VERSION "dbc-export 1 2026.26.6.5"

NS_ :

BS_:

BU_: APP APS BMS CC CMP CMPD CP DAS DI DIF DIR EPBL EPBR EVSE FC GTW HCML HCMR HVP ICR PCS PCS2 PLG PM PMF PMR PTC SCCM SCM SCS SDCR TAS UMC V2G VC VCBATT VCBATT0 VCBATT1 VCBATT2 VCFRONT VCFRONT1 VCFRONT2 VCLEFT VCRIGHT VCSEC

BO_ 852 TAS_alertMatrix: 8 TAS
 SG_ TAS_matrixIndex M : 0|4@1+ (1,0) [0|15] "" Vector__XXX
 SG_ TAS_a001_WatchdogReset m0 : 4|1@1+ (1,0) [0|1] "" Vector__XXX
 SG_ TAS_a002_PowerLossReset m0 : 5|1@1+ (1,0) [0|1] "" Vector__XXX
 SG_ TAS_a003_SWAssertion m0 : 6|1@1+ (1,0) [0|1] "" Vector__XXX
 SG_ TAS_a012_CPUReset m0 : 15|1@1+ (1,0) [0|1] "" Vector__XXX
 SG_ TAS_a015_NVMMError m0 : 18|1@1+ (1,0) [0|1] "" Vector__XXX
 SG_ TAS_a016_NVMMRecordError m0 : 19|1@1+ (1,0) [0|1] "" Vector__XXX
 SG_ TAS_a021_TaskSchedulerError m0 : 24|1@1+ (1,0) [0|1] "" Vector__XXX
 SG_ TAS_a022_TaskInitError m0 : 25|1@1+ (1,0) [0|1] "" Vector__XXX
 SG_ TAS_a023_rtosResetRequested m0 : 26|1@1+ (1,0) [0|1] "" Vector__XXX
 SG_ TAS_a024_prefetchAbort m0 : 27|1@1+ (1,0) [0|1] "" Vector__XXX
 SG_ TAS_a025_CrashEvent m0 : 28|1@1+ (1,0) [0|1] "" Vector__XXX
 SG_ TAS_a030_PWMerrorFL m0 : 33|1@1+ (1,0) [0|1] "" Vector__XXX
 SG_ TAS_a031_PWMerrorFR m0 : 34|1@1+ (1,0) [0|1] "" Vector__XXX
 SG_ TAS_a032_PWMerrorRL m0 : 35|1@1+ (1,0) [0|1] "" Vector__XXX
 SG_ TAS_a033_PWMerrorRR m0 : 36|1@1+ (1,0) [0|1] "" Vector__XXX
 SG_ TAS_a034_PWMshortFL m0 : 37|1@1+ (1,0) [0|1] "" Vector__XXX
 SG_ TAS_a035_PWMshortFR m0 : 38|1@1+ (1,0) [0|1] "" Vector__XXX
 SG_ TAS_a036_PWMshortRL m0 : 39|1@1+ (1,0) [0|1] "" Vector__XXX
 SG_ TAS_a037_PWMshortRR m0 : 40|1@1+ (1,0) [0|1] "" Vector__XXX
 SG_ TAS_a038_PWMopenFL m0 : 41|1@1+ (1,0) [0|1] "" Vector__XXX
 SG_ TAS_a039_PWMopenFR m0 : 42|1@1+ (1,0) [0|1] "" Vector__XXX
 SG_ TAS_a040_PWMopenRL m0 : 43|1@1+ (1,0) [0|1] "" Vector__XXX
 SG_ TAS_a041_PWMopenRR m0 : 44|1@1+ (1,0) [0|1] "" Vector__XXX
 SG_ TAS_a043_Task1msError m0 : 46|1@1+ (1,0) [0|1] "" Vector__XXX
 SG_ TAS_a044_Task10msError m0 : 47|1@1+ (1,0) [0|1] "" Vector__XXX
 SG_ TAS_a045_Task100msError m0 : 48|1@1+ (1,0) [0|1] "" Vector__XXX
 SG_ TAS_a046_Task1000msError m0 : 49|1@1+ (1,0) [0|1] "" Vector__XXX
 SG_ TAS_a061_XCPConnected m1 : 4|1@1+ (1,0) [0|1] "" Vector__XXX
 SG_ TAS_a062_XCPWasConnected m1 : 5|1@1+ (1,0) [0|1] "" Vector__XXX
 SG_ TAS_a063_abortFault m1 : 6|1@1+ (1,0) [0|1] "" Vector__XXX
 SG_ TAS_a064_abortFaultExt m1 : 7|1@1+ (1,0) [0|1] "" Vector__XXX
 SG_ TAS_a065_ahbWriteFault m1 : 8|1@1+ (1,0) [0|1] "" Vector__XXX
 SG_ TAS_a066_undefinedInstructionAbo m1 : 9|1@1+ (1,0) [0|1] "" Vector__XXX
 SG_ TAS_a067_reservedHandlerAbort m1 : 10|1@1+ (1,0) [0|1] "" Vector__XXX
 SG_ TAS_a070_underVoltage12V m1 : 13|1@1+ (1,0) [0|1] "" Vector__XXX
 SG_ TAS_a071_overVoltage12V m1 : 14|1@1+ (1,0) [0|1] "" Vector__XXX
 SG_ TAS_a072_shortCircuit5VOnBoard m1 : 15|1@1+ (1,0) [0|1] "" Vector__XXX
 SG_ TAS_a073_underVoltage5VOnBoard m1 : 16|1@1+ (1,0) [0|1] "" Vector__XXX
 SG_ TAS_a074_shortCircuit5VOffBoard m1 : 17|1@1+ (1,0) [0|1] "" Vector__XXX
 SG_ TAS_a075_underVoltage5VOffBoard m1 : 18|1@1+ (1,0) [0|1] "" Vector__XXX
 SG_ TAS_a076_overVoltage5VOffBoard m1 : 19|1@1+ (1,0) [0|1] "" Vector__XXX
 SG_ TAS_a077_pressureSigVTooLow m1 : 20|1@1+ (1,0) [0|1] "" Vector__XXX
 SG_ TAS_a078_pressureSigVTooHigh m1 : 21|1@1+ (1,0) [0|1] "" Vector__XXX
 SG_ TAS_a080_shortCircuit5VHeight m1 : 23|1@1+ (1,0) [0|1] "" Vector__XXX
 SG_ TAS_a081_underVoltage5VHeight m1 : 24|1@1+ (1,0) [0|1] "" Vector__XXX
 SG_ TAS_a082_overVoltage5VHeight m1 : 25|1@1+ (1,0) [0|1] "" Vector__XXX
 SG_ TAS_a083_shortCircuit5VAnalog m1 : 26|1@1+ (1,0) [0|1] "" Vector__XXX
 SG_ TAS_a084_underVoltage5VAnalog m1 : 27|1@1+ (1,0) [0|1] "" Vector__XXX
 SG_ TAS_a085_overVoltage5VAnalog m1 : 28|1@1+ (1,0) [0|1] "" Vector__XXX
 SG_ TAS_a086_underVoltage12VSwtchd m1 : 29|1@1+ (1,0) [0|1] "" Vector__XXX
 SG_ TAS_a087_overVoltage12VSwtchd m1 : 30|1@1+ (1,0) [0|1] "" Vector__XXX
 SG_ TAS_a093_OTPError m1 : 36|1@1+ (1,0) [0|1] "" Vector__XXX
 SG_ TAS_a098_VCFRONT_MIA m1 : 41|1@1+ (1,0) [0|1] "" Vector__XXX
 SG_ TAS_a099_UI_MIA m1 : 42|1@1+ (1,0) [0|1] "" Vector__XXX
 SG_ TAS_a100_RCM_MIA m1 : 43|1@1+ (1,0) [0|1] "" Vector__XXX
 SG_ TAS_a101_ESP_MIA m1 : 44|1@1+ (1,0) [0|1] "" Vector__XXX
 SG_ TAS_a102_DI_MIA m1 : 45|1@1+ (1,0) [0|1] "" Vector__XXX
 SG_ TAS_a103_GTW_MIA m1 : 46|1@1+ (1,0) [0|1] "" Vector__XXX
 SG_ TAS_a105_ECUDebugMode m1 : 48|1@1+ (1,0) [0|1] "" Vector__XXX
 SG_ TAS_a106_HighCPULoad m1 : 49|1@1+ (1,0) [0|1] "" Vector__XXX
 SG_ TAS_a107_HighStackUsage m1 : 50|1@1+ (1,0) [0|1] "" Vector__XXX
 SG_ TAS_a150_accelAvgImplausible_FL_ m2 : 33|1@1+ (1,0) [0|1] "" Vector__XXX
 SG_ TAS_a151_accelAvgImplausible_FL_ m2 : 34|1@1+ (1,0) [0|1] "" Vector__XXX
 SG_ TAS_a152_accelAvgImplausible_FL_ m2 : 35|1@1+ (1,0) [0|1] "" Vector__XXX
 SG_ TAS_a153_accelAvgImplausible_FR_ m2 : 36|1@1+ (1,0) [0|1] "" Vector__XXX
 SG_ TAS_a154_accelAvgImplausible_FR_ m2 : 37|1@1+ (1,0) [0|1] "" Vector__XXX
 SG_ TAS_a155_accelAvgImplausible_FR_ m2 : 38|1@1+ (1,0) [0|1] "" Vector__XXX
 SG_ TAS_a156_accelAvgImplausible_RL_ m2 : 39|1@1+ (1,0) [0|1] "" Vector__XXX
 SG_ TAS_a157_accelAvgImplausible_RL_ m2 : 40|1@1+ (1,0) [0|1] "" Vector__XXX
 SG_ TAS_a158_accelAvgImplausible_RL_ m2 : 41|1@1+ (1,0) [0|1] "" Vector__XXX
 SG_ TAS_a159_accelAvgImplausible_RR_ m2 : 42|1@1+ (1,0) [0|1] "" Vector__XXX
 SG_ TAS_a160_accelAvgImplausible_RR_ m2 : 43|1@1+ (1,0) [0|1] "" Vector__XXX
 SG_ TAS_a161_accelAvgImplausible_RR_ m2 : 44|1@1+ (1,0) [0|1] "" Vector__XXX
 SG_ TAS_a164_damperSolenoidMismatch m2 : 47|1@1+ (1,0) [0|1] "" Vector__XXX
 SG_ TAS_a165_damperValveCompFL m2 : 48|1@1+ (1,0) [0|1] "" Vector__XXX
 SG_ TAS_a166_damperValveRbndFL m2 : 49|1@1+ (1,0) [0|1] "" Vector__XXX
 SG_ TAS_a167_damperValveCompFR m2 : 50|1@1+ (1,0) [0|1] "" Vector__XXX
 SG_ TAS_a168_damperValveRbndFR m2 : 51|1@1+ (1,0) [0|1] "" Vector__XXX
 SG_ TAS_a169_damperValveCompRL m2 : 52|1@1+ (1,0) [0|1] "" Vector__XXX
 SG_ TAS_a170_damperValveRbndRL m2 : 53|1@1+ (1,0) [0|1] "" Vector__XXX
 SG_ TAS_a171_damperValveCompRR m2 : 54|1@1+ (1,0) [0|1] "" Vector__XXX
 SG_ TAS_a172_damperValveRbndRR m2 : 55|1@1+ (1,0) [0|1] "" Vector__XXX
 SG_ TAS_a173_staticLeakDetectFL m2 : 56|1@1+ (1,0) [0|1] "" Vector__XXX
 SG_ TAS_a174_staticLeakDetectFR m2 : 57|1@1+ (1,0) [0|1] "" Vector__XXX
 SG_ TAS_a175_staticLeakDetectRL m2 : 58|1@1+ (1,0) [0|1] "" Vector__XXX
 SG_ TAS_a176_staticLeakDetectRR m2 : 59|1@1+ (1,0) [0|1] "" Vector__XXX
 SG_ TAS_a190_a2bFrontAxleFault m3 : 13|1@1+ (1,0) [0|1] "" Vector__XXX
 SG_ TAS_a191_a2bRearAxleFault m3 : 14|1@1+ (1,0) [0|1] "" Vector__XXX
 SG_ TAS_a192_rideHeightObserverDiver m3 : 15|1@1+ (1,0) [0|1] "" Vector__XXX
 SG_ TAS_a193_EPAS3P_MIA m3 : 16|1@1+ (1,0) [0|1] "" Vector__XXX
 SG_ TAS_a194_a2bFrontAxleDataError m3 : 17|1@1+ (1,0) [0|1] "" Vector__XXX
 SG_ TAS_a195_a2bRearAxleDataError m3 : 18|1@1+ (1,0) [0|1] "" Vector__XXX
 SG_ TAS_a196_adaptiveDampingUsingDSP m3 : 19|1@1+ (1,0) [0|1] "" Vector__XXX
 SG_ TAS_a197_invalidAdaptiveModeRequ m3 : 20|1@1+ (1,0) [0|1] "" Vector__XXX
 SG_ TAS_a198_a2bFrontAxleExtendedDis m3 : 21|1@1+ (1,0) [0|1] "" Vector__XXX
 SG_ TAS_a199_a2bRearAxleExtendedDisc m3 : 22|1@1+ (1,0) [0|1] "" Vector__XXX
 SG_ TAS_a200_jackModeActive m3 : 23|1@1+ (1,0) [0|1] "" Vector__XXX
 SG_ TAS_a201_low12VBattery m3 : 24|1@1+ (1,0) [0|1] "" Vector__XXX
 SG_ TAS_a210_outOfRangeCalibration m3 : 33|1@1+ (1,0) [0|1] "" Vector__XXX
 SG_ TAS_a211_noRideHeightCalib m3 : 34|1@1+ (1,0) [0|1] "" Vector__XXX
 SG_ TAS_a213_yellowWarningLamp m3 : 36|1@1+ (1,0) [0|1] "" Vector__XXX
 SG_ TAS_a214_redWarningLamp m3 : 37|1@1+ (1,0) [0|1] "" Vector__XXX
 SG_ TAS_a215_limpHomeMode10 m3 : 38|1@1+ (1,0) [0|1] "" Vector__XXX
 SG_ TAS_a216_limpHomeMode20 m3 : 39|1@1+ (1,0) [0|1] "" Vector__XXX
 SG_ TAS_a217_limpHomeMode30 m3 : 40|1@1+ (1,0) [0|1] "" Vector__XXX
 SG_ TAS_a218_limpHomeMode40 m3 : 41|1@1+ (1,0) [0|1] "" Vector__XXX
 SG_ TAS_a220_exhaustGalleryFault m3 : 43|1@1+ (1,0) [0|1] "" Vector__XXX
 SG_ TAS_a221_valveLeakDetected m3 : 44|1@1+ (1,0) [0|1] "" Vector__XXX
 SG_ TAS_a222_compressorPrefillFault m3 : 45|1@1+ (1,0) [0|1] "" Vector__XXX
 SG_ TAS_a223_blockedAirline m3 : 46|1@1+ (1,0) [0|1] "" Vector__XXX
 SG_ TAS_a224_openAirline m3 : 47|1@1+ (1,0) [0|1] "" Vector__XXX
 SG_ TAS_a225_galleryPressureTooHigh m3 : 48|1@1+ (1,0) [0|1] "" Vector__XXX
 SG_ TAS_a226_PWMfastDetectFL m3 : 49|1@1+ (1,0) [0|1] "" Vector__XXX
 SG_ TAS_a227_PWMfastDetectFR m3 : 50|1@1+ (1,0) [0|1] "" Vector__XXX
 SG_ TAS_a228_PWMfastDetectRL m3 : 51|1@1+ (1,0) [0|1] "" Vector__XXX
 SG_ TAS_a229_PWMfastDetectRR m3 : 52|1@1+ (1,0) [0|1] "" Vector__XXX
 SG_ TAS_a230_notifyGeofence m3 : 53|1@1+ (1,0) [0|1] "" Vector__XXX
 SG_ TAS_a231_notifyRoughRoadRaise m3 : 54|1@1+ (1,0) [0|1] "" Vector__XXX
 SG_ TAS_a232_suspensionTypeMismatch m3 : 55|1@1+ (1,0) [0|1] "" Vector__XXX
 SG_ TAS_a233_compressorStuckOn m3 : 56|1@1+ (1,0) [0|1] "" Vector__XXX
 SG_ TAS_a234_damperHydraulicMismatch m3 : 57|1@1+ (1,0) [0|1] "" Vector__XXX
 SG_ TAS_a240_airSpringLeak m3 : 63|1@1+ (1,0) [0|1] "" Vector__XXX
 SG_ TAS_a284_serviceRunModeActive m4 : 47|1@1+ (1,0) [0|1] "" Vector__XXX
 SG_ TAS_a285_twistSustainedUserVis m4 : 48|1@1+ (1,0) [0|1] "" Vector__XXX
 SG_ TAS_a286_driveCycleStats1 m4 : 49|1@1+ (1,0) [0|1] "" Vector__XXX
 SG_ TAS_a287_driveCycleStats2 m4 : 50|1@1+ (1,0) [0|1] "" Vector__XXX
 SG_ TAS_a288_driveCycleStats3 m4 : 51|1@1+ (1,0) [0|1] "" Vector__XXX
 SG_ TAS_a289_driveCycleStats4 m4 : 52|1@1+ (1,0) [0|1] "" Vector__XXX
 SG_ TAS_a290_twistSustainedAtSpeed m4 : 53|1@1+ (1,0) [0|1] "" Vector__XXX
 SG_ TAS_a291_frontAxleTooHigh m4 : 54|1@1+ (1,0) [0|1] "" Vector__XXX
 SG_ TAS_a292_rearAxleTooHigh m4 : 55|1@1+ (1,0) [0|1] "" Vector__XXX
 SG_ TAS_a293_frontAxleTooLow m4 : 56|1@1+ (1,0) [0|1] "" Vector__XXX
 SG_ TAS_a294_rearAxleTooLow m4 : 57|1@1+ (1,0) [0|1] "" Vector__XXX
 SG_ TAS_a295_targetHeightNotMet m4 : 58|1@1+ (1,0) [0|1] "" Vector__XXX
 SG_ TAS_a296_chassisTypeMismatch m4 : 59|1@1+ (1,0) [0|1] "" Vector__XXX
 SG_ TAS_a297_vinMismatch m4 : 60|1@1+ (1,0) [0|1] "" Vector__XXX
 SG_ TAS_a298_vinNotLearned m4 : 61|1@1+ (1,0) [0|1] "" Vector__XXX
 SG_ TAS_a299_offsetEstimateTooLarge m4 : 62|1@1+ (1,0) [0|1] "" Vector__XXX
 SG_ TAS_a300_offsetEstimateData1 m4 : 63|1@1+ (1,0) [0|1] "" Vector__XXX
 SG_ TAS_a301_offsetEstimateData2 m5 : 4|1@1+ (1,0) [0|1] "" Vector__XXX
 SG_ TAS_a303_massEstimateFrozen m5 : 6|1@1+ (1,0) [0|1] "" Vector__XXX
 SG_ TAS_a304_massEstimateFrozenData m5 : 7|1@1+ (1,0) [0|1] "" Vector__XXX
 SG_ TAS_a305_newEndstopPosition m5 : 8|1@1+ (1,0) [0|1] "" Vector__XXX
 SG_ TAS_a306_hardwareProtectFrozen m5 : 9|1@1+ (1,0) [0|1] "" Vector__XXX
 SG_ TAS_a307_endstopBoundaryComp m5 : 10|1@1+ (1,0) [0|1] "" Vector__XXX
 SG_ TAS_a308_endstopBoundaryRbnd m5 : 11|1@1+ (1,0) [0|1] "" Vector__XXX
 SG_ TAS_a309_controlFrozen m5 : 12|1@1+ (1,0) [0|1] "" Vector__XXX
 SG_ TAS_a310_controlFrozenData m5 : 13|1@1+ (1,0) [0|1] "" Vector__XXX
 SG_ TAS_a311_accelsMIA m5 : 14|1@1+ (1,0) [0|1] "" Vector__XXX
 SG_ TAS_a312_rotationalRatesMIA m5 : 15|1@1+ (1,0) [0|1] "" Vector__XXX
 SG_ TAS_a313_dampingCntrlDisabled m5 : 16|1@1+ (1,0) [0|1] "" Vector__XXX
 SG_ TAS_a314_dampingReduced m5 : 17|1@1+ (1,0) [0|1] "" Vector__XXX
 SG_ TAS_a315_pcbaHighTemp m5 : 18|1@1+ (1,0) [0|1] "" Vector__XXX
 SG_ TAS_a316_offsetsAccels m5 : 19|1@1+ (1,0) [0|1] "" Vector__XXX
 SG_ TAS_a317_offsetsRotationalRates m5 : 20|1@1+ (1,0) [0|1] "" Vector__XXX
 SG_ TAS_a318_dampingCntrlInputMIA m5 : 21|1@1+ (1,0) [0|1] "" Vector__XXX
 SG_ TAS_a319_drivetrainTypeMismatch m5 : 22|1@1+ (1,0) [0|1] "" Vector__XXX
 SG_ TAS_a320_offsetsRotationalRates m5 : 23|1@1+ (1,0) [0|1] "" Vector__XXX
 SG_ TAS_a321_speedBumpAttributes1 m5 : 24|1@1+ (1,0) [0|1] "" Vector__XXX
 SG_ TAS_a322_speedBumpAttributes2 m5 : 25|1@1+ (1,0) [0|1] "" Vector__XXX
 SG_ TAS_a332_levelingThresholds1 m5 : 35|1@1+ (1,0) [0|1] "" Vector__XXX
 SG_ TAS_a333_levelingThresholds2 m5 : 36|1@1+ (1,0) [0|1] "" Vector__XXX
 SG_ TAS_a343_damperValveControlCompF m5 : 46|1@1+ (1,0) [0|1] "" Vector__XXX
 SG_ TAS_a344_damperValveControlRbndF m5 : 47|1@1+ (1,0) [0|1] "" Vector__XXX
 SG_ TAS_a345_damperValveControlCompF m5 : 48|1@1+ (1,0) [0|1] "" Vector__XXX
 SG_ TAS_a346_damperValveControlRbndF m5 : 49|1@1+ (1,0) [0|1] "" Vector__XXX
 SG_ TAS_a347_damperValveControlCompR m5 : 50|1@1+ (1,0) [0|1] "" Vector__XXX
 SG_ TAS_a348_damperValveControlRbndR m5 : 51|1@1+ (1,0) [0|1] "" Vector__XXX
 SG_ TAS_a349_damperValveControlCompR m5 : 52|1@1+ (1,0) [0|1] "" Vector__XXX
 SG_ TAS_a350_damperValveControlRbndR m5 : 53|1@1+ (1,0) [0|1] "" Vector__XXX

BO_ 523 TAS_axleData: 8 TAS
 SG_ TAS_axleIndex M : 0|1@1+ (1,0) [0|1] "" Vector__XXX
 SG_ TAS_rawHeightFL m0 : 4|10@1+ (1,-512) [-512|510] "mm" Vector__XXX
 SG_ TAS_staticHeightEstimateFL m0 : 14|10@1+ (1,-512) [-512|510] "mm" Vector__XXX
 SG_ TAS_componentPressureFL m0 : 24|8@1+ (0.1,0) [0|25.4] "bara" Vector__XXX
 SG_ TAS_rawHeightFR m0 : 32|10@1+ (1,-512) [-512|510] "mm" Vector__XXX
 SG_ TAS_staticHeightEstimateFR m0 : 42|10@1+ (1,-512) [-512|510] "mm" Vector__XXX
 SG_ TAS_componentPressureFR m0 : 52|8@1+ (0.1,0) [0|25.4] "bara" Vector__XXX
 SG_ TAS_rawHeightRL m1 : 4|10@1+ (1,-512) [-512|510] "mm" Vector__XXX
 SG_ TAS_staticHeightEstimateRL m1 : 14|10@1+ (1,-512) [-512|510] "mm" Vector__XXX
 SG_ TAS_componentPressureRL m1 : 24|8@1+ (0.1,0) [0|25.4] "bara" Vector__XXX
 SG_ TAS_rawHeightRR m1 : 32|10@1+ (1,-512) [-512|510] "mm" Vector__XXX
 SG_ TAS_staticHeightEstimateRR m1 : 42|10@1+ (1,-512) [-512|510] "mm" Vector__XXX
 SG_ TAS_componentPressureRR m1 : 52|8@1+ (0.1,0) [0|25.4] "bara" Vector__XXX

BO_ 1398 TAS_dampingStates: 8 TAS
 SG_ TAS_endstopState : 0|1@1+ (1,0) [0|1] "" Vector__XXX
 SG_ TAS_continuousControlState : 1|1@1+ (1,0) [0|1] "" Vector__XXX
 SG_ TAS_activeTireTune : 2|1@1+ (1,0) [0|1] "" Vector__XXX
 SG_ TAS_roughnessRaiseReason : 3|2@1+ (1,0) [0|3] "" Vector__XXX
 SG_ TAS_frontMetricDrivesRear : 5|2@1+ (1,0) [0|3] "" Vector__XXX
 SG_ TAS_roadCondition : 8|8@1+ (0.005,0) [0|1.27] "-" Vector__XXX
 SG_ TAS_bellyProtect : 16|2@1+ (1,0) [0|3] "" Vector__XXX
 SG_ TAS_frontMetricDrivesFront : 18|2@1+ (1,0) [0|3] "" Vector__XXX
 SG_ TAS_speedBumpAxleFront : 20|3@1+ (1,0) [0|7] "" Vector__XXX
 SG_ TAS_speedBumpAxleRear : 23|3@1+ (1,0) [0|7] "" Vector__XXX
 SG_ TAS_holeProtectFL : 26|2@1+ (1,0) [0|3] "" Vector__XXX
 SG_ TAS_holeProtectFR : 28|2@1+ (1,0) [0|3] "" Vector__XXX
 SG_ TAS_holeProtectRL : 30|2@1+ (1,0) [0|3] "" Vector__XXX
 SG_ TAS_holeProtectRR : 32|2@1+ (1,0) [0|3] "" Vector__XXX
 SG_ TAS_stepProtectFL : 34|2@1+ (1,0) [0|3] "" Vector__XXX
 SG_ TAS_stepProtectFR : 36|2@1+ (1,0) [0|3] "" Vector__XXX
 SG_ TAS_stepProtectRL : 38|2@1+ (1,0) [0|3] "" Vector__XXX
 SG_ TAS_stepProtectRR : 40|2@1+ (1,0) [0|3] "" Vector__XXX
 SG_ TAS_FDUTorqueCorruptionScale : 42|4@1+ (0.075,0) [0|1.05] "-" Vector__XXX
 SG_ TAS_sprungMassEstimate : 46|5@1+ (64,1800) [1800|3720] "kg" Vector__XXX
 SG_ TAS_anyDamperActive : 51|1@1+ (1,0) [0|1] "" Vector__XXX
 SG_ TAS_dampingStatesCounter : 52|4@1+ (1,0) [0|15] "" Vector__XXX
 SG_ TAS_dampingStatesChecksum : 56|8@1+ (1,0) [0|255] "" Vector__XXX

BO_ 1357 TAS_info: 8 TAS
 SG_ TAS_infoIndex M : 0|8@1+ (1,0) [0|255] "" Vector__XXX
 SG_ TAS_infoBuildType m10 : 8|8@1+ (1,0) [0|255] "" Vector__XXX
 SG_ TAS_infoBuildConfigId m10 : 16|16@1+ (1,0) [0|65535] "" Vector__XXX
 SG_ TAS_infoHardwareId m10 : 32|1@1+ (1,0) [0|1] "" Vector__XXX
 SG_ TAS_infoComponentId m10 : 48|16@1+ (1,0) [0|65535] "" Vector__XXX
 SG_ TAS_infoPcbaId m11 : 16|8@1+ (1,0) [0|255] "" Vector__XXX
 SG_ TAS_infoAssemblyId m11 : 24|8@1+ (1,0) [0|254] "" Vector__XXX
 SG_ TAS_infoUsageId m11 : 32|16@1+ (1,0) [0|65535] "" Vector__XXX
 SG_ TAS_infoSubUsageId m11 : 48|16@1+ (1,0) [0|65535] "" Vector__XXX
 SG_ TAS_infoAppCrc m13 : 32|32@1+ (1,0) [0|4294967295] "" Vector__XXX
 SG_ TAS_infoAppGitHash m17 : 8|56@1+ (1,0) [0|7.20575940379e+16] "" Vector__XXX
 SG_ TAS_infoBootGitHash m18 : 8|56@1+ (1,0) [0|7.20575940379e+16] "" Vector__XXX
 SG_ TAS_infoPlatformType m19 : 8|8@1+ (1,0) [0|255] "" Vector__XXX
 SG_ TAS_infoMajorVersion m19 : 16|8@1+ (1,0) [0|254] "" Vector__XXX
 SG_ TAS_infoBranchOrigin m19 : 24|8@1+ (1,0) [0|254] "" Vector__XXX
 SG_ TAS_infoMaturity m19 : 32|8@1+ (1,0) [0|254] "" Vector__XXX
 SG_ TAS_infoHardwareRevision m19 : 40|8@1+ (1,0) [0|254] "" Vector__XXX

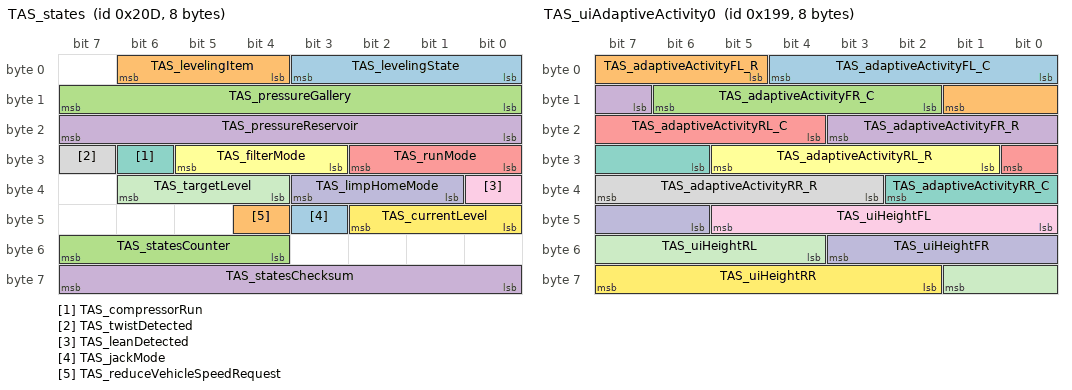
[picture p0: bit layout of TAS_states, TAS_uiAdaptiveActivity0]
BO_ 525 TAS_states: 8 TAS
 SG_ TAS_levelingState : 0|4@1+ (1,0) [0|15] "" Vector__XXX
 SG_ TAS_levelingItem : 4|3@1+ (1,0) [0|7] "" Vector__XXX
 SG_ TAS_pressureGallery : 8|8@1+ (0.1,0) [0|25.4] "bara" Vector__XXX
 SG_ TAS_pressureReservoir : 16|8@1+ (0.1,0) [0|25.4] "bara" Vector__XXX
 SG_ TAS_runMode : 24|3@1+ (1,0) [0|7] "" Vector__XXX
 SG_ TAS_filterMode : 27|3@1+ (1,0) [0|7] "" Vector__XXX
 SG_ TAS_compressorRun : 30|1@1+ (1,0) [0|1] "" Vector__XXX
 SG_ TAS_twistDetected : 31|1@1+ (1,0) [0|1] "" Vector__XXX
 SG_ TAS_leanDetected : 32|1@1+ (1,0) [0|1] "" Vector__XXX
 SG_ TAS_limpHomeMode : 33|3@1+ (1,0) [0|7] "" Vector__XXX
 SG_ TAS_targetLevel : 36|3@1+ (1,0) [0|7] "" Vector__XXX
 SG_ TAS_currentLevel : 40|3@1+ (1,0) [0|7] "" Vector__XXX
 SG_ TAS_jackMode : 43|1@1+ (1,0) [0|1] "" Vector__XXX
 SG_ TAS_reduceVehicleSpeedRequest : 44|1@1+ (1,0) [0|1] "" Vector__XXX
 SG_ TAS_statesCounter : 52|4@1+ (1,0) [0|15] "" Vector__XXX
 SG_ TAS_statesChecksum : 56|8@1+ (1,0) [0|255] "" Vector__XXX

BO_ 1627 TAS_udsResponse: 8 TAS
 SG_ TAS_udsResponseData : 7|64@0+ (1,0) [0|1.84467440737e+19] "" Vector__XXX

BO_ 409 TAS_uiAdaptiveActivity0: 8 TAS
 SG_ TAS_adaptiveActivityFL_C : 0|5@1+ (0.04,0) [0|1] "-" Vector__XXX
 SG_ TAS_adaptiveActivityFL_R : 5|5@1+ (0.04,0) [0|1] "-" Vector__XXX
 SG_ TAS_adaptiveActivityFR_C : 10|5@1+ (0.04,0) [0|1] "-" Vector__XXX
 SG_ TAS_adaptiveActivityFR_R : 15|5@1+ (0.04,0) [0|1] "-" Vector__XXX
 SG_ TAS_adaptiveActivityRL_C : 20|5@1+ (0.04,0) [0|1] "-" Vector__XXX
 SG_ TAS_adaptiveActivityRL_R : 25|5@1+ (0.04,0) [0|1] "-" Vector__XXX
 SG_ TAS_adaptiveActivityRR_C : 30|5@1+ (0.04,0) [0|1] "-" Vector__XXX
 SG_ TAS_adaptiveActivityRR_R : 35|5@1+ (0.04,0) [0|1] "-" Vector__XXX
 SG_ TAS_uiHeightFL : 40|6@1+ (4,-128) [-128|120] "mm" Vector__XXX
 SG_ TAS_uiHeightFR : 46|6@1+ (4,-128) [-128|120] "mm" Vector__XXX
 SG_ TAS_uiHeightRL : 52|6@1+ (4,-128) [-128|120] "mm" Vector__XXX
 SG_ TAS_uiHeightRR : 58|6@1+ (4,-128) [-128|120] "mm" Vector__XXX

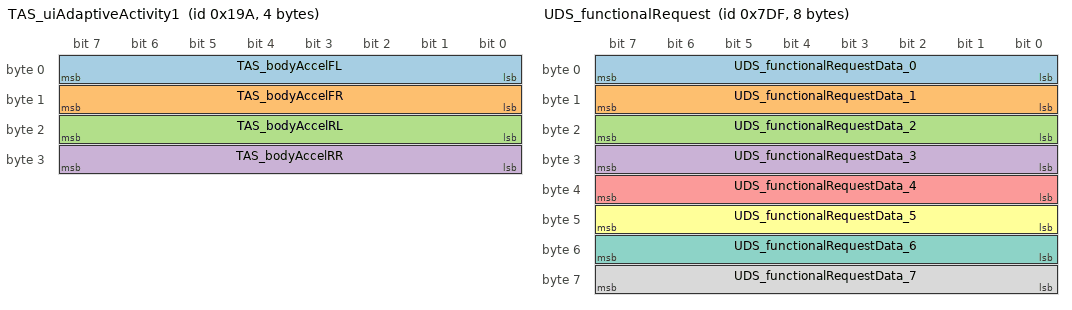
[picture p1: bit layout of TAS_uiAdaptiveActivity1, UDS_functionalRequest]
BO_ 410 TAS_uiAdaptiveActivity1: 4 TAS
 SG_ TAS_bodyAccelFL : 0|8@1+ (0.05,-5) [-5|5] "g" Vector__XXX
 SG_ TAS_bodyAccelFR : 8|8@1+ (0.05,-5) [-5|5] "g" Vector__XXX
 SG_ TAS_bodyAccelRL : 16|8@1+ (0.05,-5) [-5|5] "g" Vector__XXX
 SG_ TAS_bodyAccelRR : 24|8@1+ (0.05,-5) [-5|5] "g" Vector__XXX

BO_ 538 TAS_uiControl: 5 TAS
 SG_ TAS_yellowWarningLamp : 0|1@1+ (1,0) [0|1] "" Vector__XXX
 SG_ TAS_redWarningLamp : 1|1@1+ (1,0) [0|1] "" Vector__XXX
 SG_ TAS_veryLowAllowed : 2|1@1+ (1,0) [0|1] "" Vector__XXX
 SG_ TAS_lowAllowed : 3|1@1+ (1,0) [0|1] "" Vector__XXX
 SG_ TAS_standardAllowed : 4|1@1+ (1,0) [0|1] "" Vector__XXX
 SG_ TAS_highAllowed : 5|1@1+ (1,0) [0|1] "" Vector__XXX
 SG_ TAS_veryHighAllowed : 6|1@1+ (1,0) [0|1] "" Vector__XXX
 SG_ TAS_extractAllowed : 7|1@1+ (1,0) [0|1] "" Vector__XXX
 SG_ TAS_showSpinner : 9|1@1+ (1,0) [0|1] "" Vector__XXX
 SG_ TAS_adaptiveRideModeOverride : 10|2@1+ (1,0) [0|2] "" Vector__XXX
 SG_ TAS_levelSelectEnabled : 12|1@1+ (1,0) [0|1] "" Vector__XXX
 SG_ TAS_jackModeToggleEnabled : 13|1@1+ (1,0) [0|1] "" Vector__XXX
 SG_ TAS_adaptiveRideSelectEnabled : 14|1@1+ (1,0) [0|1] "" Vector__XXX
 SG_ TAS_launchModeState : 16|3@1+ (1,0) [0|7] "" Vector__XXX
 SG_ TAS_restrictUpLevelingFalcons : 19|1@1+ (1,0) [0|1] "" Vector__XXX
 SG_ TAS_restrictUpLevelingTrunk : 20|1@1+ (1,0) [0|1] "" Vector__XXX
 SG_ TAS_restrictDownLevelingDoors : 21|1@1+ (1,0) [0|1] "" Vector__XXX
 SG_ TAS_restrictLevelingChargeCable : 22|1@1+ (1,0) [0|1] "" Vector__XXX
 SG_ TAS_restrictLevelingSystemCheck : 23|1@1+ (1,0) [0|1] "" Vector__XXX
 SG_ TAS_restrictLevelingTransport : 24|1@1+ (1,0) [0|1] "" Vector__XXX
 SG_ TAS_restrictLevelingShowroom : 25|1@1+ (1,0) [0|1] "" Vector__XXX
 SG_ TAS_uiControlCounter : 28|4@1+ (1,0) [0|15] "" Vector__XXX
 SG_ TAS_uiControlChecksum : 32|8@1+ (1,0) [0|255] "" Vector__XXX

BO_ 1641 UDS_KOSTIAsccmRequest: 8 GTW
 SG_ UDS_KOSTIAsccmRequestData : 7|64@0+ (1,0) [0|1.84467440737e+19] "" Vector__XXX

BO_ 1538 UDS_bmsRequest: 8 GTW
 SG_ UDS_bmsRequestData : 7|64@0+ (1,0) [0|1.84467440737e+19] "" Vector__XXX

BO_ 1579 UDS_ccRequest: 8 GTW
 SG_ UDS_ccRequestData : 7|64@0+ (1,0) [0|1.84467440737e+19] "" Vector__XXX

BO_ 1539 UDS_cmpRequest: 8 GTW
 SG_ UDS_cmpRequestData : 7|64@0+ (1,0) [0|1.84467440737e+19] "" Vector__XXX

BO_ 1543 UDS_cmpdRequest: 8 GTW
 SG_ UDS_cmpdRequestData : 7|64@0+ (1,0) [0|1.84467440737e+19] "" Vector__XXX

BO_ 1550 UDS_cpRequest: 8 GTW
 SG_ UDS_cpRequestData : 7|64@0+ (1,0) [0|1.84467440737e+19] "" Vector__XXX

BO_ 1589 UDS_diRequest: 8 GTW
 SG_ UDS_diRequestData : 7|64@0+ (1,0) [0|1.84467440737e+19] "" Vector__XXX

BO_ 1541 UDS_difRequest: 8 GTW
 SG_ UDS_difRequestData : 7|64@0+ (1,0) [0|1.84467440737e+19] "" Vector__XXX

BO_ 1542 UDS_dirRequest: 8 GTW
 SG_ UDS_dirRequestData : 7|64@0+ (1,0) [0|1.84467440737e+19] "" Vector__XXX

BO_ 1572 UDS_epblRequest: 8 GTW
 SG_ UDS_epblRequestData_H : 7|32@0+ (1,0) [0|4294967295] "" Vector__XXX
 SG_ UDS_epblRequestData_L : 39|32@0+ (1,0) [0|4294967295] "" Vector__XXX

BO_ 1574 UDS_epbrRequest: 8 GTW
 SG_ UDS_epbrRequestData_H : 7|32@0+ (1,0) [0|4294967295] "" Vector__XXX
 SG_ UDS_epbrRequestData_L : 39|32@0+ (1,0) [0|4294967295] "" Vector__XXX

BO_ 2015 UDS_functionalRequest: 8 GTW
 SG_ UDS_functionalRequestData_0 : 7|8@0+ (1,0) [0|255] "" Vector__XXX
 SG_ UDS_functionalRequestData_1 : 15|8@0+ (1,0) [0|255] "" Vector__XXX
 SG_ UDS_functionalRequestData_2 : 23|8@0+ (1,0) [0|255] "" Vector__XXX
 SG_ UDS_functionalRequestData_3 : 31|8@0+ (1,0) [0|255] "" Vector__XXX
 SG_ UDS_functionalRequestData_4 : 39|8@0+ (1,0) [0|255] "" Vector__XXX
 SG_ UDS_functionalRequestData_5 : 47|8@0+ (1,0) [0|255] "" Vector__XXX
 SG_ UDS_functionalRequestData_6 : 55|8@0+ (1,0) [0|255] "" Vector__XXX
 SG_ UDS_functionalRequestData_7 : 63|8@0+ (1,0) [0|255] "" Vector__XXX

BO_ 1552 UDS_hvpRequest: 8 GTW
 SG_ UDS_hvpRequestData : 7|64@0+ (1,0) [0|1.84467440737e+19] "" Vector__XXX

BO_ 1560 UDS_icrRequest: 8 GTW
 SG_ UDS_icrRequestData : 7|64@0+ (1,0) [0|1.84467440737e+19] "" Vector__XXX

BO_ 1576 UDS_pcsRequest: 8 GTW
 SG_ UDS_pcsRequestData : 7|64@0+ (1,0) [0|1.84467440737e+19] "" Vector__XXX

BO_ 1634 UDS_plgRequest: 8 GTW
 SG_ UDS_plgRequestData : 7|64@0+ (1,0) [0|1.84467440737e+19] "" Vector__XXX

BO_ 1568 UDS_pmRequest: 8 GTW
 SG_ UDS_pmRequestData : 7|64@0+ (1,0) [0|1.84467440737e+19] "" Vector__XXX

BO_ 1604 UDS_pmfRequest: 8 GTW
 SG_ UDS_pmfRequestData : 7|64@0+ (1,0) [0|1.84467440737e+19] "" Vector__XXX

BO_ 1540 UDS_pmrRequest: 8 GTW
 SG_ UDS_pmrRequestData : 7|64@0+ (1,0) [0|1.84467440737e+19] "" Vector__XXX

BO_ 1734 UDS_ptcRequest: 8 GTW
 SG_ UDS_ptcRequestData : 7|64@0+ (1,0) [0|1.84467440737e+19] "" Vector__XXX

BO_ 1664 UDS_sccmRequest: 8 GTW
 SG_ UDS_sccmRequestData : 7|64@0+ (1,0) [0|1.84467440737e+19] "" Vector__XXX

BO_ 1723 UDS_sdcrRequest: 8 GTW
 SG_ UDS_sdcrRequestData : 7|64@0+ (1,0) [0|1.84467440737e+19] "" Vector__XXX

BO_ 1611 UDS_tasRequest: 8 GTW
 SG_ UDS_tasRequestData : 7|64@0+ (1,0) [0|1.84467440737e+19] "" Vector__XXX

BO_ 1548 UDS_vcbatt1Request: 8 GTW
 SG_ UDS_vcbatt1RequestData : 7|64@0+ (1,0) [0|1.84467440737e+19] "" Vector__XXX

BO_ 1562 UDS_vcbatt2Request: 8 GTW
 SG_ UDS_vcbatt2RequestData : 7|64@0+ (1,0) [0|1.84467440737e+19] "" Vector__XXX

BO_ 1633 UDS_vcbattRequest: 8 GTW
 SG_ UDS_vcbattRequestData : 7|64@0+ (1,0) [0|1.84467440737e+19] "" Vector__XXX

BO_ 1580 UDS_vcfront1Request: 8 GTW
 SG_ UDS_vcfront1RequestData : 7|64@0+ (1,0) [0|1.84467440737e+19] "" Vector__XXX

BO_ 1582 UDS_vcfront2Request: 8 GTW
 SG_ UDS_vcfront2RequestData : 7|64@0+ (1,0) [0|1.84467440737e+19] "" Vector__XXX

BO_ 1536 UDS_vcfrontRequest: 8 GTW
 SG_ UDS_vcfrontRequestData : 7|64@0+ (1,0) [0|1.84467440737e+19] "" Vector__XXX

BO_ 1570 UDS_vcleftRequest: 8 GTW
 SG_ UDS_vcleftRequestData_H : 7|32@0+ (1,0) [0|4294967295] "" Vector__XXX
 SG_ UDS_vcleftRequestData_L : 39|32@0+ (1,0) [0|4294967295] "" Vector__XXX

BO_ 1544 UDS_vcrightRequest: 8 GTW
 SG_ UDS_vcrightRequestData_H : 7|32@0+ (1,0) [0|4294967295] "" Vector__XXX
 SG_ UDS_vcrightRequestData_L : 39|32@0+ (1,0) [0|4294967295] "" Vector__XXX

BO_ 1546 UDS_vcsecRequest: 8 GTW
 SG_ UDS_vcsecRequestData : 7|64@0+ (1,0) [0|1.84467440737e+19] "" Vector__XXX

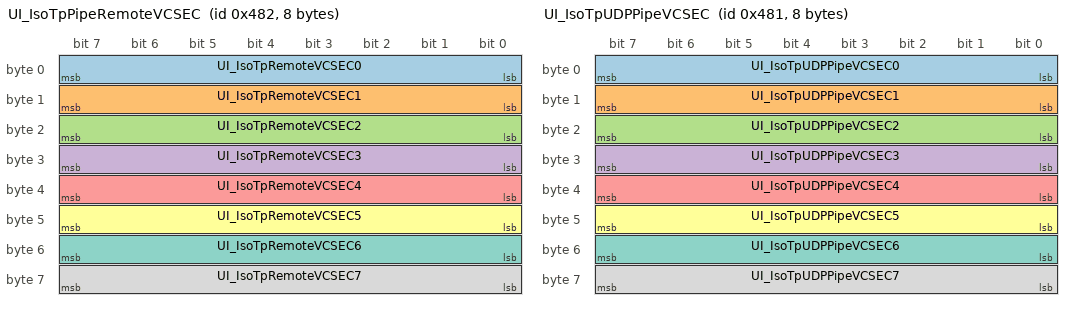
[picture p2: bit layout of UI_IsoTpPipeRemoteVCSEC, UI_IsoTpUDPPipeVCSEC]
BO_ 1154 UI_IsoTpPipeRemoteVCSEC: 8 GTW
 SG_ UI_IsoTpRemoteVCSEC0 : 0|8@1+ (1,0) [0|255] "" Vector__XXX
 SG_ UI_IsoTpRemoteVCSEC1 : 8|8@1+ (1,0) [0|255] "" Vector__XXX
 SG_ UI_IsoTpRemoteVCSEC2 : 16|8@1+ (1,0) [0|255] "" Vector__XXX
 SG_ UI_IsoTpRemoteVCSEC3 : 24|8@1+ (1,0) [0|255] "" Vector__XXX
 SG_ UI_IsoTpRemoteVCSEC4 : 32|8@1+ (1,0) [0|255] "" Vector__XXX
 SG_ UI_IsoTpRemoteVCSEC5 : 40|8@1+ (1,0) [0|255] "" Vector__XXX
 SG_ UI_IsoTpRemoteVCSEC6 : 48|8@1+ (1,0) [0|255] "" Vector__XXX
 SG_ UI_IsoTpRemoteVCSEC7 : 56|8@1+ (1,0) [0|255] "" Vector__XXX

BO_ 1153 UI_IsoTpUDPPipeVCSEC: 8 GTW
 SG_ UI_IsoTpUDPPipeVCSEC0 : 0|8@1+ (1,0) [0|255] "" Vector__XXX
 SG_ UI_IsoTpUDPPipeVCSEC1 : 8|8@1+ (1,0) [0|255] "" Vector__XXX
 SG_ UI_IsoTpUDPPipeVCSEC2 : 16|8@1+ (1,0) [0|255] "" Vector__XXX
 SG_ UI_IsoTpUDPPipeVCSEC3 : 24|8@1+ (1,0) [0|255] "" Vector__XXX
 SG_ UI_IsoTpUDPPipeVCSEC4 : 32|8@1+ (1,0) [0|255] "" Vector__XXX
 SG_ UI_IsoTpUDPPipeVCSEC5 : 40|8@1+ (1,0) [0|255] "" Vector__XXX
 SG_ UI_IsoTpUDPPipeVCSEC6 : 48|8@1+ (1,0) [0|255] "" Vector__XXX
 SG_ UI_IsoTpUDPPipeVCSEC7 : 56|8@1+ (1,0) [0|255] "" Vector__XXX

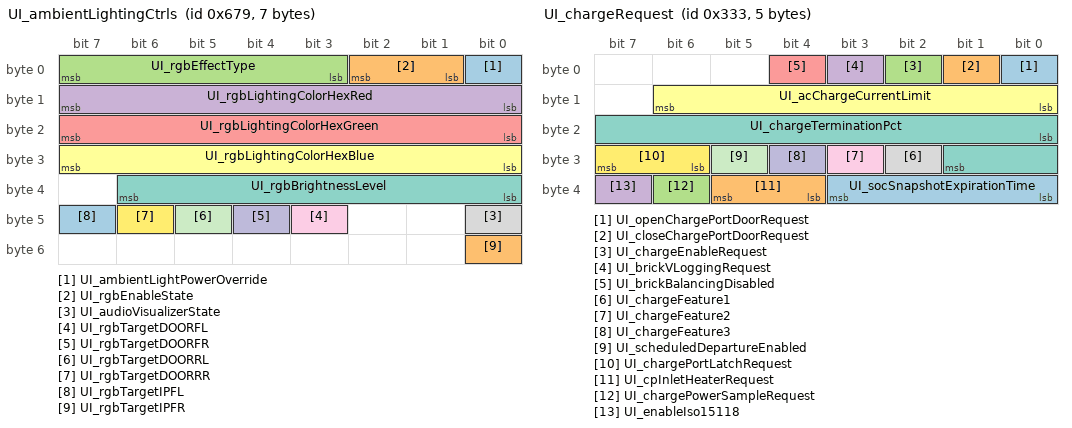
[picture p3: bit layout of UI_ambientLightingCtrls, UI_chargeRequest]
BO_ 1657 UI_ambientLightingCtrls: 7 GTW
 SG_ UI_ambientLightPowerOverride : 0|1@1+ (1,0) [0|1] "" Vector__XXX
 SG_ UI_rgbEnableState : 1|2@1+ (1,0) [0|3] "" Vector__XXX
 SG_ UI_rgbEffectType : 3|5@1+ (1,0) [0|31] "" Vector__XXX
 SG_ UI_rgbLightingColorHexRed : 8|8@1+ (1,0) [0|255] "" Vector__XXX
 SG_ UI_rgbLightingColorHexGreen : 16|8@1+ (1,0) [0|255] "" Vector__XXX
 SG_ UI_rgbLightingColorHexBlue : 24|8@1+ (1,0) [0|255] "" Vector__XXX
 SG_ UI_rgbBrightnessLevel : 32|7@1+ (1,0) [0|100] "%" Vector__XXX
 SG_ UI_audioVisualizerState : 40|1@1+ (1,0) [0|1] "" Vector__XXX
 SG_ UI_rgbTargetDOORFL : 43|1@1+ (1,0) [0|1] "" Vector__XXX
 SG_ UI_rgbTargetDOORFR : 44|1@1+ (1,0) [0|1] "" Vector__XXX
 SG_ UI_rgbTargetDOORRL : 45|1@1+ (1,0) [0|1] "" Vector__XXX
 SG_ UI_rgbTargetDOORRR : 46|1@1+ (1,0) [0|1] "" Vector__XXX
 SG_ UI_rgbTargetIPFL : 47|1@1+ (1,0) [0|1] "" Vector__XXX
 SG_ UI_rgbTargetIPFR : 48|1@1+ (1,0) [0|1] "" Vector__XXX

BO_ 1021 UI_autopilotControl: 8 GTW
 SG_ UI_autopilotControlIndex M : 0|3@1+ (1,0) [0|7] "" Vector__XXX
 SG_ UI_hovEnabled m0 : 3|1@1+ (1,0) [0|1] "" Vector__XXX
 SG_ UI_donDisableAutoWiperDuration m0 : 4|3@1+ (1,0) [0|7] "" Vector__XXX
 SG_ UI_donDisableOnAutoWiperSpeed m0 : 7|4@1+ (1,0) [0|15] "" Vector__XXX
 SG_ UI_blindspotMinSpeed m0 : 11|4@1+ (1,0) [0|15] "" Vector__XXX
 SG_ UI_blindspotDistance m0 : 15|3@1+ (1,0) [0|7] "" Vector__XXX
 SG_ UI_blindspotTTC m0 : 18|3@1+ (1,0) [0|7] "" Vector__XXX
 SG_ UI_donStopEndOfRampBuffer m0 : 21|3@1+ (1,0) [0|7] "" Vector__XXX
 SG_ UI_donDisableCutin m0 : 24|1@1+ (1,0) [0|1] "" Vector__XXX
 SG_ UI_smartSetSpeedOffset m0 : 25|6@1+ (1,-30) [-30|33] "%" Vector__XXX
 SG_ UI_smartSetSpeedOffsetType m0 : 31|1@1+ (1,0) [0|1] "" Vector__XXX
 SG_ UI_autopilotMonarchBackup m0 : 32|1@1+ (1,0) [0|1] "" Vector__XXX
 SG_ UI_fsdVisualizationEnabled m0 : 37|1@1+ (1,0) [0|1] "" Vector__XXX
 SG_ UI_fsdStopsControlEnabled m0 : 38|1@1+ (1,0) [0|1] "" Vector__XXX
 SG_ UI_fsdContinueOnGreenWithCIPV m0 : 39|1@1+ (1,0) [0|1] "" Vector__XXX
 SG_ UI_smartSetSpeed m0 : 40|1@1+ (1,0) [0|1] "" Vector__XXX
 SG_ UI_automaticSetSpeedOffset m0 : 41|1@1+ (1,0) [0|1] "" Vector__XXX
 SG_ UI_apply2021_1958_ISA m0 : 42|1@1+ (1,0) [0|1] "" Vector__XXX
 SG_ UI_apply2021_646_ELKS m0 : 43|1@1+ (1,0) [0|1] "" Vector__XXX
 SG_ UI_apply2021_1341_DDAW m0 : 44|1@1+ (1,0) [0|1] "" Vector__XXX
 SG_ UI_homelinkNearby m0 : 45|1@1+ (1,0) [0|1] "" Vector__XXX
 SG_ UI_enableFullSelfDriving m0 : 46|1@1+ (1,0) [0|1] "" Vector__XXX
 SG_ UI_hasFullSelfDriving m0 : 47|1@1+ (1,0) [0|1] "" Vector__XXX
 SG_ UI_autosteerActivation m0 : 48|1@1+ (1,0) [0|1] "" Vector__XXX
 SG_ UI_fsdBetaRequest m0 : 51|1@1+ (1,0) [0|1] "" Vector__XXX
 SG_ UI_fullSelfDrivingSuspended m0 : 52|1@1+ (1,0) [0|1] "" Vector__XXX
 SG_ UI_disableOptionalLaneChanges m0 : 53|1@1+ (1,0) [0|1] "" Vector__XXX
 SG_ UI_applyR152_AEBS m0 : 59|1@1+ (1,0) [0|1] "" Vector__XXX
 SG_ UI_applyDCASBehavior m0 : 60|1@1+ (1,0) [0|1] "" Vector__XXX
 SG_ UI_applyDCASBehaviorLegacy m0 : 61|1@1+ (1,0) [0|1] "" Vector__XXX
 SG_ UI_applyADDWWarnings m0 : 62|1@1+ (1,0) [0|1] "" Vector__XXX
 SG_ UI_autopilotControlMux0Valid m0 : 63|1@1+ (1,0) [0|1] "" Vector__XXX
 SG_ UI_selectableCameraRequest m1 : 8|4@1+ (1,0) [0|14] "" Vector__XXX
 SG_ UI_overrideSleepWithSuspend m1 : 16|1@1+ (1,0) [0|1] "" Vector__XXX
 SG_ UI_driverMonitorConfirmation m1 : 17|1@1+ (1,0) [0|1] "" Vector__XXX
 SG_ UI_parkAssistUseVision m1 : 18|1@1+ (1,0) [0|1] "" Vector__XXX
 SG_ UI_applyEceR79 m1 : 19|1@1+ (1,0) [0|1] "" Vector__XXX
 SG_ UI_enableMapStops m1 : 20|1@1+ (1,0) [0|1] "" Vector__XXX
 SG_ UI_disableMain m1 : 23|1@1+ (1,0) [0|1] "" Vector__XXX
 SG_ UI_disableNarrow m1 : 24|1@1+ (1,0) [0|1] "" Vector__XXX
 SG_ UI_disableFisheye m1 : 25|1@1+ (1,0) [0|1] "" Vector__XXX
 SG_ UI_disableLeftPillar m1 : 26|1@1+ (1,0) [0|1] "" Vector__XXX
 SG_ UI_disableRightPillar m1 : 27|1@1+ (1,0) [0|1] "" Vector__XXX
 SG_ UI_disableLeftRepeater m1 : 28|1@1+ (1,0) [0|1] "" Vector__XXX
 SG_ UI_disableRightRepeater m1 : 29|1@1+ (1,0) [0|1] "" Vector__XXX
 SG_ UI_disableBackup m1 : 30|1@1+ (1,0) [0|1] "" Vector__XXX
 SG_ UI_disableRadar m1 : 31|1@1+ (1,0) [0|1] "" Vector__XXX
 SG_ UI_noStalkConfirmAlertHaptic m1 : 32|1@1+ (1,0) [0|1] "" Vector__XXX
 SG_ UI_regulatoryLKA m1 : 33|1@1+ (1,0) [0|1] "" Vector__XXX
 SG_ UI_regulatoryLaneAssistLevel m1 : 34|1@1+ (1,0) [0|1] "" Vector__XXX
 SG_ UI_ulcSnooze m1 : 36|1@1+ (1,0) [0|1] "" Vector__XXX
 SG_ UI_noStalkConfirmAlertChime m1 : 37|1@1+ (1,0) [0|1] "" Vector__XXX
 SG_ UI_factorySummonEnable m1 : 39|1@1+ (1,0) [0|1] "" Vector__XXX
 SG_ UI_apmv3Branch m1 : 40|3@1+ (1,0) [0|7] "" Vector__XXX
 SG_ UI_enableCabinCamera m1 : 43|1@1+ (1,0) [0|1] "" Vector__XXX
 SG_ UI_enableAutopilotStopWarning m1 : 44|1@1+ (1,0) [0|1] "" Vector__XXX
 SG_ UI_showLaneGraph m1 : 45|1@1+ (1,0) [0|1] "" Vector__XXX
 SG_ UI_showTrackLabels m1 : 46|1@1+ (1,0) [0|1] "" Vector__XXX
 SG_ UI_hardCoreSummon m1 : 47|1@1+ (1,0) [0|1] "" Vector__XXX
 SG_ UI_enableCabinCameraTelemetry m1 : 48|1@1+ (1,0) [0|1] "" Vector__XXX
 SG_ UI_enableVisionSpeedControl m1 : 49|1@1+ (1,0) [0|1] "" Vector__XXX
 SG_ UI_autopilotTelemetryInChina m1 : 50|1@1+ (1,0) [0|1] "" Vector__XXX
 SG_ UI_enableTeslaAutopark m1 : 51|1@1+ (1,0) [0|1] "" Vector__XXX
 SG_ UI_autoTurnSignalMode m1 : 52|1@1+ (1,0) [0|1] "" Vector__XXX
 SG_ UI_enableCautionLightControl m1 : 54|1@1+ (1,0) [0|1] "" Vector__XXX
 SG_ UI_applyEceR79SmartSummonOnly m1 : 55|1@1+ (1,0) [0|1] "" Vector__XXX
 SG_ UI_autopilotMonarchEnabled m1 : 56|1@1+ (1,0) [0|1] "" Vector__XXX
 SG_ UI_autopilotEphemerisEnabled m1 : 57|1@1+ (1,0) [0|1] "" Vector__XXX
 SG_ UI_enableCabinAudioRecording m1 : 59|1@1+ (1,0) [0|1] "" Vector__XXX
 SG_ UI_autopilotControlMux1Valid m1 : 63|1@1+ (1,0) [0|1] "" Vector__XXX
 SG_ UI_enableApproachingEmergencyVeh m2 : 5|1@1+ (1,0) [0|1] "" Vector__XXX
 SG_ UI_enableStartFsdFromParkBrakeCo m2 : 6|1@1+ (1,0) [0|1] "" Vector__XXX
 SG_ UI_enableStartFsdFromPark m2 : 7|1@1+ (1,0) [0|1] "" Vector__XXX
 SG_ UI_fsdMaxSpeedOffsetPercentage m2 : 8|6@1+ (1,0) [0|63] "%" Vector__XXX
 SG_ UI_calibrationReadyInFactory m2 : 15|1@1+ (1,0) [0|1] "" Vector__XXX
 SG_ UI_coldStartMonarchInFactory m2 : 16|1@1+ (1,0) [0|1] "" Vector__XXX
 SG_ UI_navMinutesToArrival m2 : 17|10@1+ (1,0) [0|1023] "minutes" Vector__XXX
 SG_ UI_fsdQuizRequired m2 : 27|1@1+ (1,0) [0|1] "" Vector__XXX
 SG_ UI_fsdQuizPassed m2 : 28|1@1+ (1,0) [0|1] "" Vector__XXX
 SG_ UI_fsdAllowedInLocalizedRegion m2 : 29|1@1+ (1,0) [0|1] "" Vector__XXX
 SG_ UI_autopilotDrivingProfile m2 : 60|3@1+ (1,0) [0|7] "" Vector__XXX
 SG_ UI_autopilotControlMux2Valid m2 : 63|1@1+ (1,0) [0|1] "" Vector__XXX

BO_ 819 UI_chargeRequest: 5 GTW
 SG_ UI_openChargePortDoorRequest : 0|1@1+ (1,0) [0|1] "" Vector__XXX
 SG_ UI_closeChargePortDoorRequest : 1|1@1+ (1,0) [0|1] "" Vector__XXX
 SG_ UI_chargeEnableRequest : 2|1@1+ (1,0) [0|1] "" Vector__XXX
 SG_ UI_brickVLoggingRequest : 3|1@1+ (1,0) [0|1] "" Vector__XXX
 SG_ UI_brickBalancingDisabled : 4|1@1+ (1,0) [0|1] "" Vector__XXX
 SG_ UI_acChargeCurrentLimit : 8|7@1+ (1,0) [0|126] "A" Vector__XXX
 SG_ UI_chargeTerminationPct : 16|10@1+ (0.1,0) [5|100] "%" Vector__XXX
 SG_ UI_chargeFeature1 : 26|1@1+ (1,0) [0|1] "" Vector__XXX
 SG_ UI_chargeFeature2 : 27|1@1+ (1,0) [0|1] "" Vector__XXX
 SG_ UI_chargeFeature3 : 28|1@1+ (1,0) [0|1] "" Vector__XXX
 SG_ UI_scheduledDepartureEnabled : 29|1@1+ (1,0) [0|1] "" Vector__XXX
 SG_ UI_chargePortLatchRequest : 30|2@1+ (1,0) [0|3] "" Vector__XXX
 SG_ UI_socSnapshotExpirationTime : 32|4@1+ (2,2) [2|32] "weeks" Vector__XXX
 SG_ UI_cpInletHeaterRequest : 36|2@1+ (1,0) [0|3] "" Vector__XXX
 SG_ UI_chargePowerSampleRequest : 38|1@1+ (1,0) [0|1] "" Vector__XXX
 SG_ UI_enableIso15118 : 39|1@1+ (1,0) [0|1] "" Vector__XXX

BO_ 659 UI_chassisControl: 8 GTW
 SG_ UI_steeringTuneRequest : 0|2@1+ (1,0) [0|3] "" Vector__XXX
 SG_ UI_tractionControlMode : 2|3@1+ (1,0) [0|7] "" Vector__XXX
 SG_ UI_parkBrakeRequest : 5|2@1+ (1,0) [0|2] "" Vector__XXX
 SG_ UI_narrowGarages : 7|1@1+ (1,0) [0|1] "" Vector__XXX
 SG_ UI_winchModeRequest : 8|2@1+ (1,0) [0|3] "" Vector__XXX
 SG_ UI_zeroSpeedConfirmed : 10|2@1+ (1,0) [0|2] "" Vector__XXX
 SG_ UI_trailerMode : 12|1@1+ (1,0) [0|1] "" Vector__XXX
 SG_ UI_distanceUnits : 13|1@1+ (1,0) [0|1] "" Vector__XXX
 SG_ UI_dasDebugEnable : 14|1@1+ (1,0) [0|1] "" Vector__XXX
 SG_ UI_accOvertakeEnable : 16|2@1+ (1,0) [0|2] "" Vector__XXX
 SG_ UI_aebEnable : 18|2@1+ (1,0) [0|2] "" Vector__XXX
 SG_ UI_aesEnable : 20|2@1+ (1,0) [0|2] "" Vector__XXX
 SG_ UI_ahlbEnable : 22|2@1+ (1,0) [0|2] "" Vector__XXX
 SG_ UI_autoLaneChangeEnable : 24|2@1+ (1,0) [0|2] "" Vector__XXX
 SG_ UI_winchProxUserOverride : 26|1@1+ (1,0) [0|1] "" Vector__XXX
 SG_ UI_rebootAutopilot : 27|1@1+ (1,0) [0|1] "" Vector__XXX
 SG_ UI_autoParkRequest : 28|4@1+ (1,0) [0|14] "" Vector__XXX
 SG_ UI_bsdEnable : 32|2@1+ (1,0) [0|2] "" Vector__XXX
 SG_ UI_fcwEnable : 34|2@1+ (1,0) [0|2] "" Vector__XXX
 SG_ UI_fcwSensitivity : 36|2@1+ (1,0) [0|2] "" Vector__XXX
 SG_ UI_latControlEnable : 38|2@1+ (1,0) [0|2] "" Vector__XXX
 SG_ UI_ldwEnable : 40|2@1+ (1,0) [0|2] "" Vector__XXX
 SG_ UI_pedalSafetyEnable : 42|2@1+ (1,0) [0|2] "" Vector__XXX
 SG_ UI_pedalMap_epas : 44|2@1+ (1,0) [0|3] "" Vector__XXX
 SG_ UI_redLightStopSignEnable : 46|2@1+ (1,0) [0|2] "" Vector__XXX
 SG_ UI_selfParkTune : 48|4@1+ (1,0) [0|14] "" Vector__XXX
 SG_ UI_chassisControlCounter : 52|4@1+ (1,0) [0|15] "" Vector__XXX
 SG_ UI_chassisControlChecksum : 56|8@1+ (1,0) [0|255] "" Vector__XXX

BO_ 1280 UI_debugECU: 2 GTW
 SG_ UI_debugEcuTarget M : 0|5@1+ (1,0) [0|31] "" Vector__XXX
 SG_ UI_DI_debugEnable m1 : 8|1@1+ (1,0) [0|1] "" Vector__XXX
 SG_ UI_DIS_debugEnable m2 : 8|1@1+ (1,0) [0|1] "" Vector__XXX
 SG_ UI_PM_debugEnable m3 : 8|1@1+ (1,0) [0|1] "" Vector__XXX
 SG_ UI_PM_debugAt100Hz m3 : 9|1@1+ (1,0) [0|1] "" Vector__XXX
 SG_ UI_PMS_debugEnable m4 : 8|1@1+ (1,0) [0|1] "" Vector__XXX
 SG_ UI_PMS_debugAt100Hz m4 : 9|1@1+ (1,0) [0|1] "" Vector__XXX
 SG_ UI_BMS_debugAllEnable m5 : 8|1@1+ (1,0) [0|1] "" Vector__XXX
 SG_ UI_BMS_debugDisable m5 : 9|1@1+ (1,0) [0|1] "" Vector__XXX
 SG_ UI_VCRIGHT_debugEnable m6 : 8|1@1+ (1,0) [0|1] "" Vector__XXX
 SG_ UI_VCFRONT_debugEnable m7 : 5|1@1+ (1,0) [0|1] "" Vector__XXX
 SG_ UI_DIF_debugEnable m8 : 8|1@1+ (1,0) [0|1] "" Vector__XXX
 SG_ UI_DIR_debugEnable m9 : 8|1@1+ (1,0) [0|1] "" Vector__XXX
 SG_ UI_PMF_debugEnable m10 : 8|1@1+ (1,0) [0|1] "" Vector__XXX
 SG_ UI_PMR_debugEnable m11 : 8|1@1+ (1,0) [0|1] "" Vector__XXX

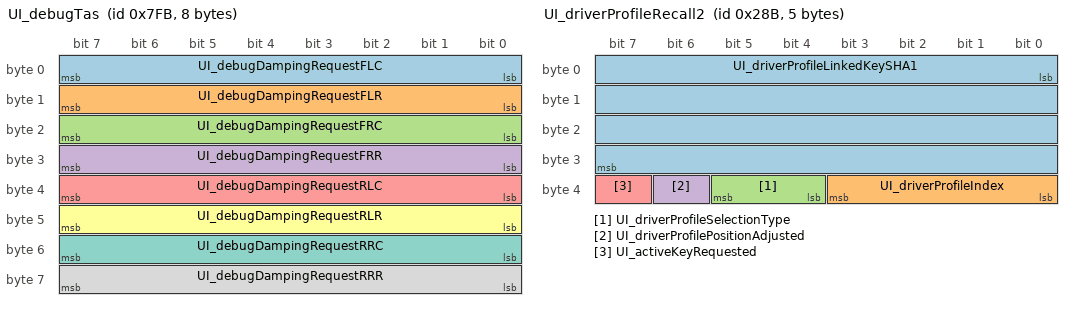
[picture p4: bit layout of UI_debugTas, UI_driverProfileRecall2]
BO_ 2043 UI_debugTas: 8 GTW
 SG_ UI_debugDampingRequestFLC : 0|8@1+ (0.01,0) [0|2.54] "A" Vector__XXX
 SG_ UI_debugDampingRequestFLR : 8|8@1+ (0.01,0) [0|2.54] "A" Vector__XXX
 SG_ UI_debugDampingRequestFRC : 16|8@1+ (0.01,0) [0|2.54] "A" Vector__XXX
 SG_ UI_debugDampingRequestFRR : 24|8@1+ (0.01,0) [0|2.54] "A" Vector__XXX
 SG_ UI_debugDampingRequestRLC : 32|8@1+ (0.01,0) [0|2.54] "A" Vector__XXX
 SG_ UI_debugDampingRequestRLR : 40|8@1+ (0.01,0) [0|2.54] "A" Vector__XXX
 SG_ UI_debugDampingRequestRRC : 48|8@1+ (0.01,0) [0|2.54] "A" Vector__XXX
 SG_ UI_debugDampingRequestRRR : 56|8@1+ (0.01,0) [0|2.54] "A" Vector__XXX

BO_ 568 UI_driverAssistMapData: 8 GTW
 SG_ UI_mapSpeedLimitDependency : 0|3@1+ (1,0) [0|6] "" Vector__XXX
 SG_ UI_roadClass : 3|3@1+ (1,0) [1|7] "" Vector__XXX
 SG_ UI_inSuperchargerGeofence : 6|1@1+ (1,0) [0|1] "" Vector__XXX
 SG_ UI_mapSpeedUnits : 7|1@1+ (1,0) [0|1] "" Vector__XXX
 SG_ UI_mapSpeedLimit : 8|5@1+ (1,0) [0|30] "" Vector__XXX
 SG_ UI_mapSpeedLimitType : 13|3@1+ (1,0) [0|6] "" Vector__XXX
 SG_ UI_countryCode : 16|10@1+ (1,0) [0|1022] "" Vector__XXX
 SG_ UI_streetCount : 26|2@1+ (1,0) [0|3] "" Vector__XXX
 SG_ UI_gpsRoadMatch : 28|1@1+ (1,0) [0|1] "" Vector__XXX
 SG_ UI_navRouteActive : 29|1@1+ (1,0) [0|1] "" Vector__XXX
 SG_ UI_parallelAutoparkEnabled : 30|1@1+ (1,0) [0|1] "" Vector__XXX
 SG_ UI_perpendicularAutoparkEnabled : 31|1@1+ (1,0) [0|1] "" Vector__XXX
 SG_ UI_nextBranchDist : 32|5@1+ (10,0) [0|300] "m" Vector__XXX
 SG_ UI_controlledAccess : 37|1@1+ (1,0) [0|1] "" Vector__XXX
 SG_ UI_nextBranchLeftOffRamp : 38|1@1+ (1,0) [0|1] "" Vector__XXX
 SG_ UI_nextBranchRightOffRamp : 39|1@1+ (1,0) [0|1] "" Vector__XXX
 SG_ UI_rejectLeftLane : 40|1@1+ (1,0) [0|1] "" Vector__XXX
 SG_ UI_rejectRightLane : 41|1@1+ (1,0) [0|1] "" Vector__XXX
 SG_ UI_rejectHPP : 42|1@1+ (1,0) [0|1] "" Vector__XXX
 SG_ UI_rejectNav : 43|1@1+ (1,0) [0|1] "" Vector__XXX
 SG_ UI_rejectLeftFreeSpace : 44|1@1+ (1,0) [0|1] "" Vector__XXX
 SG_ UI_rejectRightFreeSpace : 45|1@1+ (1,0) [0|1] "" Vector__XXX
 SG_ UI_rejectAutosteer : 46|1@1+ (1,0) [0|1] "" Vector__XXX
 SG_ UI_rejectHandsOn : 47|1@1+ (1,0) [0|1] "" Vector__XXX
 SG_ UI_acceptBottsDots : 48|1@1+ (1,0) [0|1] "" Vector__XXX
 SG_ UI_autosteerRestricted : 49|1@1+ (1,0) [0|1] "" Vector__XXX
 SG_ UI_pmmEnabled : 50|1@1+ (1,0) [0|1] "" Vector__XXX
 SG_ UI_scaEnabled : 51|1@1+ (1,0) [0|1] "" Vector__XXX
 SG_ UI_mapDataCounter : 52|4@1+ (1,0) [0|15] "" Vector__XXX
 SG_ UI_mapDataChecksum : 56|8@1+ (1,0) [0|255] "" Vector__XXX

BO_ 645 UI_driverProfileRecall: 8 GTW
 SG_ UI_driverProfileRecallIndex M : 0|3@1+ (1,0) [1|7] "" Vector__XXX
 SG_ UI_driverProfileRecallStop : 3|1@1+ (1,0) [0|1] "" Vector__XXX
 SG_ UI_frontSeatRecallActive m1 : 4|1@1+ (1,0) [0|1] "" Vector__XXX
 SG_ UI_frontSeatTrackPos m1 : 5|10@1- (4,0) [-2048|2044] "mm" Vector__XXX
 SG_ UI_frontSeatBackPos m1 : 16|12@1- (0.1,0) [-204.8|204.7] "deg" Vector__XXX
 SG_ UI_frontSeatLiftPos m1 : 32|10@1- (4,0) [-2048|2044] "mm" Vector__XXX
 SG_ UI_frontSeatTiltPos m1 : 48|12@1- (0.1,0) [-204.8|204.7] "deg" Vector__XXX
 SG_ UI_columnAndLumbarRecallActive m2 : 4|1@1+ (1,0) [0|1] "" Vector__XXX
 SG_ UI_steeringColumnUpDownPos m2 : 8|8@1- (1,103) [-25|230] "mm" Vector__XXX
 SG_ UI_lumbarAPressurePercentage m2 : 16|7@1+ (1,0) [0|126] "%" Vector__XXX
 SG_ UI_lumbarBPressurePercentage m2 : 32|7@1+ (1,0) [0|126] "%" Vector__XXX
 SG_ UI_steeringColumnInOutPos m2 : 48|8@1- (1,103) [-25|230] "mm" Vector__XXX
 SG_ UI_leftMirrorTiltXPosition m3 : 8|8@1+ (0.02,0) [0|5] "V" Vector__XXX
 SG_ UI_leftMirrorTiltYPosition m3 : 16|8@1+ (0.02,0) [0|5] "V" Vector__XXX
 SG_ UI_rightMirrorTiltXPosition m3 : 24|8@1+ (0.02,0) [0|5.1] "V" Vector__XXX
 SG_ UI_rightMirrorTiltYPosition m3 : 32|8@1+ (0.02,0) [0|5.1] "V" Vector__XXX
 SG_ UI_frontSeatThighSupportPos m3 : 40|8@1- (1,0) [-128|127] "mm" Vector__XXX
 SG_ UI_mirrorRecallActive m4 : 4|1@1+ (1,0) [0|1] "" Vector__XXX
 SG_ UI_customMirrorDipPositionsSet m4 : 5|1@1+ (1,0) [0|1] "" Vector__XXX
 SG_ UI_leftMirrorDipXPosition m4 : 8|8@1+ (0.02,0) [0|5] "V" Vector__XXX
 SG_ UI_leftMirrorDipYPosition m4 : 16|8@1+ (0.02,0) [0|5] "V" Vector__XXX
 SG_ UI_rightMirrorDipXPosition m4 : 24|8@1+ (0.02,0) [0|5.1] "V" Vector__XXX
 SG_ UI_rightMirrorDipYPosition m4 : 32|8@1+ (0.02,0) [0|5.1] "V" Vector__XXX
 SG_ UI_modifyMirrorDipRequest m4 : 40|2@1+ (1,0) [0|3] "" Vector__XXX

BO_ 651 UI_driverProfileRecall2: 5 GTW
 SG_ UI_driverProfileLinkedKeySHA1 : 0|32@1+ (1,0) [0|4294967294] "" Vector__XXX
 SG_ UI_driverProfileIndex : 32|4@1+ (1,0) [0|15] "" Vector__XXX
 SG_ UI_driverProfileSelectionType : 36|2@1+ (1,0) [0|3] "" Vector__XXX
 SG_ UI_driverProfilePositionAdjusted : 38|1@1+ (1,0) [0|1] "" Vector__XXX
 SG_ UI_activeKeyRequested : 39|1@1+ (1,0) [0|1] "" Vector__XXX

BO_ 984 UI_elevationStatus: 4 GTW
 SG_ UI_elevation : 0|14@1- (1,0) [-8192|8190] "m" Vector__XXX
 SG_ UI_navElevation : 16|14@1- (1,0) [-8192|8190] "m" Vector__XXX

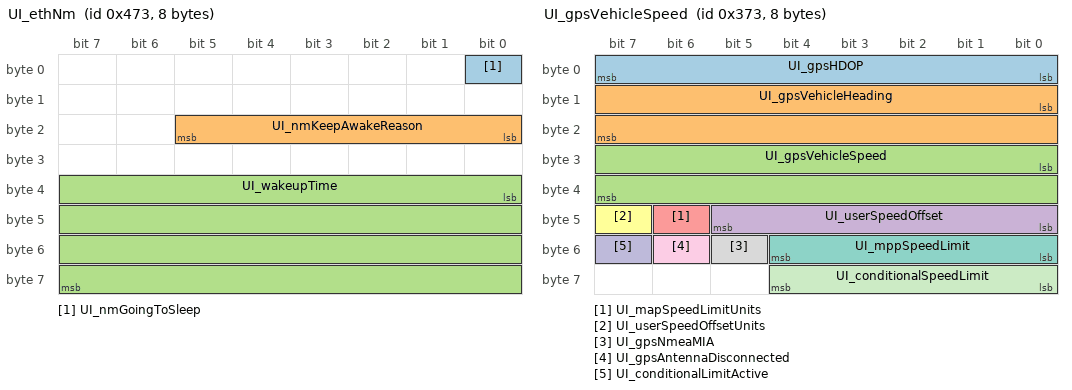
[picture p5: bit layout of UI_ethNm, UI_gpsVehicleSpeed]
BO_ 1139 UI_ethNm: 8 GTW
 SG_ UI_nmGoingToSleep : 0|1@1+ (1,0) [0|1] "" Vector__XXX
 SG_ UI_nmKeepAwakeReason : 16|6@1+ (1,0) [1|63] "" Vector__XXX
 SG_ UI_wakeupTime : 32|32@1+ (1,0) [0|4294967295] "" Vector__XXX

BO_ 1267 UI_frontSeatRequests: 4 GTW
 SG_ UI_frontRightSeatTrackForward : 0|1@1+ (1,0) [0|1] "" Vector__XXX
 SG_ UI_frontRightSeatTrackBack : 1|1@1+ (1,0) [0|1] "" Vector__XXX
 SG_ UI_frontLeftSeatTrackForward : 2|1@1+ (1,0) [0|1] "" Vector__XXX
 SG_ UI_frontLeftSeatTrackBack : 3|1@1+ (1,0) [0|1] "" Vector__XXX
 SG_ UI_frontRightSeatBackrestBack : 4|1@1+ (1,0) [0|1] "" Vector__XXX
 SG_ UI_frontRightSeatBackrestForward : 5|1@1+ (1,0) [0|1] "" Vector__XXX
 SG_ UI_frontLeftSeatBackrestBack : 6|1@1+ (1,0) [0|1] "" Vector__XXX
 SG_ UI_frontLeftSeatBackrestForward : 7|1@1+ (1,0) [0|1] "" Vector__XXX
 SG_ UI_frontRightSeatTiltUp : 8|1@1+ (1,0) [0|1] "" Vector__XXX
 SG_ UI_frontRightSeatTiltDown : 9|1@1+ (1,0) [0|1] "" Vector__XXX
 SG_ UI_frontLeftSeatTiltUp : 10|1@1+ (1,0) [0|1] "" Vector__XXX
 SG_ UI_frontLeftSeatTiltDown : 11|1@1+ (1,0) [0|1] "" Vector__XXX
 SG_ UI_frontRightSeatLiftUp : 12|1@1+ (1,0) [0|1] "" Vector__XXX
 SG_ UI_frontRightSeatLiftDown : 13|1@1+ (1,0) [0|1] "" Vector__XXX
 SG_ UI_frontLeftSeatLiftUp : 14|1@1+ (1,0) [0|1] "" Vector__XXX
 SG_ UI_frontLeftSeatLiftDown : 15|1@1+ (1,0) [0|1] "" Vector__XXX
 SG_ UI_frontLeftSeatLumbarUp : 16|1@1+ (1,0) [0|1] "" Vector__XXX
 SG_ UI_frontLeftSeatLumbarDown : 17|1@1+ (1,0) [0|1] "" Vector__XXX
 SG_ UI_frontRightSeatLumbarUp : 18|1@1+ (1,0) [0|1] "" Vector__XXX
 SG_ UI_frontRightSeatLumbarDown : 19|1@1+ (1,0) [0|1] "" Vector__XXX
 SG_ UI_frontLeftSeatLumbarIn : 20|1@1+ (1,0) [0|1] "" Vector__XXX
 SG_ UI_frontLeftSeatLumbarOut : 21|1@1+ (1,0) [0|1] "" Vector__XXX
 SG_ UI_frontRightSeatLumbarIn : 22|1@1+ (1,0) [0|1] "" Vector__XXX
 SG_ UI_frontRightSeatLumbarOut : 23|1@1+ (1,0) [0|1] "" Vector__XXX
 SG_ UI_seatAdjustmentSource : 24|3@1+ (1,0) [0|7] "" Vector__XXX

BO_ 804 UI_gpsTime: 8 GTW
 SG_ UI_gpsTime : 0|64@1+ (1,0) [0|1.84467440737e+19] "" Vector__XXX

BO_ 883 UI_gpsVehicleSpeed: 8 GTW
 SG_ UI_gpsHDOP : 0|8@1+ (0.1,0) [0|25.5] "1" Vector__XXX
 SG_ UI_gpsVehicleHeading : 8|16@1+ (0.0078125,0) [0|511.9921875] "deg" Vector__XXX
 SG_ UI_gpsVehicleSpeed : 24|16@1+ (0.00390625,0) [0|255.99609375] "km/hr" Vector__XXX
 SG_ UI_userSpeedOffset : 40|6@1+ (1,-30) [-30|33] "kph/mph" Vector__XXX
 SG_ UI_mapSpeedLimitUnits : 46|1@1+ (1,0) [0|1] "" Vector__XXX
 SG_ UI_userSpeedOffsetUnits : 47|1@1+ (1,0) [0|1] "" Vector__XXX
 SG_ UI_mppSpeedLimit : 48|5@1+ (5,0) [0|155] "kph/mph" Vector__XXX
 SG_ UI_gpsNmeaMIA : 53|1@1+ (1,0) [0|1] "" Vector__XXX
 SG_ UI_gpsAntennaDisconnected : 54|1@1+ (1,0) [0|1] "" Vector__XXX
 SG_ UI_conditionalLimitActive : 55|1@1+ (1,0) [0|1] "" Vector__XXX
 SG_ UI_conditionalSpeedLimit : 56|5@1+ (5,0) [0|150] "kph/mph" Vector__XXX

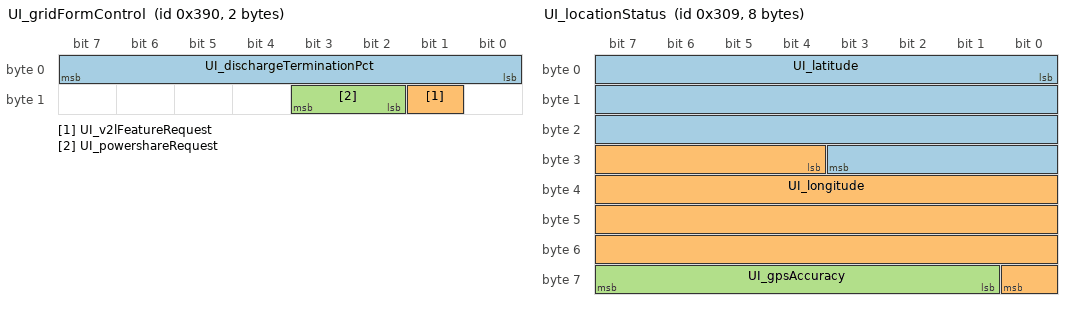
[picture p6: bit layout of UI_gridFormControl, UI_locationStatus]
BO_ 912 UI_gridFormControl: 2 GTW
 SG_ UI_dischargeTerminationPct : 0|8@1+ (1,0) [0|255] "%" Vector__XXX
 SG_ UI_v2lFeatureRequest : 9|1@1+ (1,0) [0|1] "" Vector__XXX
 SG_ UI_powershareRequest : 10|2@1+ (1,0) [0|3] "" Vector__XXX

BO_ 755 UI_hvacRequest: 8 GTW
 SG_ UI_hvacReqTempSetpointLeft : 0|5@1+ (0.5,15) [15|28] "degC" Vector__XXX
 SG_ UI_hvacReqAutoBlowerLevel : 5|3@1+ (1,0) [0|7] "" Vector__XXX
 SG_ UI_hvacReqTempSetpointRight : 8|5@1+ (0.5,15) [15|28] "degC" Vector__XXX
 SG_ UI_hvacReqAirDistributionMode : 13|3@1+ (1,0) [0|7] "" Vector__XXX
 SG_ UI_hvacReqBlowerSegment : 16|4@1+ (1,0) [0|15] "" Vector__XXX
 SG_ UI_hvacReqRecirc : 20|2@1+ (1,0) [0|3] "" Vector__XXX
 SG_ UI_hvacReqACDisable : 22|2@1+ (1,0) [0|3] "" Vector__XXX
 SG_ UI_hvacDefogState : 24|2@1+ (1,0) [0|3] "" Vector__XXX
 SG_ UI_hvacReqUserPowerState : 26|3@1+ (1,0) [0|7] "" Vector__XXX
 SG_ UI_hvacReqSecondRowState : 29|3@1+ (1,0) [0|7] "" Vector__XXX
 SG_ UI_hvacUseModeledDuctTemp : 32|1@1+ (1,0) [0|1] "" Vector__XXX
 SG_ UI_hvacReqKeepClimateOn : 33|2@1+ (1,0) [0|3] "" Vector__XXX
 SG_ UI_hvacReqBioWeaponDefMode : 35|1@1+ (1,0) [0|1] "" Vector__XXX
 SG_ UI_hvacLatchPassengerPresent : 39|1@1+ (1,0) [0|1] "" Vector__XXX
 SG_ UI_enableHvacControlsFeatures1 : 44|1@1+ (1,0) [0|1] "" Vector__XXX
 SG_ UI_enableHvacNotifications : 45|1@1+ (1,0) [0|1] "" Vector__XXX
 SG_ UI_hvacPhoneCallAirFlowAdjustEna : 46|1@1+ (1,0) [0|1] "" Vector__XXX
 SG_ UI_enableHvacVOCPurgeRoutine : 47|1@1+ (1,0) [0|1] "" Vector__XXX
 SG_ UI_enableCustomerTHSAlerts : 53|1@1+ (1,0) [0|1] "" Vector__XXX
 SG_ UI_evapDryingSelectiveEnable : 54|1@1+ (1,0) [0|1] "" Vector__XXX
 SG_ UI_enableHvacWeatherDataBasedHum : 55|1@1+ (1,0) [0|1] "" Vector__XXX
 SG_ UI_hvacReqTempSetpointCOP : 56|2@1+ (1,0) [0|3] "" Vector__XXX
 SG_ UI_hvacClimateNudgeStatus : 58|3@1+ (1,0) [0|7] "" Vector__XXX
 SG_ UI_enableHvacControlsFeatures2 : 61|1@1+ (1,0) [0|1] "" Vector__XXX
 SG_ UI_enableHvacAPFoggingMonitor : 62|1@1+ (1,0) [0|1] "" Vector__XXX
 SG_ UI_enableHvacLimpMode : 63|1@1+ (1,0) [0|1] "" Vector__XXX

BO_ 777 UI_locationStatus: 8 GTW
 SG_ UI_latitude : 0|28@1- (1.0e-06,0) [-134.217728|134.217727] "deg" Vector__XXX
 SG_ UI_longitude : 28|29@1- (1.0e-06,0) [-268.435456|268.435455] "deg" Vector__XXX
 SG_ UI_gpsAccuracy : 57|7@1+ (0.2,0) [0|25.2] "m" Vector__XXX

BO_ 1523 UI_odo: 3 GTW
 SG_ UI_odometer : 0|24@1+ (0.1,0) [0|1677721.4] "km" Vector__XXX

BO_ 948 UI_peripheralPowerRequests: 1 GTW
 SG_ UI_usbFrontHubPowerStateRequest : 0|2@1+ (1,0) [1|3] "" Vector__XXX

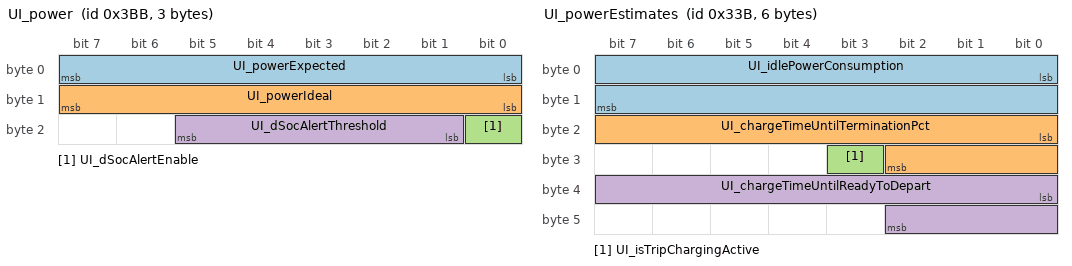
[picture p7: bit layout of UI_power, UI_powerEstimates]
BO_ 955 UI_power: 3 GTW
 SG_ UI_powerExpected : 0|8@1+ (1,0) [0|255] "kW" Vector__XXX
 SG_ UI_powerIdeal : 8|8@1+ (1,0) [0|255] "kW" Vector__XXX
 SG_ UI_dSocAlertEnable : 16|1@1+ (1,0) [0|1] "" Vector__XXX
 SG_ UI_dSocAlertThreshold : 17|5@1+ (0.1,-3) [-3|0.1] "%" Vector__XXX

BO_ 827 UI_powerEstimates: 6 GTW
 SG_ UI_idlePowerConsumption : 0|16@1+ (0.001,0) [0|50] "kW" Vector__XXX
 SG_ UI_chargeTimeUntilTerminationPct : 16|11@1+ (1,0) [0|2046] "min" Vector__XXX
 SG_ UI_isTripChargingActive : 27|1@1+ (1,0) [0|1] "" Vector__XXX
 SG_ UI_chargeTimeUntilReadyToDepart : 32|11@1+ (1,0) [0|2046] "min" Vector__XXX

BO_ 661 UI_powerRationalityConfig: 8 GTW
 SG_ UI_powerRationalityConfigIndex M : 56|8@1+ (1,0) [0|255] "" Vector__XXX
 SG_ UI_vcleftCfgRationalityThreshold m0 : 0|4@1+ (1,0) [1|15] "" Vector__XXX
 SG_ UI_vcleftCfgRationalityTime0 m0 : 4|4@1+ (1,0) [1|15] "" Vector__XXX
 SG_ UI_vcleftCfgRationalityThre_0001 m0 : 8|4@1+ (1,0) [1|15] "" Vector__XXX
 SG_ UI_vcleftCfgRationalityTime1 m0 : 12|4@1+ (1,0) [1|15] "" Vector__XXX
 SG_ UI_vcleftCfgRationalityStaticA m1 : 0|16@1+ (50,0) [0|3276700] "-" Vector__XXX
 SG_ UI_vcleftCfgRationalityStaticB m1 : 16|16@1- (1,0) [-32768|32767] "-" Vector__XXX
 SG_ UI_vcleftCfgRationalityStaticC m1 : 32|16@1- (50,0) [-1638400|1638350] "-" Vector__XXX
 SG_ UI_vcleftCfgRationalityDynamicA m2 : 0|16@1+ (50,0) [0|3276700] "-" Vector__XXX
 SG_ UI_vcleftCfgRationalityDynamicB m2 : 16|16@1- (1,0) [-32768|32767] "-" Vector__XXX
 SG_ UI_vcleftCfgRationalityDynamicC m2 : 32|16@1- (50,0) [-1638400|1638350] "-" Vector__XXX
 SG_ UI_vcrightCfgRationalityThreshol m3 : 0|4@1+ (1,0) [1|15] "" Vector__XXX
 SG_ UI_vcrightCfgRationalityTime0 m3 : 4|4@1+ (1,0) [1|15] "" Vector__XXX
 SG_ UI_vcrightCfgRationalityThr_0001 m3 : 8|4@1+ (1,0) [1|15] "" Vector__XXX
 SG_ UI_vcrightCfgRationalityTime1 m3 : 12|4@1+ (1,0) [1|15] "" Vector__XXX
 SG_ UI_vcrightCfgRationalityStaticA m4 : 0|16@1+ (50,0) [0|3276700] "-" Vector__XXX
 SG_ UI_vcrightCfgRationalityStaticB m4 : 16|16@1- (1,0) [-32768|32767] "-" Vector__XXX
 SG_ UI_vcrightCfgRationalityStaticC m4 : 32|16@1- (50,0) [-1638400|1638350] "-" Vector__XXX
 SG_ UI_vcrightCfgRationalityDynamicA m5 : 0|16@1+ (50,0) [0|3276700] "-" Vector__XXX
 SG_ UI_vcrightCfgRationalityDynamicB m5 : 16|16@1- (1,0) [-32768|32767] "-" Vector__XXX
 SG_ UI_vcrightCfgRationalityDynamicC m5 : 32|16@1- (50,0) [-1638400|1638350] "-" Vector__XXX
 SG_ UI_vcleftCfgCutoffThreshold0 m6 : 0|4@1+ (1,0) [1|15] "" Vector__XXX
 SG_ UI_vcleftCfgCutoffTime0 m6 : 4|4@1+ (1,0) [1|15] "" Vector__XXX
 SG_ UI_vcleftCfgCutoffThreshold1 m6 : 8|4@1+ (1,0) [1|15] "" Vector__XXX
 SG_ UI_vcleftCfgCutoffTime1 m6 : 12|4@1+ (1,0) [1|15] "" Vector__XXX
 SG_ UI_vcleftCfgCutoffStaticA m7 : 0|16@1+ (50,0) [0|3276700] "-" Vector__XXX
 SG_ UI_vcleftCfgCutoffStaticB m7 : 16|16@1- (1,0) [-32768|32767] "-" Vector__XXX
 SG_ UI_vcleftCfgCutoffStaticC m7 : 32|16@1- (50,0) [-1638400|1638350] "-" Vector__XXX
 SG_ UI_vcleftCfgCutoffDynamicA m8 : 0|16@1+ (50,0) [0|3276700] "-" Vector__XXX
 SG_ UI_vcleftCfgCutoffDynamicB m8 : 16|16@1- (1,0) [-32768|32767] "-" Vector__XXX
 SG_ UI_vcleftCfgCutoffDynamicC m8 : 32|16@1- (50,0) [-1638400|1638350] "-" Vector__XXX
 SG_ UI_vcrightCfgCutoffThreshold0 m9 : 0|4@1+ (1,0) [1|15] "" Vector__XXX
 SG_ UI_vcrightCfgCutoffTime0 m9 : 4|4@1+ (1,0) [1|15] "" Vector__XXX
 SG_ UI_vcrightCfgCutoffThreshold1 m9 : 8|4@1+ (1,0) [1|15] "" Vector__XXX
 SG_ UI_vcrightCfgCutoffTime1 m9 : 12|4@1+ (1,0) [1|15] "" Vector__XXX
 SG_ UI_vcrightCfgCutoffStaticA m10 : 0|16@1+ (50,0) [0|3276700] "-" Vector__XXX
 SG_ UI_vcrightCfgCutoffStaticB m10 : 16|16@1- (1,0) [-32768|32767] "-" Vector__XXX
 SG_ UI_vcrightCfgCutoffStaticC m10 : 32|16@1- (50,0) [-1638400|1638350] "-" Vector__XXX
 SG_ UI_vcrightCfgCutoffDynamicA m11 : 0|16@1+ (50,0) [0|3276700] "-" Vector__XXX
 SG_ UI_vcrightCfgCutoffDynamicB m11 : 16|16@1- (1,0) [-32768|32767] "-" Vector__XXX
 SG_ UI_vcrightCfgCutoffDynamicC m11 : 32|16@1- (50,0) [-1638400|1638350] "-" Vector__XXX

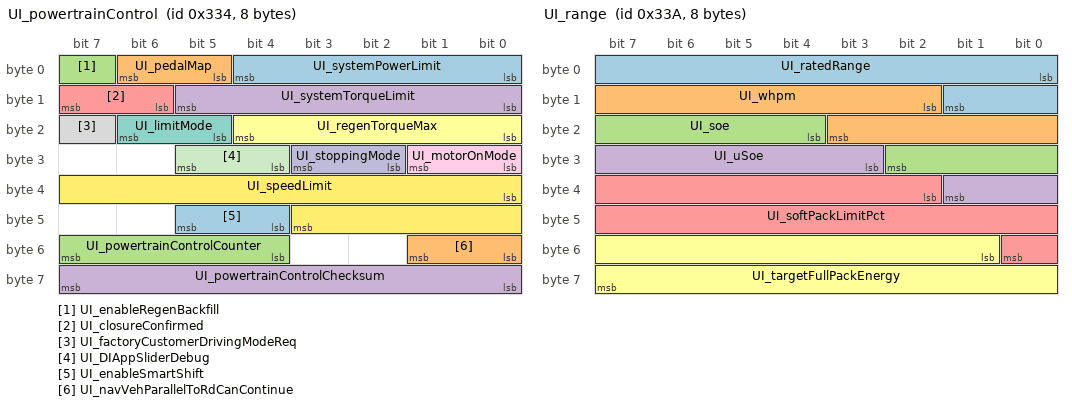
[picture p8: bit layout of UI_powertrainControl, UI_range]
BO_ 820 UI_powertrainControl: 8 GTW
 SG_ UI_systemPowerLimit : 0|5@1+ (20,20) [20|620] "kW" Vector__XXX
 SG_ UI_pedalMap : 5|2@1+ (1,0) [0|3] "" Vector__XXX
 SG_ UI_enableRegenBackfill : 7|1@1+ (1,0) [0|1] "" Vector__XXX
 SG_ UI_systemTorqueLimit : 8|6@1+ (150,1000) [1000|10300] "Nm" Vector__XXX
 SG_ UI_closureConfirmed : 14|2@1+ (1,0) [0|3] "" Vector__XXX
 SG_ UI_regenTorqueMax : 16|5@1+ (5,0) [0|100] "%" Vector__XXX
 SG_ UI_limitMode : 21|2@1+ (1,0) [0|3] "" Vector__XXX
 SG_ UI_factoryCustomerDrivingModeReq : 23|1@1+ (1,0) [0|1] "" Vector__XXX
 SG_ UI_motorOnMode : 24|2@1+ (1,0) [0|3] "" Vector__XXX
 SG_ UI_stoppingMode : 26|2@1+ (1,0) [0|3] "" Vector__XXX
 SG_ UI_DIAppSliderDebug : 28|2@1+ (1,0) [0|3] "" Vector__XXX
 SG_ UI_speedLimit : 32|12@1+ (0.1,0) [0|335] "kph" Vector__XXX
 SG_ UI_enableSmartShift : 44|2@1+ (1,0) [0|3] "" Vector__XXX
 SG_ UI_navVehParallelToRdCanContinue : 48|2@1+ (1,0) [1|3] "" Vector__XXX
 SG_ UI_powertrainControlCounter : 52|4@1+ (1,0) [0|15] "" Vector__XXX
 SG_ UI_powertrainControlChecksum : 56|8@1+ (1,0) [0|255] "" Vector__XXX

BO_ 826 UI_range: 8 GTW
 SG_ UI_ratedRange : 0|10@1+ (1,0) [0|1023] "mi" Vector__XXX
 SG_ UI_whpm : 10|10@1+ (1,0) [0|1023] "" Vector__XXX
 SG_ UI_soe : 20|7@1+ (1,0) [0|127] "%" Vector__XXX
 SG_ UI_uSoe : 27|7@1+ (1,0) [0|127] "%" Vector__XXX
 SG_ UI_softPackLimitPct : 34|15@1+ (0.003051851,0) [0|100.000001717] "%" Vector__XXX
 SG_ UI_targetFullPackEnergy : 49|15@1+ (0.006103702,0) [0|200.000003434] "kWh" Vector__XXX

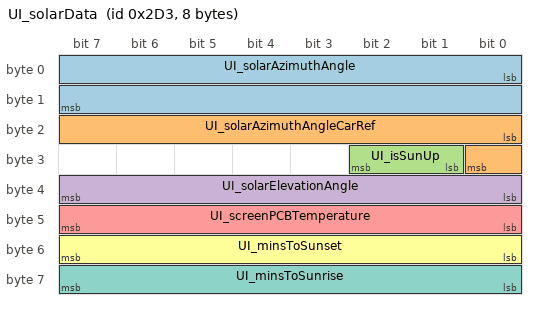
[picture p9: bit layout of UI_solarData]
BO_ 723 UI_solarData: 8 GTW
 SG_ UI_solarAzimuthAngle : 0|16@1- (1,0) [-32768|32767] "degrees" Vector__XXX
 SG_ UI_solarAzimuthAngleCarRef : 16|9@1- (1,0) [-256|254] "degrees" Vector__XXX
 SG_ UI_isSunUp : 25|2@1+ (1,0) [0|2] "" Vector__XXX
 SG_ UI_solarElevationAngle : 32|8@1- (1,0) [-128|126] "degrees" Vector__XXX
 SG_ UI_screenPCBTemperature : 40|8@1- (0.5,40) [-20|100] "degC" Vector__XXX
 SG_ UI_minsToSunset : 48|8@1+ (10,0) [0|2550] "min" Vector__XXX
 SG_ UI_minsToSunrise : 56|8@1+ (10,0) [0|2550] "min" Vector__XXX

BO_TX_BU_ 852 : TAS;
BO_TX_BU_ 523 : TAS;
BO_TX_BU_ 1398 : TAS;
BO_TX_BU_ 1357 : TAS;
BO_TX_BU_ 525 : TAS;
BO_TX_BU_ 1627 : TAS;
BO_TX_BU_ 409 : TAS;
BO_TX_BU_ 410 : TAS;
BO_TX_BU_ 538 : TAS;
BO_TX_BU_ 1641 : GTW;
BO_TX_BU_ 1538 : GTW;
BO_TX_BU_ 1579 : GTW;
BO_TX_BU_ 1539 : GTW;
BO_TX_BU_ 1543 : GTW;
BO_TX_BU_ 1550 : GTW;
BO_TX_BU_ 1589 : GTW;
BO_TX_BU_ 1541 : GTW;
BO_TX_BU_ 1542 : GTW;
BO_TX_BU_ 1572 : GTW;
BO_TX_BU_ 1574 : GTW;
BO_TX_BU_ 2015 : GTW;
BO_TX_BU_ 1552 : GTW;
BO_TX_BU_ 1560 : GTW;
BO_TX_BU_ 1576 : GTW;
BO_TX_BU_ 1634 : GTW;
BO_TX_BU_ 1568 : GTW;
BO_TX_BU_ 1604 : GTW;
BO_TX_BU_ 1540 : GTW;
BO_TX_BU_ 1734 : GTW;
BO_TX_BU_ 1664 : GTW;
BO_TX_BU_ 1723 : GTW;
BO_TX_BU_ 1611 : GTW;
BO_TX_BU_ 1548 : GTW;
BO_TX_BU_ 1562 : GTW;
BO_TX_BU_ 1633 : GTW;
BO_TX_BU_ 1580 : GTW;
BO_TX_BU_ 1582 : GTW;
BO_TX_BU_ 1536 : GTW;
BO_TX_BU_ 1570 : GTW;
BO_TX_BU_ 1544 : GTW;
BO_TX_BU_ 1546 : GTW;
BO_TX_BU_ 1154 : GTW;
BO_TX_BU_ 1153 : GTW;
BO_TX_BU_ 1657 : GTW;
BO_TX_BU_ 1021 : GTW;
BO_TX_BU_ 819 : GTW;
BO_TX_BU_ 659 : GTW;
BO_TX_BU_ 1280 : GTW;
BO_TX_BU_ 2043 : GTW;
BO_TX_BU_ 568 : GTW;
BO_TX_BU_ 645 : GTW;
BO_TX_BU_ 651 : GTW;
BO_TX_BU_ 984 : GTW;
BO_TX_BU_ 1139 : GTW;
BO_TX_BU_ 1267 : GTW;
BO_TX_BU_ 804 : GTW;
BO_TX_BU_ 883 : GTW;
BO_TX_BU_ 912 : GTW;
BO_TX_BU_ 755 : GTW;
BO_TX_BU_ 777 : GTW;
BO_TX_BU_ 1523 : GTW;
BO_TX_BU_ 948 : GTW;
BO_TX_BU_ 955 : GTW;
BO_TX_BU_ 827 : GTW;
BO_TX_BU_ 661 : GTW;
BO_TX_BU_ 820 : GTW;
BO_TX_BU_ 826 : GTW;
BO_TX_BU_ 723 : GTW;
CM_ BO_ 852 "Air suspension controller message: alert matrix; frame length from the layout, not yet observed on a vehicle bus";
CM_ SG_ 852 TAS_matrixIndex "Air suspension controller: matrix index";
CM_ SG_ 852 TAS_a001_WatchdogReset "Air suspension controller: a001 watchdog reset";
CM_ SG_ 852 TAS_a002_PowerLossReset "Air suspension controller: a002 power loss reset";
CM_ SG_ 852 TAS_a003_SWAssertion "Air suspension controller: a003 SW assertion";
CM_ SG_ 852 TAS_a012_CPUReset "Air suspension controller: a012 CPU reset";
CM_ SG_ 852 TAS_a015_NVMMError "Air suspension controller: a015 NVMM error";
CM_ SG_ 852 TAS_a016_NVMMRecordError "Air suspension controller: a016 NVMM record error";
CM_ SG_ 852 TAS_a021_TaskSchedulerError "Air suspension controller: a021 task scheduler error";
CM_ SG_ 852 TAS_a022_TaskInitError "Air suspension controller: a022 task init error";
CM_ SG_ 852 TAS_a023_rtosResetRequested "Air suspension controller: a023 rtos reset requested";
CM_ SG_ 852 TAS_a024_prefetchAbort "Air suspension controller: a024 prefetch abort";
CM_ SG_ 852 TAS_a025_CrashEvent "Air suspension controller: a025 crash event";
CM_ SG_ 852 TAS_a030_PWMerrorFL "Air suspension controller: a030 PW merror FL";
CM_ SG_ 852 TAS_a031_PWMerrorFR "Air suspension controller: a031 PW merror FR";
CM_ SG_ 852 TAS_a032_PWMerrorRL "Air suspension controller: a032 PW merror RL";
CM_ SG_ 852 TAS_a033_PWMerrorRR "Air suspension controller: a033 PW merror RR";
CM_ SG_ 852 TAS_a034_PWMshortFL "Air suspension controller: a034 PW mshort FL";
CM_ SG_ 852 TAS_a035_PWMshortFR "Air suspension controller: a035 PW mshort FR";
CM_ SG_ 852 TAS_a036_PWMshortRL "Air suspension controller: a036 PW mshort RL";
CM_ SG_ 852 TAS_a037_PWMshortRR "Air suspension controller: a037 PW mshort RR";
CM_ SG_ 852 TAS_a038_PWMopenFL "Air suspension controller: a038 PW mopen FL";
CM_ SG_ 852 TAS_a039_PWMopenFR "Air suspension controller: a039 PW mopen FR";
CM_ SG_ 852 TAS_a040_PWMopenRL "Air suspension controller: a040 PW mopen RL";
CM_ SG_ 852 TAS_a041_PWMopenRR "Air suspension controller: a041 PW mopen RR";
CM_ SG_ 852 TAS_a043_Task1msError "Air suspension controller: a043 task1ms error";
CM_ SG_ 852 TAS_a044_Task10msError "Air suspension controller: a044 task10ms error";
CM_ SG_ 852 TAS_a045_Task100msError "Air suspension controller: a045 task100ms error";
CM_ SG_ 852 TAS_a046_Task1000msError "Air suspension controller: a046 task1000ms error";
CM_ SG_ 852 TAS_a061_XCPConnected "Air suspension controller: a061 XCP connected";
CM_ SG_ 852 TAS_a062_XCPWasConnected "Air suspension controller: a062 XCP was connected";
CM_ SG_ 852 TAS_a063_abortFault "Air suspension controller: a063 abort fault";
CM_ SG_ 852 TAS_a064_abortFaultExt "Air suspension controller: a064 abort fault ext";
CM_ SG_ 852 TAS_a065_ahbWriteFault "Air suspension controller: a065 ahb write fault";
CM_ SG_ 852 TAS_a066_undefinedInstructionAbo "Air suspension controller: a066 undefined instruction abort";
CM_ SG_ 852 TAS_a067_reservedHandlerAbort "Air suspension controller: a067 reserved handler abort";
CM_ SG_ 852 TAS_a070_underVoltage12V "Air suspension controller: a070 under voltage12 v";
CM_ SG_ 852 TAS_a071_overVoltage12V "Air suspension controller: a071 over voltage12 v";
CM_ SG_ 852 TAS_a072_shortCircuit5VOnBoard "Air suspension controller: a072 short circuit5 v on board";
CM_ SG_ 852 TAS_a073_underVoltage5VOnBoard "Air suspension controller: a073 under voltage5 v on board";
CM_ SG_ 852 TAS_a074_shortCircuit5VOffBoard "Air suspension controller: a074 short circuit5 v off board";
CM_ SG_ 852 TAS_a075_underVoltage5VOffBoard "Air suspension controller: a075 under voltage5 v off board";
CM_ SG_ 852 TAS_a076_overVoltage5VOffBoard "Air suspension controller: a076 over voltage5 v off board";
CM_ SG_ 852 TAS_a077_pressureSigVTooLow "Air suspension controller: a077 pressure sig v too low";
CM_ SG_ 852 TAS_a078_pressureSigVTooHigh "Air suspension controller: a078 pressure sig v too high";
CM_ SG_ 852 TAS_a080_shortCircuit5VHeight "Air suspension controller: a080 short circuit5 v height";
CM_ SG_ 852 TAS_a081_underVoltage5VHeight "Air suspension controller: a081 under voltage5 v height";
CM_ SG_ 852 TAS_a082_overVoltage5VHeight "Air suspension controller: a082 over voltage5 v height";
CM_ SG_ 852 TAS_a083_shortCircuit5VAnalog "Air suspension controller: a083 short circuit5 v analog";
CM_ SG_ 852 TAS_a084_underVoltage5VAnalog "Air suspension controller: a084 under voltage5 v analog";
CM_ SG_ 852 TAS_a085_overVoltage5VAnalog "Air suspension controller: a085 over voltage5 v analog";
CM_ SG_ 852 TAS_a086_underVoltage12VSwtchd "Air suspension controller: a086 under voltage12 v swtchd";
CM_ SG_ 852 TAS_a087_overVoltage12VSwtchd "Air suspension controller: a087 over voltage12 v swtchd";
CM_ SG_ 852 TAS_a093_OTPError "Air suspension controller: a093 OTP error";
CM_ SG_ 852 TAS_a098_VCFRONT_MIA "Air suspension controller: a098 VCFRONT MIA";
CM_ SG_ 852 TAS_a099_UI_MIA "Air suspension controller: a099 UI MIA";
CM_ SG_ 852 TAS_a100_RCM_MIA "Air suspension controller: a100 RCM MIA";
CM_ SG_ 852 TAS_a101_ESP_MIA "Air suspension controller: a101 ESP MIA";
CM_ SG_ 852 TAS_a102_DI_MIA "Air suspension controller: a102 DI MIA";
CM_ SG_ 852 TAS_a103_GTW_MIA "Air suspension controller: a103 GTW MIA";
CM_ SG_ 852 TAS_a105_ECUDebugMode "Air suspension controller: a105 ECU debug mode";
CM_ SG_ 852 TAS_a106_HighCPULoad "Air suspension controller: a106 high CPU load";
CM_ SG_ 852 TAS_a107_HighStackUsage "Air suspension controller: a107 high stack usage";
CM_ SG_ 852 TAS_a150_accelAvgImplausible_FL_ "Air suspension controller: a150 accel avg implausible FL x";
CM_ SG_ 852 TAS_a151_accelAvgImplausible_FL_ "Air suspension controller: a151 accel avg implausible FL y";
CM_ SG_ 852 TAS_a152_accelAvgImplausible_FL_ "Air suspension controller: a152 accel avg implausible FL z";
CM_ SG_ 852 TAS_a153_accelAvgImplausible_FR_ "Air suspension controller: a153 accel avg implausible FR x";
CM_ SG_ 852 TAS_a154_accelAvgImplausible_FR_ "Air suspension controller: a154 accel avg implausible FR y";
CM_ SG_ 852 TAS_a155_accelAvgImplausible_FR_ "Air suspension controller: a155 accel avg implausible FR z";
CM_ SG_ 852 TAS_a156_accelAvgImplausible_RL_ "Air suspension controller: a156 accel avg implausible RL x";
CM_ SG_ 852 TAS_a157_accelAvgImplausible_RL_ "Air suspension controller: a157 accel avg implausible RL y";
CM_ SG_ 852 TAS_a158_accelAvgImplausible_RL_ "Air suspension controller: a158 accel avg implausible RL z";
CM_ SG_ 852 TAS_a159_accelAvgImplausible_RR_ "Air suspension controller: a159 accel avg implausible RR x";
CM_ SG_ 852 TAS_a160_accelAvgImplausible_RR_ "Air suspension controller: a160 accel avg implausible RR y";
CM_ SG_ 852 TAS_a161_accelAvgImplausible_RR_ "Air suspension controller: a161 accel avg implausible RR z";
CM_ SG_ 852 TAS_a164_damperSolenoidMismatch "Air suspension controller: a164 damper solenoid mismatch";
CM_ SG_ 852 TAS_a165_damperValveCompFL "Air suspension controller: a165 damper valve comp FL";
CM_ SG_ 852 TAS_a166_damperValveRbndFL "Air suspension controller: a166 damper valve rbnd FL";
CM_ SG_ 852 TAS_a167_damperValveCompFR "Air suspension controller: a167 damper valve comp FR";
CM_ SG_ 852 TAS_a168_damperValveRbndFR "Air suspension controller: a168 damper valve rbnd FR";
CM_ SG_ 852 TAS_a169_damperValveCompRL "Air suspension controller: a169 damper valve comp RL";
CM_ SG_ 852 TAS_a170_damperValveRbndRL "Air suspension controller: a170 damper valve rbnd RL";
CM_ SG_ 852 TAS_a171_damperValveCompRR "Air suspension controller: a171 damper valve comp RR";
CM_ SG_ 852 TAS_a172_damperValveRbndRR "Air suspension controller: a172 damper valve rbnd RR";
CM_ SG_ 852 TAS_a173_staticLeakDetectFL "Air suspension controller: a173 static leak detect FL";
CM_ SG_ 852 TAS_a174_staticLeakDetectFR "Air suspension controller: a174 static leak detect FR";
CM_ SG_ 852 TAS_a175_staticLeakDetectRL "Air suspension controller: a175 static leak detect RL";
CM_ SG_ 852 TAS_a176_staticLeakDetectRR "Air suspension controller: a176 static leak detect RR";
CM_ SG_ 852 TAS_a190_a2bFrontAxleFault "Air suspension controller: a190 a2b front axle fault";
CM_ SG_ 852 TAS_a191_a2bRearAxleFault "Air suspension controller: a191 a2b rear axle fault";
CM_ SG_ 852 TAS_a192_rideHeightObserverDiver "Air suspension controller: a192 ride height observer divergence";
CM_ SG_ 852 TAS_a193_EPAS3P_MIA "Air suspension controller: a193 EPAS3 p MIA";
CM_ SG_ 852 TAS_a194_a2bFrontAxleDataError "Air suspension controller: a194 a2b front axle data error";
CM_ SG_ 852 TAS_a195_a2bRearAxleDataError "Air suspension controller: a195 a2b rear axle data error";
CM_ SG_ 852 TAS_a196_adaptiveDampingUsingDSP "Air suspension controller: a196 adaptive damping using DSP";
CM_ SG_ 852 TAS_a197_invalidAdaptiveModeRequ "Air suspension controller: a197 invalid adaptive mode requested";
CM_ SG_ 852 TAS_a198_a2bFrontAxleExtendedDis "Air suspension controller: a198 a2b front axle extended discovery time";
CM_ SG_ 852 TAS_a199_a2bRearAxleExtendedDisc "Air suspension controller: a199 a2b rear axle extended discovery time";
CM_ SG_ 852 TAS_a200_jackModeActive "Air suspension controller: a200 jack mode active";
CM_ SG_ 852 TAS_a201_low12VBattery "Air suspension controller: a201 low12 v battery";
CM_ SG_ 852 TAS_a210_outOfRangeCalibration "Air suspension controller: a210 out of range calibration";
CM_ SG_ 852 TAS_a211_noRideHeightCalib "Air suspension controller: a211 no ride height calib";
CM_ SG_ 852 TAS_a213_yellowWarningLamp "Air suspension controller: a213 yellow warning lamp";
CM_ SG_ 852 TAS_a214_redWarningLamp "Air suspension controller: a214 red warning lamp";
CM_ SG_ 852 TAS_a215_limpHomeMode10 "Air suspension controller: a215 limp home mode10";
CM_ SG_ 852 TAS_a216_limpHomeMode20 "Air suspension controller: a216 limp home mode20";
CM_ SG_ 852 TAS_a217_limpHomeMode30 "Air suspension controller: a217 limp home mode30";
CM_ SG_ 852 TAS_a218_limpHomeMode40 "Air suspension controller: a218 limp home mode40";
CM_ SG_ 852 TAS_a220_exhaustGalleryFault "Air suspension controller: a220 exhaust gallery fault";
CM_ SG_ 852 TAS_a221_valveLeakDetected "Air suspension controller: a221 valve leak detected";
CM_ SG_ 852 TAS_a222_compressorPrefillFault "Air suspension controller: a222 compressor prefill fault";
CM_ SG_ 852 TAS_a223_blockedAirline "Air suspension controller: a223 blocked airline";
CM_ SG_ 852 TAS_a224_openAirline "Air suspension controller: a224 open airline";
CM_ SG_ 852 TAS_a225_galleryPressureTooHigh "Air suspension controller: a225 gallery pressure too high";
CM_ SG_ 852 TAS_a226_PWMfastDetectFL "Air suspension controller: a226 PW mfast detect FL";
CM_ SG_ 852 TAS_a227_PWMfastDetectFR "Air suspension controller: a227 PW mfast detect FR";
CM_ SG_ 852 TAS_a228_PWMfastDetectRL "Air suspension controller: a228 PW mfast detect RL";
CM_ SG_ 852 TAS_a229_PWMfastDetectRR "Air suspension controller: a229 PW mfast detect RR";
CM_ SG_ 852 TAS_a230_notifyGeofence "Air suspension controller: a230 notify geofence";
CM_ SG_ 852 TAS_a231_notifyRoughRoadRaise "Air suspension controller: a231 notify rough road raise";
CM_ SG_ 852 TAS_a232_suspensionTypeMismatch "Air suspension controller: a232 suspension type mismatch";
CM_ SG_ 852 TAS_a233_compressorStuckOn "Air suspension controller: a233 compressor stuck on";
CM_ SG_ 852 TAS_a234_damperHydraulicMismatch "Air suspension controller: a234 damper hydraulic mismatch";
CM_ SG_ 852 TAS_a240_airSpringLeak "Air suspension controller: a240 air spring leak";
CM_ SG_ 852 TAS_a284_serviceRunModeActive "Air suspension controller: a284 service run mode active";
CM_ SG_ 852 TAS_a285_twistSustainedUserVis "Air suspension controller: a285 twist sustained user vis";
CM_ SG_ 852 TAS_a286_driveCycleStats1 "Air suspension controller: a286 drive cycle stats1";
CM_ SG_ 852 TAS_a287_driveCycleStats2 "Air suspension controller: a287 drive cycle stats2";
CM_ SG_ 852 TAS_a288_driveCycleStats3 "Air suspension controller: a288 drive cycle stats3";
CM_ SG_ 852 TAS_a289_driveCycleStats4 "Air suspension controller: a289 drive cycle stats4";
CM_ SG_ 852 TAS_a290_twistSustainedAtSpeed "Air suspension controller: a290 twist sustained at speed";
CM_ SG_ 852 TAS_a291_frontAxleTooHigh "Air suspension controller: a291 front axle too high";
CM_ SG_ 852 TAS_a292_rearAxleTooHigh "Air suspension controller: a292 rear axle too high";
CM_ SG_ 852 TAS_a293_frontAxleTooLow "Air suspension controller: a293 front axle too low";
CM_ SG_ 852 TAS_a294_rearAxleTooLow "Air suspension controller: a294 rear axle too low";
CM_ SG_ 852 TAS_a295_targetHeightNotMet "Air suspension controller: a295 target height not met";
CM_ SG_ 852 TAS_a296_chassisTypeMismatch "Air suspension controller: a296 chassis type mismatch";
CM_ SG_ 852 TAS_a297_vinMismatch "Air suspension controller: a297 vin mismatch";
CM_ SG_ 852 TAS_a298_vinNotLearned "Air suspension controller: a298 vin not learned";
CM_ SG_ 852 TAS_a299_offsetEstimateTooLarge "Air suspension controller: a299 offset estimate too large";
CM_ SG_ 852 TAS_a300_offsetEstimateData1 "Air suspension controller: a300 offset estimate data1";
CM_ SG_ 852 TAS_a301_offsetEstimateData2 "Air suspension controller: a301 offset estimate data2";
CM_ SG_ 852 TAS_a303_massEstimateFrozen "Air suspension controller: a303 mass estimate frozen";
CM_ SG_ 852 TAS_a304_massEstimateFrozenData "Air suspension controller: a304 mass estimate frozen data";
CM_ SG_ 852 TAS_a305_newEndstopPosition "Air suspension controller: a305 new endstop position";
CM_ SG_ 852 TAS_a306_hardwareProtectFrozen "Air suspension controller: a306 hardware protect frozen";
CM_ SG_ 852 TAS_a307_endstopBoundaryComp "Air suspension controller: a307 endstop boundary comp";
CM_ SG_ 852 TAS_a308_endstopBoundaryRbnd "Air suspension controller: a308 endstop boundary rbnd";
CM_ SG_ 852 TAS_a309_controlFrozen "Air suspension controller: a309 control frozen";
CM_ SG_ 852 TAS_a310_controlFrozenData "Air suspension controller: a310 control frozen data";
CM_ SG_ 852 TAS_a311_accelsMIA "Air suspension controller: a311 accels MIA";
CM_ SG_ 852 TAS_a312_rotationalRatesMIA "Air suspension controller: a312 rotational rates MIA";
CM_ SG_ 852 TAS_a313_dampingCntrlDisabled "Air suspension controller: a313 damping cntrl disabled";
CM_ SG_ 852 TAS_a314_dampingReduced "Air suspension controller: a314 damping reduced";
CM_ SG_ 852 TAS_a315_pcbaHighTemp "Air suspension controller: a315 pcba high temp";
CM_ SG_ 852 TAS_a316_offsetsAccels "Air suspension controller: a316 offsets accels";
CM_ SG_ 852 TAS_a317_offsetsRotationalRates "Air suspension controller: a317 offsets rotational rates";
CM_ SG_ 852 TAS_a318_dampingCntrlInputMIA "Air suspension controller: a318 damping cntrl input MIA";
CM_ SG_ 852 TAS_a319_drivetrainTypeMismatch "Air suspension controller: a319 drivetrain type mismatch";
CM_ SG_ 852 TAS_a320_offsetsRotationalRates "Air suspension controller: a320 offsets rotational rates";
CM_ SG_ 852 TAS_a321_speedBumpAttributes1 "Air suspension controller: a321 speed bump attributes1";
CM_ SG_ 852 TAS_a322_speedBumpAttributes2 "Air suspension controller: a322 speed bump attributes2";
CM_ SG_ 852 TAS_a332_levelingThresholds1 "Air suspension controller: a332 leveling thresholds1";
CM_ SG_ 852 TAS_a333_levelingThresholds2 "Air suspension controller: a333 leveling thresholds2";
CM_ SG_ 852 TAS_a343_damperValveControlCompF "Air suspension controller: a343 damper valve control comp FL";
CM_ SG_ 852 TAS_a344_damperValveControlRbndF "Air suspension controller: a344 damper valve control rbnd FL";
CM_ SG_ 852 TAS_a345_damperValveControlCompF "Air suspension controller: a345 damper valve control comp FR";
CM_ SG_ 852 TAS_a346_damperValveControlRbndF "Air suspension controller: a346 damper valve control rbnd FR";
CM_ SG_ 852 TAS_a347_damperValveControlCompR "Air suspension controller: a347 damper valve control comp RL";
CM_ SG_ 852 TAS_a348_damperValveControlRbndR "Air suspension controller: a348 damper valve control rbnd RL";
CM_ SG_ 852 TAS_a349_damperValveControlCompR "Air suspension controller: a349 damper valve control comp RR";
CM_ SG_ 852 TAS_a350_damperValveControlRbndR "Air suspension controller: a350 damper valve control rbnd RR";
CM_ BO_ 523 "Air suspension controller message: axle data; frame length from the layout, not yet observed on a vehicle bus";
CM_ SG_ 523 TAS_axleIndex "Air suspension controller: axle index";
CM_ SG_ 523 TAS_rawHeightFL "Current height of the FL air spring; raw 1023 = signal not available (SNA)";
CM_ SG_ 523 TAS_staticHeightEstimateFL "Current static height estimate of the FL air spring; raw 1023 = signal not available (SNA)";
CM_ SG_ 523 TAS_componentPressureFL "Current static pressure of the FL air spring; raw 255 = signal not available (SNA)";
CM_ SG_ 523 TAS_rawHeightFR "Current height of the FR air spring; raw 1023 = signal not available (SNA)";
CM_ SG_ 523 TAS_staticHeightEstimateFR "Current static height estimate of the FR air spring; raw 1023 = signal not available (SNA)";
CM_ SG_ 523 TAS_componentPressureFR "Current static pressure of the FR air spring; raw 255 = signal not available (SNA)";
CM_ SG_ 523 TAS_rawHeightRL "Current height of the RL air spring; raw 1023 = signal not available (SNA)";
CM_ SG_ 523 TAS_staticHeightEstimateRL "Current static height estimate of the RL air spring; raw 1023 = signal not available (SNA)";
CM_ SG_ 523 TAS_componentPressureRL "Current static pressure of the RL air spring; raw 255 = signal not available (SNA)";
CM_ SG_ 523 TAS_rawHeightRR "Current height of the RR air spring; raw 1023 = signal not available (SNA)";
CM_ SG_ 523 TAS_staticHeightEstimateRR "Current static height estimate of the RR air spring; raw 1023 = signal not available (SNA)";
CM_ SG_ 523 TAS_componentPressureRR "Current static pressure of the RR air spring; raw 255 = signal not available (SNA)";
CM_ BO_ 1398 "Air suspension controller message: damping states; frame length from the layout, not yet observed on a vehicle bus";
CM_ SG_ 1398 TAS_endstopState "Air suspension controller: endstop state";
CM_ SG_ 1398 TAS_continuousControlState "SW-237496";
CM_ SG_ 1398 TAS_activeTireTune "Air suspension controller: active tire tune";
CM_ SG_ 1398 TAS_roughnessRaiseReason "Air suspension controller: roughness raise reason";
CM_ SG_ 1398 TAS_frontMetricDrivesRear "Air suspension controller: front metric drives rear";
CM_ SG_ 1398 TAS_roadCondition "Air suspension controller: road condition; raw 255 = signal not available (SNA)";
CM_ SG_ 1398 TAS_bellyProtect "Air suspension controller: belly protect";
CM_ SG_ 1398 TAS_frontMetricDrivesFront "Air suspension controller: front metric drives front";
CM_ SG_ 1398 TAS_speedBumpAxleFront "Air suspension controller: speed bump axle front";
CM_ SG_ 1398 TAS_speedBumpAxleRear "Air suspension controller: speed bump axle rear";
CM_ SG_ 1398 TAS_holeProtectFL "Air suspension controller: hole protect FL";
CM_ SG_ 1398 TAS_holeProtectFR "Air suspension controller: hole protect FR";
CM_ SG_ 1398 TAS_holeProtectRL "Air suspension controller: hole protect RL";
CM_ SG_ 1398 TAS_holeProtectRR "Air suspension controller: hole protect RR";
CM_ SG_ 1398 TAS_stepProtectFL "Air suspension controller: step protect FL";
CM_ SG_ 1398 TAS_stepProtectFR "Air suspension controller: step protect FR";
CM_ SG_ 1398 TAS_stepProtectRL "Air suspension controller: step protect RL";
CM_ SG_ 1398 TAS_stepProtectRR "Air suspension controller: step protect RR";
CM_ SG_ 1398 TAS_FDUTorqueCorruptionScale "Air suspension controller: FDU torque corruption scale; raw 15 = signal not available (SNA)";
CM_ SG_ 1398 TAS_sprungMassEstimate "Air suspension controller: sprung mass estimate; raw 31 = signal not available (SNA)";
CM_ SG_ 1398 TAS_anyDamperActive "Air suspension controller: any damper active";
CM_ SG_ 1398 TAS_dampingStatesCounter "Air suspension controller: damping states counter";
CM_ SG_ 1398 TAS_dampingStatesChecksum "Air suspension controller: damping states checksum";
CM_ BO_ 1357 "Air suspension controller message: info; frame length from the layout, not yet observed on a vehicle bus";
CM_ SG_ 1357 TAS_infoIndex "Air suspension controller: info index";
CM_ SG_ 1357 TAS_infoBuildType "Air suspension controller: info build type";
CM_ SG_ 1357 TAS_infoBuildConfigId "Air suspension controller: info build config id";
CM_ SG_ 1357 TAS_infoHardwareId "Air suspension controller: info hardware id";
CM_ SG_ 1357 TAS_infoComponentId "Air suspension controller: info component id";
CM_ SG_ 1357 TAS_infoPcbaId "Air suspension controller: info pcba id";
CM_ SG_ 1357 TAS_infoAssemblyId "Air suspension controller: info assembly id; raw 255 = signal not available (SNA)";
CM_ SG_ 1357 TAS_infoUsageId "Air suspension controller: info usage id";
CM_ SG_ 1357 TAS_infoSubUsageId "Air suspension controller: info sub usage id";
CM_ SG_ 1357 TAS_infoAppCrc "Air suspension controller: info app crc";
CM_ SG_ 1357 TAS_infoAppGitHash "Air suspension controller: info app git hash";
CM_ SG_ 1357 TAS_infoBootGitHash "Air suspension controller: info boot git hash";
CM_ SG_ 1357 TAS_infoPlatformType "Air suspension controller: info platform type";
CM_ SG_ 1357 TAS_infoMajorVersion "Air suspension controller: info major version; raw 255 = signal not available (SNA)";
CM_ SG_ 1357 TAS_infoBranchOrigin "Air suspension controller: info branch origin; raw 255 = signal not available (SNA)";
CM_ SG_ 1357 TAS_infoMaturity "Air suspension controller: info maturity; raw 255 = signal not available (SNA)";
CM_ SG_ 1357 TAS_infoHardwareRevision "Air suspension controller: info hardware revision; raw 255 = signal not available (SNA)";
CM_ BO_ 525 "Air suspension controller message: states; frame length from the layout, not yet observed on a vehicle bus";
CM_ SG_ 525 TAS_levelingState "Indicates air suspension leveling state.";
CM_ SG_ 525 TAS_levelingItem "Indicates the currently active air suspension components.";
CM_ SG_ 525 TAS_pressureGallery "Current air suspension valve block gallery pressure; raw 255 = signal not available (SNA)";
CM_ SG_ 525 TAS_pressureReservoir "Indicates the latest valid reservoir pressure; raw 255 = signal not available (SNA)";
CM_ SG_ 525 TAS_runMode "Indicates the status of run mode.";
CM_ SG_ 525 TAS_filterMode "Indicates the status of filter mode.";
CM_ SG_ 525 TAS_compressorRun "Either an indication that the compressor is running or a request to run the air compressor";
CM_ SG_ 525 TAS_twistDetected "TAS has detected large amount of twist.";
CM_ SG_ 525 TAS_leanDetected "TAS has detected vehicle to be leaning left or right.";
CM_ SG_ 525 TAS_limpHomeMode "Indicates which limp home mode is active.";
CM_ SG_ 525 TAS_targetLevel "Indicates target ride height.";
CM_ SG_ 525 TAS_currentLevel "Indicates current ride height.";
CM_ SG_ 525 TAS_jackMode "Indicates the status of Jack mode.";
CM_ SG_ 525 TAS_reduceVehicleSpeedRequest "Air suspension controller: reduce vehicle speed request";
CM_ SG_ 525 TAS_statesCounter "Air suspension controller: states counter";
CM_ SG_ 525 TAS_statesChecksum "Air suspension controller: states checksum";
CM_ BO_ 1627 "Air suspension controller message: uds response; frame length from the layout, not yet observed on a vehicle bus";
CM_ SG_ 1627 TAS_udsResponseData "Air suspension controller: uds response data";
CM_ BO_ 409 "Air suspension controller message: ui adaptive activity0; frame length from the layout, not yet observed on a vehicle bus";
CM_ SG_ 409 TAS_adaptiveActivityFL_C "Air suspension controller: adaptive activity FL c; raw 31 = signal not available (SNA)";
CM_ SG_ 409 TAS_adaptiveActivityFL_R "Air suspension controller: adaptive activity FL r; raw 31 = signal not available (SNA)";
CM_ SG_ 409 TAS_adaptiveActivityFR_C "Air suspension controller: adaptive activity FR c; raw 31 = signal not available (SNA)";
CM_ SG_ 409 TAS_adaptiveActivityFR_R "Air suspension controller: adaptive activity FR r; raw 31 = signal not available (SNA)";
CM_ SG_ 409 TAS_adaptiveActivityRL_C "Air suspension controller: adaptive activity RL c; raw 31 = signal not available (SNA)";
CM_ SG_ 409 TAS_adaptiveActivityRL_R "Air suspension controller: adaptive activity RL r; raw 31 = signal not available (SNA)";
CM_ SG_ 409 TAS_adaptiveActivityRR_C "Air suspension controller: adaptive activity RR c; raw 31 = signal not available (SNA)";
CM_ SG_ 409 TAS_adaptiveActivityRR_R "Air suspension controller: adaptive activity RR r; raw 31 = signal not available (SNA)";
CM_ SG_ 409 TAS_uiHeightFL "Air suspension controller: ui height FL; raw 63 = signal not available (SNA)";
CM_ SG_ 409 TAS_uiHeightFR "Air suspension controller: ui height FR; raw 63 = signal not available (SNA)";
CM_ SG_ 409 TAS_uiHeightRL "Air suspension controller: ui height RL; raw 63 = signal not available (SNA)";
CM_ SG_ 409 TAS_uiHeightRR "Air suspension controller: ui height RR; raw 63 = signal not available (SNA)";
CM_ BO_ 410 "Air suspension controller message: ui adaptive activity1; frame length from the layout, not yet observed on a vehicle bus";
CM_ SG_ 410 TAS_bodyAccelFL "Air suspension controller: body accel FL; raw 255 = signal not available (SNA)";
CM_ SG_ 410 TAS_bodyAccelFR "Air suspension controller: body accel FR; raw 255 = signal not available (SNA)";
CM_ SG_ 410 TAS_bodyAccelRL "Air suspension controller: body accel RL; raw 255 = signal not available (SNA)";
CM_ SG_ 410 TAS_bodyAccelRR "Air suspension controller: body accel RR; raw 255 = signal not available (SNA)";
CM_ BO_ 538 "Air suspension controller message: ui control; frame length from the layout, not yet observed on a vehicle bus";
CM_ SG_ 538 TAS_yellowWarningLamp "Air suspension controller: yellow warning lamp";
CM_ SG_ 538 TAS_redWarningLamp "Air suspension controller: red warning lamp";
CM_ SG_ 538 TAS_veryLowAllowed "Air suspension controller: very low allowed";
CM_ SG_ 538 TAS_lowAllowed "Air suspension controller: low allowed";
CM_ SG_ 538 TAS_standardAllowed "Air suspension controller: standard allowed";
CM_ SG_ 538 TAS_highAllowed "Air suspension controller: high allowed";
CM_ SG_ 538 TAS_veryHighAllowed "Air suspension controller: very high allowed";
CM_ SG_ 538 TAS_extractAllowed "Air suspension controller: extract allowed";
CM_ SG_ 538 TAS_showSpinner "Air suspension controller: show spinner";
CM_ SG_ 538 TAS_adaptiveRideModeOverride "Air suspension controller: adaptive ride mode override; raw 3 = signal not available (SNA)";
CM_ SG_ 538 TAS_levelSelectEnabled "Air suspension controller: level select enabled";
CM_ SG_ 538 TAS_jackModeToggleEnabled "Air suspension controller: jack mode toggle enabled";
CM_ SG_ 538 TAS_adaptiveRideSelectEnabled "Air suspension controller: adaptive ride select enabled";
CM_ SG_ 538 TAS_launchModeState "Air suspension controller: launch mode state";
CM_ SG_ 538 TAS_restrictUpLevelingFalcons "Air suspension controller: restrict up leveling falcons";
CM_ SG_ 538 TAS_restrictUpLevelingTrunk "Air suspension controller: restrict up leveling trunk";
CM_ SG_ 538 TAS_restrictDownLevelingDoors "Air suspension controller: restrict down leveling doors";
CM_ SG_ 538 TAS_restrictLevelingChargeCable "Air suspension controller: restrict leveling charge cable";
CM_ SG_ 538 TAS_restrictLevelingSystemCheck "Air suspension controller: restrict leveling system check";
CM_ SG_ 538 TAS_restrictLevelingTransport "Air suspension controller: restrict leveling transport";
CM_ SG_ 538 TAS_restrictLevelingShowroom "Indication that up and down leveling are restricted while showroom mode is active.";
CM_ SG_ 538 TAS_uiControlCounter "Air suspension controller: ui control counter";
CM_ SG_ 538 TAS_uiControlChecksum "Air suspension controller: ui control checksum";
CM_ BO_ 1641 "UDS ECU message: KOSTI asccm request; forwarded onto this bus by the gateway; frame length from the layout, not yet observed on a vehicle bus";
CM_ SG_ 1641 UDS_KOSTIAsccmRequestData "UDS ECU: KOSTI asccm request data";
CM_ BO_ 1538 "UDS ECU message: bms request; forwarded onto this bus by the gateway; frame length from the layout, not yet observed on a vehicle bus";
CM_ SG_ 1538 UDS_bmsRequestData "UDS ECU: bms request data";
CM_ BO_ 1579 "UDS ECU message: cc request; forwarded onto this bus by the gateway; frame length from the layout, not yet observed on a vehicle bus";
CM_ SG_ 1579 UDS_ccRequestData "UDS ECU: cc request data";
CM_ BO_ 1539 "UDS ECU message: cmp request; forwarded onto this bus by the gateway; frame length from the layout, not yet observed on a vehicle bus";
CM_ SG_ 1539 UDS_cmpRequestData "UDS ECU: cmp request data";
CM_ BO_ 1543 "UDS ECU message: cmpd request; forwarded onto this bus by the gateway; frame length from the layout, not yet observed on a vehicle bus";
CM_ SG_ 1543 UDS_cmpdRequestData "UDS ECU: cmpd request data";
CM_ BO_ 1550 "UDS ECU message: cp request; forwarded onto this bus by the gateway; frame length from the layout, not yet observed on a vehicle bus";
CM_ SG_ 1550 UDS_cpRequestData "UDS ECU: cp request data";
CM_ BO_ 1589 "UDS ECU message: di request; forwarded onto this bus by the gateway; frame length from the layout, not yet observed on a vehicle bus";
CM_ SG_ 1589 UDS_diRequestData "UDS ECU: di request data";
CM_ BO_ 1541 "UDS ECU message: dif request; forwarded onto this bus by the gateway; frame length from the layout, not yet observed on a vehicle bus";
CM_ SG_ 1541 UDS_difRequestData "UDS ECU: dif request data";
CM_ BO_ 1542 "UDS ECU message: dir request; forwarded onto this bus by the gateway; frame length from the layout, not yet observed on a vehicle bus";
CM_ SG_ 1542 UDS_dirRequestData "UDS ECU: dir request data";
CM_ BO_ 1572 "UDS ECU message: epbl request; forwarded onto this bus by the gateway; frame length from the layout, not yet observed on a vehicle bus";
CM_ SG_ 1572 UDS_epblRequestData_H "UDS ECU: epbl request data h";
CM_ SG_ 1572 UDS_epblRequestData_L "UDS ECU: epbl request data l";
CM_ BO_ 1574 "UDS ECU message: epbr request; forwarded onto this bus by the gateway; frame length from the layout, not yet observed on a vehicle bus";
CM_ SG_ 1574 UDS_epbrRequestData_H "UDS ECU: epbr request data h";
CM_ SG_ 1574 UDS_epbrRequestData_L "UDS ECU: epbr request data l";
CM_ BO_ 2015 "UDS ECU message: functional request; forwarded onto this bus by the gateway; frame length from the layout, not yet observed on a vehicle bus";
CM_ SG_ 2015 UDS_functionalRequestData_0 "UDS ECU: functional request data 0";
CM_ SG_ 2015 UDS_functionalRequestData_1 "UDS ECU: functional request data 1";
CM_ SG_ 2015 UDS_functionalRequestData_2 "UDS ECU: functional request data 2";
CM_ SG_ 2015 UDS_functionalRequestData_3 "UDS ECU: functional request data 3";
CM_ SG_ 2015 UDS_functionalRequestData_4 "UDS ECU: functional request data 4";
CM_ SG_ 2015 UDS_functionalRequestData_5 "UDS ECU: functional request data 5";
CM_ SG_ 2015 UDS_functionalRequestData_6 "UDS ECU: functional request data 6";
CM_ SG_ 2015 UDS_functionalRequestData_7 "UDS ECU: functional request data 7";
CM_ BO_ 1552 "UDS ECU message: hvp request; forwarded onto this bus by the gateway; frame length from the layout, not yet observed on a vehicle bus";
CM_ SG_ 1552 UDS_hvpRequestData "UDS ECU: hvp request data";
CM_ BO_ 1560 "UDS ECU message: icr request; forwarded onto this bus by the gateway; frame length from the layout, not yet observed on a vehicle bus";
CM_ SG_ 1560 UDS_icrRequestData "UDS ECU: icr request data";
CM_ BO_ 1576 "UDS ECU message: pcs request; forwarded onto this bus by the gateway; frame length from the layout, not yet observed on a vehicle bus";
CM_ SG_ 1576 UDS_pcsRequestData "UDS ECU: pcs request data";
CM_ BO_ 1634 "UDS ECU message: plg request; forwarded onto this bus by the gateway; frame length from the layout, not yet observed on a vehicle bus";
CM_ SG_ 1634 UDS_plgRequestData "UDS ECU: plg request data";
CM_ BO_ 1568 "UDS ECU message: pm request; forwarded onto this bus by the gateway; frame length from the layout, not yet observed on a vehicle bus";
CM_ SG_ 1568 UDS_pmRequestData "UDS ECU: pm request data";
CM_ BO_ 1604 "UDS ECU message: pmf request; forwarded onto this bus by the gateway; frame length from the layout, not yet observed on a vehicle bus";
CM_ SG_ 1604 UDS_pmfRequestData "UDS ECU: pmf request data";
CM_ BO_ 1540 "UDS ECU message: pmr request; forwarded onto this bus by the gateway; frame length from the layout, not yet observed on a vehicle bus";
CM_ SG_ 1540 UDS_pmrRequestData "UDS ECU: pmr request data";
CM_ BO_ 1734 "UDS ECU message: ptc request; forwarded onto this bus by the gateway; frame length from the layout, not yet observed on a vehicle bus";
CM_ SG_ 1734 UDS_ptcRequestData "UDS ECU: ptc request data";
CM_ BO_ 1664 "UDS ECU message: sccm request; forwarded onto this bus by the gateway; frame length from the layout, not yet observed on a vehicle bus";
CM_ SG_ 1664 UDS_sccmRequestData "UDS ECU: sccm request data";
CM_ BO_ 1723 "UDS ECU message: sdcr request; forwarded onto this bus by the gateway; frame length from the layout, not yet observed on a vehicle bus";
CM_ SG_ 1723 UDS_sdcrRequestData "UDS ECU: sdcr request data";
CM_ BO_ 1611 "UDS ECU message: tas request; forwarded onto this bus by the gateway; frame length from the layout, not yet observed on a vehicle bus";
CM_ SG_ 1611 UDS_tasRequestData "UDS ECU: tas request data";
CM_ BO_ 1548 "UDS ECU message: vcbatt1 request; forwarded onto this bus by the gateway; frame length from the layout, not yet observed on a vehicle bus";
CM_ SG_ 1548 UDS_vcbatt1RequestData "UDS ECU: vcbatt1 request data";
CM_ BO_ 1562 "UDS ECU message: vcbatt2 request; forwarded onto this bus by the gateway; frame length from the layout, not yet observed on a vehicle bus";
CM_ SG_ 1562 UDS_vcbatt2RequestData "UDS ECU: vcbatt2 request data";
CM_ BO_ 1633 "UDS ECU message: vcbatt request; forwarded onto this bus by the gateway; frame length from the layout, not yet observed on a vehicle bus";
CM_ SG_ 1633 UDS_vcbattRequestData "UDS ECU: vcbatt request data";
CM_ BO_ 1580 "UDS ECU message: vcfront1 request; forwarded onto this bus by the gateway; frame length from the layout, not yet observed on a vehicle bus";
CM_ SG_ 1580 UDS_vcfront1RequestData "UDS ECU: vcfront1 request data";
CM_ BO_ 1582 "UDS ECU message: vcfront2 request; forwarded onto this bus by the gateway; frame length from the layout, not yet observed on a vehicle bus";
CM_ SG_ 1582 UDS_vcfront2RequestData "UDS ECU: vcfront2 request data";
CM_ BO_ 1536 "UDS ECU message: vcfront request; forwarded onto this bus by the gateway; frame length from the layout, not yet observed on a vehicle bus";
CM_ SG_ 1536 UDS_vcfrontRequestData "UDS ECU: vcfront request data";
CM_ BO_ 1570 "UDS ECU message: vcleft request; forwarded onto this bus by the gateway; frame length from the layout, not yet observed on a vehicle bus";
CM_ SG_ 1570 UDS_vcleftRequestData_H "UDS ECU: vcleft request data h";
CM_ SG_ 1570 UDS_vcleftRequestData_L "UDS ECU: vcleft request data l";
CM_ BO_ 1544 "UDS ECU message: vcright request; forwarded onto this bus by the gateway; frame length from the layout, not yet observed on a vehicle bus";
CM_ SG_ 1544 UDS_vcrightRequestData_H "UDS ECU: vcright request data h";
CM_ SG_ 1544 UDS_vcrightRequestData_L "UDS ECU: vcright request data l";
CM_ BO_ 1546 "UDS ECU message: vcsec request; forwarded onto this bus by the gateway; frame length from the layout, not yet observed on a vehicle bus";
CM_ SG_ 1546 UDS_vcsecRequestData "UDS ECU: vcsec request data";
CM_ BO_ 1154 "Touchscreen user interface computer message: iso tp pipe remote VCSEC; forwarded onto this bus by the gateway; frame length observed on a vehicle bus";
CM_ SG_ 1154 UI_IsoTpRemoteVCSEC0 "Touchscreen user interface computer: iso tp remote VCSEC0";
CM_ SG_ 1154 UI_IsoTpRemoteVCSEC1 "Touchscreen user interface computer: iso tp remote VCSEC1";
CM_ SG_ 1154 UI_IsoTpRemoteVCSEC2 "Touchscreen user interface computer: iso tp remote VCSEC2";
CM_ SG_ 1154 UI_IsoTpRemoteVCSEC3 "Touchscreen user interface computer: iso tp remote VCSEC3";
CM_ SG_ 1154 UI_IsoTpRemoteVCSEC4 "Touchscreen user interface computer: iso tp remote VCSEC4";
CM_ SG_ 1154 UI_IsoTpRemoteVCSEC5 "Touchscreen user interface computer: iso tp remote VCSEC5";
CM_ SG_ 1154 UI_IsoTpRemoteVCSEC6 "Touchscreen user interface computer: iso tp remote VCSEC6";
CM_ SG_ 1154 UI_IsoTpRemoteVCSEC7 "Touchscreen user interface computer: iso tp remote VCSEC7";
CM_ BO_ 1153 "Touchscreen user interface computer message: iso tp UDP pipe VCSEC; forwarded onto this bus by the gateway; frame length from the layout, not yet observed on a vehicle bus";
CM_ SG_ 1153 UI_IsoTpUDPPipeVCSEC0 "Touchscreen user interface computer: iso tp UDP pipe VCSEC0";
CM_ SG_ 1153 UI_IsoTpUDPPipeVCSEC1 "Touchscreen user interface computer: iso tp UDP pipe VCSEC1";
CM_ SG_ 1153 UI_IsoTpUDPPipeVCSEC2 "Touchscreen user interface computer: iso tp UDP pipe VCSEC2";
CM_ SG_ 1153 UI_IsoTpUDPPipeVCSEC3 "Touchscreen user interface computer: iso tp UDP pipe VCSEC3";
CM_ SG_ 1153 UI_IsoTpUDPPipeVCSEC4 "Touchscreen user interface computer: iso tp UDP pipe VCSEC4";
CM_ SG_ 1153 UI_IsoTpUDPPipeVCSEC5 "Touchscreen user interface computer: iso tp UDP pipe VCSEC5";
CM_ SG_ 1153 UI_IsoTpUDPPipeVCSEC6 "Touchscreen user interface computer: iso tp UDP pipe VCSEC6";
CM_ SG_ 1153 UI_IsoTpUDPPipeVCSEC7 "Touchscreen user interface computer: iso tp UDP pipe VCSEC7";
CM_ BO_ 1657 "Touchscreen user interface computer message: ambient lighting ctrls; forwarded onto this bus by the gateway; frame length from the layout, not yet observed on a vehicle bus";
CM_ SG_ 1657 UI_ambientLightPowerOverride "Touchscreen user interface computer: ambient light power override";
CM_ SG_ 1657 UI_rgbEnableState "Request to enable RGB lights";
CM_ SG_ 1657 UI_rgbEffectType "Reports the RGB light effect type.";
CM_ SG_ 1657 UI_rgbLightingColorHexRed "Touchscreen user interface computer: rgb lighting color hex red";
CM_ SG_ 1657 UI_rgbLightingColorHexGreen "Touchscreen user interface computer: rgb lighting color hex green";
CM_ SG_ 1657 UI_rgbLightingColorHexBlue "Touchscreen user interface computer: rgb lighting color hex blue";
CM_ SG_ 1657 UI_rgbBrightnessLevel "Reports the requested RGB brightness level; raw 127 = signal not available (SNA)";
CM_ SG_ 1657 UI_audioVisualizerState "Request to enable RGB lights.";
CM_ SG_ 1657 UI_rgbTargetDOORFL "Target RGB control for front left door";
CM_ SG_ 1657 UI_rgbTargetDOORFR "Target RGB control for the front right door";
CM_ SG_ 1657 UI_rgbTargetDOORRL "Target RGB control for rear left door";
CM_ SG_ 1657 UI_rgbTargetDOORRR "Target RGB control for the rear right door";
CM_ SG_ 1657 UI_rgbTargetIPFL "Reports control for RGB lighting for the front left instrument panel.";
CM_ SG_ 1657 UI_rgbTargetIPFR "Reports control for RGB lighting for the front right instrument panel.";
CM_ BO_ 1021 "Touchscreen user interface computer message: autopilot control; forwarded onto this bus by the gateway; frame length observed on a vehicle bus";
CM_ SG_ 1021 UI_autopilotControlIndex "Touchscreen user interface computer: autopilot control index";
CM_ SG_ 1021 UI_hovEnabled "UI HOV routes enabled";
CM_ SG_ 1021 UI_donDisableAutoWiperDuration "Touchscreen user interface computer: don disable auto wiper duration";
CM_ SG_ 1021 UI_donDisableOnAutoWiperSpeed "Touchscreen user interface computer: don disable on auto wiper speed";
CM_ SG_ 1021 UI_blindspotMinSpeed "Touchscreen user interface computer: blindspot min speed";
CM_ SG_ 1021 UI_blindspotDistance "Touchscreen user interface computer: blindspot distance";
CM_ SG_ 1021 UI_blindspotTTC "Touchscreen user interface computer: blindspot TTC";
CM_ SG_ 1021 UI_donStopEndOfRampBuffer "Touchscreen user interface computer: don stop end of ramp buffer";
CM_ SG_ 1021 UI_donDisableCutin "Touchscreen user interface computer: don disable cutin";
CM_ SG_ 1021 UI_smartSetSpeedOffset "TACC will apply this offset over the speed limit";
CM_ SG_ 1021 UI_smartSetSpeedOffsetType "Offset applied will be a percentage or fixed value based on this setting";
CM_ SG_ 1021 UI_autopilotMonarchBackup "Touchscreen user interface computer: autopilot monarch backup";
CM_ SG_ 1021 UI_fsdVisualizationEnabled "Touchscreen user interface computer: fsd visualization enabled";
CM_ SG_ 1021 UI_fsdStopsControlEnabled "Indicates if autopilot control for traffic lights and stops signs has been enabled by the driver";
CM_ SG_ 1021 UI_fsdContinueOnGreenWithCIPV "Touchscreen user interface computer: fsd continue on green with CIPV";
CM_ SG_ 1021 UI_smartSetSpeed "TACC will use speed limit + offset as user set speed when enabled";
CM_ SG_ 1021 UI_automaticSetSpeedOffset "Maximum set speed offset would be determined automatically when this option is enabled";
CM_ SG_ 1021 UI_apply2021_1958_ISA "Touchscreen user interface computer: apply2021 1958 ISA";
CM_ SG_ 1021 UI_apply2021_646_ELKS "Touchscreen user interface computer: apply2021 646 ELKS";
CM_ SG_ 1021 UI_apply2021_1341_DDAW "Touchscreen user interface computer: apply2021 1341 DDAW";
CM_ SG_ 1021 UI_homelinkNearby "Touchscreen user interface computer: homelink nearby";
CM_ SG_ 1021 UI_enableFullSelfDriving "Indicates if the driver has enabled FSD behaviors";
CM_ SG_ 1021 UI_hasFullSelfDriving "Indicates if the vehicle hardware, software, and dependencies allow FSD";
CM_ SG_ 1021 UI_autosteerActivation "User-selected autosteer activation method";
CM_ SG_ 1021 UI_fsdBetaRequest "User accepted disclaimer and requested FSD (Supervised) builds";
CM_ SG_ 1021 UI_fullSelfDrivingSuspended "Full self driving is suspended";
CM_ SG_ 1021 UI_disableOptionalLaneChanges "Disable optional lane changes while FSD is controlling";
CM_ SG_ 1021 UI_applyR152_AEBS "Touchscreen user interface computer: apply R152 AEBS";
CM_ SG_ 1021 UI_applyDCASBehavior "Touchscreen user interface computer: apply DCAS behavior";
CM_ SG_ 1021 UI_applyDCASBehaviorLegacy "Touchscreen user interface computer: apply DCAS behavior legacy";
CM_ SG_ 1021 UI_applyADDWWarnings "ADDW warnings are enabled on this vehicle";
CM_ SG_ 1021 UI_autopilotControlMux0Valid "Touchscreen user interface computer: autopilot control mux0 valid";
CM_ SG_ 1021 UI_selectableCameraRequest "Infotainment selectable camera state request from AP signal; raw 15 = signal not available (SNA)";
CM_ SG_ 1021 UI_overrideSleepWithSuspend "Touchscreen user interface computer: override sleep with suspend";
CM_ SG_ 1021 UI_driverMonitorConfirmation "Driver attentiveness confirmation";
CM_ SG_ 1021 UI_parkAssistUseVision "Reports if the vehicle should use vision park assist.";
CM_ SG_ 1021 UI_applyEceR79 "Touchscreen user interface computer: apply ece R79";
CM_ SG_ 1021 UI_enableMapStops "Touchscreen user interface computer: enable map stops";
CM_ SG_ 1021 UI_disableMain "Touchscreen user interface computer: disable main";
CM_ SG_ 1021 UI_disableNarrow "Touchscreen user interface computer: disable narrow";
CM_ SG_ 1021 UI_disableFisheye "Touchscreen user interface computer: disable fisheye";
CM_ SG_ 1021 UI_disableLeftPillar "Touchscreen user interface computer: disable left pillar";
CM_ SG_ 1021 UI_disableRightPillar "Touchscreen user interface computer: disable right pillar";
CM_ SG_ 1021 UI_disableLeftRepeater "Touchscreen user interface computer: disable left repeater";
CM_ SG_ 1021 UI_disableRightRepeater "Touchscreen user interface computer: disable right repeater";
CM_ SG_ 1021 UI_disableBackup "Touchscreen user interface computer: disable backup";
CM_ SG_ 1021 UI_disableRadar "Touchscreen user interface computer: disable radar";
CM_ SG_ 1021 UI_noStalkConfirmAlertHaptic "Detects if alert haptic feedback should trigger.";
CM_ SG_ 1021 UI_regulatoryLKA "Touchscreen user interface computer: regulatory LKA";
CM_ SG_ 1021 UI_regulatoryLaneAssistLevel "Touchscreen user interface computer: regulatory lane assist level";
CM_ SG_ 1021 UI_ulcSnooze "Touchscreen user interface computer: ulc snooze";
CM_ SG_ 1021 UI_noStalkConfirmAlertChime "Detects if alert chime should trigger.";
CM_ SG_ 1021 UI_factorySummonEnable "Controls Factory Summon.";
CM_ SG_ 1021 UI_apmv3Branch "Touchscreen user interface computer: apmv3 branch";
CM_ SG_ 1021 UI_enableCabinCamera "Indicates if autopilot can enable cabin camera";
CM_ SG_ 1021 UI_enableAutopilotStopWarning "Enables the Autopilot active red light warning function.";
CM_ SG_ 1021 UI_showLaneGraph "Touchscreen user interface computer: show lane graph";
CM_ SG_ 1021 UI_showTrackLabels "Touchscreen user interface computer: show track labels";
CM_ SG_ 1021 UI_hardCoreSummon "Touchscreen user interface computer: hard core summon";
CM_ SG_ 1021 UI_enableCabinCameraTelemetry "Touchscreen user interface computer: enable cabin camera telemetry";
CM_ SG_ 1021 UI_enableVisionSpeedControl "Indicates if autopilot can enable vision speed control";
CM_ SG_ 1021 UI_autopilotTelemetryInChina "Touchscreen user interface computer: autopilot telemetry in china";
CM_ SG_ 1021 UI_enableTeslaAutopark "Indicates if autopilot can enable Telsa Autopark control";
CM_ SG_ 1021 UI_autoTurnSignalMode "Turn signal activation mode";
CM_ SG_ 1021 UI_enableCautionLightControl "Touchscreen user interface computer: enable caution light control";
CM_ SG_ 1021 UI_applyEceR79SmartSummonOnly "Touchscreen user interface computer: apply ece R79 smart summon only";
CM_ SG_ 1021 UI_autopilotMonarchEnabled "Touchscreen user interface computer: autopilot monarch enabled";
CM_ SG_ 1021 UI_autopilotEphemerisEnabled "Touchscreen user interface computer: autopilot ephemeris enabled";
CM_ SG_ 1021 UI_enableCabinAudioRecording "Indicates if autopilot can record cabin audio";
CM_ SG_ 1021 UI_autopilotControlMux1Valid "Touchscreen user interface computer: autopilot control mux1 valid";
CM_ SG_ 1021 UI_enableApproachingEmergencyVeh "Touchscreen user interface computer: enable approaching emergency vehicle detection";
CM_ SG_ 1021 UI_enableStartFsdFromParkBrakeCo "Touchscreen user interface computer: enable start fsd from park brake confirmation";
CM_ SG_ 1021 UI_enableStartFsdFromPark "Touchscreen user interface computer: enable start fsd from park";
CM_ SG_ 1021 UI_fsdMaxSpeedOffsetPercentage "Touchscreen user interface computer: fsd max speed offset percentage";
CM_ SG_ 1021 UI_calibrationReadyInFactory "Touchscreen user interface computer: calibration ready in factory";
CM_ SG_ 1021 UI_coldStartMonarchInFactory "Touchscreen user interface computer: cold start monarch in factory";
CM_ SG_ 1021 UI_navMinutesToArrival "Touchscreen user interface computer: nav minutes to arrival";
CM_ SG_ 1021 UI_fsdQuizRequired "Touchscreen user interface computer: fsd quiz required";
CM_ SG_ 1021 UI_fsdQuizPassed "Touchscreen user interface computer: fsd quiz passed";
CM_ SG_ 1021 UI_fsdAllowedInLocalizedRegion "Touchscreen user interface computer: fsd allowed in localized region";
CM_ SG_ 1021 UI_autopilotDrivingProfile "Driving profile for autopilot control";
CM_ SG_ 1021 UI_autopilotControlMux2Valid "Touchscreen user interface computer: autopilot control mux2 valid";
CM_ BO_ 819 "Touchscreen user interface computer message: charge request; forwarded onto this bus by the gateway; frame length observed on a vehicle bus";
CM_ SG_ 819 UI_openChargePortDoorRequest "Request to open charge port.";
CM_ SG_ 819 UI_closeChargePortDoorRequest "Request to close charge port.";
CM_ SG_ 819 UI_chargeEnableRequest "Charging request initiated";
CM_ SG_ 819 UI_brickVLoggingRequest "Touchscreen user interface computer: brick v logging request";
CM_ SG_ 819 UI_brickBalancingDisabled "Touchscreen user interface computer: brick balancing disabled";
CM_ SG_ 819 UI_acChargeCurrentLimit "UI charging line current request; raw 127 = signal not available (SNA)";
CM_ SG_ 819 UI_chargeTerminationPct "Charge Termination Limit Percent";
CM_ SG_ 819 UI_chargeFeature1 "Touchscreen user interface computer: charge feature1";
CM_ SG_ 819 UI_chargeFeature2 "Touchscreen user interface computer: charge feature2";
CM_ SG_ 819 UI_chargeFeature3 "Touchscreen user interface computer: charge feature3";
CM_ SG_ 819 UI_scheduledDepartureEnabled "Reports scheduled departure feature enablement.";
CM_ SG_ 819 UI_chargePortLatchRequest "Request to engage or disengage the latch.";
CM_ SG_ 819 UI_socSnapshotExpirationTime "Touchscreen user interface computer: soc snapshot expiration time";
CM_ SG_ 819 UI_cpInletHeaterRequest "Enable charge port inlet heater";
CM_ SG_ 819 UI_chargePowerSampleRequest "Touchscreen user interface computer: charge power sample request";
CM_ SG_ 819 UI_enableIso15118 "Touchscreen user interface computer: enable iso15118";
CM_ BO_ 659 "Touchscreen user interface computer message: chassis control; forwarded onto this bus by the gateway; frame length observed on a vehicle bus";
CM_ SG_ 659 UI_steeringTuneRequest "UI customer level request for steering feel. MS had comfort, normal, sport. M3 intent is Normal, sport see SW-95934";
CM_ SG_ 659 UI_tractionControlMode "Transport user selected traction control modes";
CM_ SG_ 659 UI_parkBrakeRequest "User selection for Park brake; raw 3 = signal not available (SNA)";
CM_ SG_ 659 UI_narrowGarages "Touchscreen user interface computer: narrow garages";
CM_ SG_ 659 UI_winchModeRequest "Winch mode (towing) request";
CM_ SG_ 659 UI_zeroSpeedConfirmed "Touchscreen user interface computer: zero speed confirmed; raw 3 = signal not available (SNA)";
CM_ SG_ 659 UI_trailerMode "Indicates whether trailer mode is selected. To be used when towing a trailer.";
CM_ SG_ 659 UI_distanceUnits "Touchscreen user interface computer: distance units";
CM_ SG_ 659 UI_dasDebugEnable "Touchscreen user interface computer: das debug enable";
CM_ SG_ 659 UI_accOvertakeEnable "Enable ACC Overtake assistance (reduce follow distance when the turn signal is on), UI firmware only sets datavalue to True; raw 3 = signal not available (SNA)";
CM_ SG_ 659 UI_aebEnable "Enable Autonomous Emergency Brakes; raw 3 = signal not available (SNA)";
CM_ SG_ 659 UI_aesEnable "Enable Automatic Emergency Steering (associated datavalue set to true and never changed by UI firmware); raw 3 = signal not available (SNA)";
CM_ SG_ 659 UI_ahlbEnable "Enable Automatic High/Low Beams; raw 3 = signal not available (SNA)";
CM_ SG_ 659 UI_autoLaneChangeEnable "Enable Automatic Lane Change; raw 3 = signal not available (SNA)";
CM_ SG_ 659 UI_winchProxUserOverride "User feedback from tow mode panel confirming that charge cable is disconnected when vehicle is unable to determine cable status";
CM_ SG_ 659 UI_rebootAutopilot "Touchscreen user interface computer: reboot autopilot";
CM_ SG_ 659 UI_autoParkRequest "Request Automatic Parking; raw 15 = signal not available (SNA)";
CM_ SG_ 659 UI_bsdEnable "Enable Blind Spot Detection (datavalue defaults to true and not changed by UI firmware); raw 3 = signal not available (SNA)";
CM_ SG_ 659 UI_fcwEnable "Enable Forward Collision Warning; raw 3 = signal not available (SNA)";
CM_ SG_ 659 UI_fcwSensitivity "Forward Collision Warning Level; raw 3 = signal not available (SNA)";
CM_ SG_ 659 UI_latControlEnable "Enable Lateral Control (lane centering, lane keeping, lane changing); raw 3 = signal not available (SNA)";
CM_ SG_ 659 UI_ldwEnable "Enable Lane Departure Warning; raw 3 = signal not available (SNA)";
CM_ SG_ 659 UI_pedalSafetyEnable "Touchscreen user interface computer: pedal safety enable; raw 3 = signal not available (SNA)";
CM_ SG_ 659 UI_pedalMap_epas "Touchscreen user interface computer: pedal map epas";
CM_ SG_ 659 UI_redLightStopSignEnable "Touchscreen user interface computer: red light stop sign enable; raw 3 = signal not available (SNA)";
CM_ SG_ 659 UI_selfParkTune "Touchscreen user interface computer: self park tune; raw 15 = signal not available (SNA)";
CM_ SG_ 659 UI_chassisControlCounter "Touchscreen user interface computer: chassis control counter";
CM_ SG_ 659 UI_chassisControlChecksum "Touchscreen user interface computer: chassis control checksum";
CM_ BO_ 1280 "Touchscreen user interface computer message: debug ECU; forwarded onto this bus by the gateway; frame length from the layout, not yet observed on a vehicle bus";
CM_ SG_ 1280 UI_debugEcuTarget "Touchscreen user interface computer: debug ecu target";
CM_ SG_ 1280 UI_DI_debugEnable "Touchscreen user interface computer: DI debug enable";
CM_ SG_ 1280 UI_DIS_debugEnable "Touchscreen user interface computer: DIS debug enable";
CM_ SG_ 1280 UI_PM_debugEnable "Touchscreen user interface computer: PM debug enable";
CM_ SG_ 1280 UI_PM_debugAt100Hz "Touchscreen user interface computer: PM debug at100 hz";
CM_ SG_ 1280 UI_PMS_debugEnable "Touchscreen user interface computer: PMS debug enable";
CM_ SG_ 1280 UI_PMS_debugAt100Hz "Touchscreen user interface computer: PMS debug at100 hz";
CM_ SG_ 1280 UI_BMS_debugAllEnable "Touchscreen user interface computer: BMS debug all enable";
CM_ SG_ 1280 UI_BMS_debugDisable "Touchscreen user interface computer: BMS debug disable";
CM_ SG_ 1280 UI_VCRIGHT_debugEnable "Touchscreen user interface computer: VCRIGHT debug enable";
CM_ SG_ 1280 UI_VCFRONT_debugEnable "Touchscreen user interface computer: VCFRONT debug enable";
CM_ SG_ 1280 UI_DIF_debugEnable "Touchscreen user interface computer: DIF debug enable";
CM_ SG_ 1280 UI_DIR_debugEnable "Touchscreen user interface computer: DIR debug enable";
CM_ SG_ 1280 UI_PMF_debugEnable "Touchscreen user interface computer: PMF debug enable";
CM_ SG_ 1280 UI_PMR_debugEnable "Touchscreen user interface computer: PMR debug enable";
CM_ BO_ 2043 "Touchscreen user interface computer message: debug tas; forwarded onto this bus by the gateway; frame length from the layout, not yet observed on a vehicle bus";
CM_ SG_ 2043 UI_debugDampingRequestFLC "Touchscreen user interface computer: debug damping request FLC; raw 255 = signal not available (SNA)";
CM_ SG_ 2043 UI_debugDampingRequestFLR "Touchscreen user interface computer: debug damping request FLR; raw 255 = signal not available (SNA)";
CM_ SG_ 2043 UI_debugDampingRequestFRC "Touchscreen user interface computer: debug damping request FRC; raw 255 = signal not available (SNA)";
CM_ SG_ 2043 UI_debugDampingRequestFRR "Touchscreen user interface computer: debug damping request FRR; raw 255 = signal not available (SNA)";
CM_ SG_ 2043 UI_debugDampingRequestRLC "Touchscreen user interface computer: debug damping request RLC; raw 255 = signal not available (SNA)";
CM_ SG_ 2043 UI_debugDampingRequestRLR "Touchscreen user interface computer: debug damping request RLR; raw 255 = signal not available (SNA)";
CM_ SG_ 2043 UI_debugDampingRequestRRC "Touchscreen user interface computer: debug damping request RRC; raw 255 = signal not available (SNA)";
CM_ SG_ 2043 UI_debugDampingRequestRRR "Touchscreen user interface computer: debug damping request RRR; raw 255 = signal not available (SNA)";
CM_ BO_ 568 "Touchscreen user interface computer message: driver assist map data; forwarded onto this bus by the gateway; frame length observed on a vehicle bus";
CM_ SG_ 568 UI_mapSpeedLimitDependency "Touchscreen user interface computer: map speed limit dependency; raw 7 = signal not available (SNA)";
CM_ SG_ 568 UI_roadClass "Autopilot map road class; raw 0 = signal not available (SNA)";
CM_ SG_ 568 UI_inSuperchargerGeofence "Touchscreen user interface computer: in supercharger geofence";
CM_ SG_ 568 UI_mapSpeedUnits "Touchscreen user interface computer: map speed units";
CM_ SG_ 568 UI_mapSpeedLimit "Touchscreen user interface computer: map speed limit; raw 31 = signal not available (SNA)";
CM_ SG_ 568 UI_mapSpeedLimitType "Touchscreen user interface computer: map speed limit type; raw 7 = signal not available (SNA)";
CM_ SG_ 568 UI_countryCode "Touchscreen user interface computer: country code; raw 1023 = signal not available (SNA)";
CM_ SG_ 568 UI_streetCount "Touchscreen user interface computer: street count";
CM_ SG_ 568 UI_gpsRoadMatch "Touchscreen user interface computer: gps road match";
CM_ SG_ 568 UI_navRouteActive "Navigation route is active";
CM_ SG_ 568 UI_parallelAutoparkEnabled "Autopilot map parallel park enabled.";
CM_ SG_ 568 UI_perpendicularAutoparkEnabled "Autopilot map perpendicular park enabled.";
CM_ SG_ 568 UI_nextBranchDist "Touchscreen user interface computer: next branch dist; raw 31 = signal not available (SNA)";
CM_ SG_ 568 UI_controlledAccess "DAS map controlled access segment.";
CM_ SG_ 568 UI_nextBranchLeftOffRamp "Touchscreen user interface computer: next branch left off ramp";
CM_ SG_ 568 UI_nextBranchRightOffRamp "Touchscreen user interface computer: next branch right off ramp";
CM_ SG_ 568 UI_rejectLeftLane "Touchscreen user interface computer: reject left lane";
CM_ SG_ 568 UI_rejectRightLane "Touchscreen user interface computer: reject right lane";
CM_ SG_ 568 UI_rejectHPP "Touchscreen user interface computer: reject HPP";
CM_ SG_ 568 UI_rejectNav "Touchscreen user interface computer: reject nav";
CM_ SG_ 568 UI_rejectLeftFreeSpace "Touchscreen user interface computer: reject left free space";
CM_ SG_ 568 UI_rejectRightFreeSpace "Touchscreen user interface computer: reject right free space";
CM_ SG_ 568 UI_rejectAutosteer "Touchscreen user interface computer: reject autosteer";
CM_ SG_ 568 UI_rejectHandsOn "Touchscreen user interface computer: reject hands on";
CM_ SG_ 568 UI_acceptBottsDots "Touchscreen user interface computer: accept botts dots";
CM_ SG_ 568 UI_autosteerRestricted "Autopilot map is autostreer restricted.";
CM_ SG_ 568 UI_pmmEnabled "Touchscreen user interface computer: pmm enabled";
CM_ SG_ 568 UI_scaEnabled "Touchscreen user interface computer: sca enabled";
CM_ SG_ 568 UI_mapDataCounter "Touchscreen user interface computer: map data counter";
CM_ SG_ 568 UI_mapDataChecksum "Touchscreen user interface computer: map data checksum";
CM_ BO_ 645 "Touchscreen user interface computer message: driver profile recall; forwarded onto this bus by the gateway; frame length observed on a vehicle bus";
CM_ SG_ 645 UI_driverProfileRecallIndex "Touchscreen user interface computer: driver profile recall index; raw 0 = signal not available (SNA)";
CM_ SG_ 645 UI_driverProfileRecallStop "notifies controller to stop profile recall action";
CM_ SG_ 645 UI_frontSeatRecallActive "signals when driver seat presets are being recalled";
CM_ SG_ 645 UI_frontSeatTrackPos "Touchscreen user interface computer: front seat track pos";
CM_ SG_ 645 UI_frontSeatBackPos "Touchscreen user interface computer: front seat back pos";
CM_ SG_ 645 UI_frontSeatLiftPos "Touchscreen user interface computer: front seat lift pos";
CM_ SG_ 645 UI_frontSeatTiltPos "Touchscreen user interface computer: front seat tilt pos";
CM_ SG_ 645 UI_columnAndLumbarRecallActive "Touchscreen user interface computer: column and lumbar recall active";
CM_ SG_ 645 UI_steeringColumnUpDownPos "Touchscreen user interface computer: steering column up down pos";
CM_ SG_ 645 UI_lumbarAPressurePercentage "Touchscreen user interface computer: lumbar a pressure percentage; raw 127 = signal not available (SNA)";
CM_ SG_ 645 UI_lumbarBPressurePercentage "Touchscreen user interface computer: lumbar b pressure percentage; raw 127 = signal not available (SNA)";
CM_ SG_ 645 UI_steeringColumnInOutPos "Touchscreen user interface computer: steering column in out pos";
CM_ SG_ 645 UI_leftMirrorTiltXPosition "signal from ui to command mirror X tilt position";
CM_ SG_ 645 UI_leftMirrorTiltYPosition "signal from ui to command mirror Y tilt position";
CM_ SG_ 645 UI_rightMirrorTiltXPosition "Touchscreen user interface computer: right mirror tilt x position";
CM_ SG_ 645 UI_rightMirrorTiltYPosition "Touchscreen user interface computer: right mirror tilt y position";
CM_ SG_ 645 UI_frontSeatThighSupportPos "Touchscreen user interface computer: front seat thigh support pos";
CM_ SG_ 645 UI_mirrorRecallActive "Touchscreen user interface computer: mirror recall active";
CM_ SG_ 645 UI_customMirrorDipPositionsSet "Reports whether custom mirror dip positions are set.";
CM_ SG_ 645 UI_leftMirrorDipXPosition "signal from ui to command left mirror X dip position";
CM_ SG_ 645 UI_leftMirrorDipYPosition "signal from ui to command mirror Y dip position";
CM_ SG_ 645 UI_rightMirrorDipXPosition "Touchscreen user interface computer: right mirror dip x position";
CM_ SG_ 645 UI_rightMirrorDipYPosition "Touchscreen user interface computer: right mirror dip y position";
CM_ SG_ 645 UI_modifyMirrorDipRequest "Reports that a user is trying to modify the mirrors in the dipped position.";
CM_ BO_ 651 "Touchscreen user interface computer message: driver profile recall2; forwarded onto this bus by the gateway; frame length from the layout, not yet observed on a vehicle bus";
CM_ SG_ 651 UI_driverProfileLinkedKeySHA1 "Touchscreen user interface computer: driver profile linked key SHA1; raw 4294967295 = signal not available (SNA)";
CM_ SG_ 651 UI_driverProfileIndex "Tracks manual driver profile selection. Shows the linked phonekey / key card / key fob or profile index if not linked";
CM_ SG_ 651 UI_driverProfileSelectionType "Tracks manual driver profile selection. Shows the linked phonekey / key card / key fob or profile index if not linked";
CM_ SG_ 651 UI_driverProfilePositionAdjusted "Tracks adjustments to driver profile. Sets when a profile position has been adjusted from what was saved";
CM_ SG_ 651 UI_activeKeyRequested "Tracks manual driver profile selection. Shows the linked phonekey / key card / key fob or profile index if not linked";
CM_ BO_ 984 "Touchscreen user interface computer message: elevation status; forwarded onto this bus by the gateway; frame length observed on a vehicle bus";
CM_ SG_ 984 UI_elevation "Touchscreen user interface computer: elevation; raw 8191 = signal not available (SNA)";
CM_ SG_ 984 UI_navElevation "Touchscreen user interface computer: nav elevation; raw 8191 = signal not available (SNA)";
CM_ BO_ 1139 "Touchscreen user interface computer message: eth nm; forwarded onto this bus by the gateway; frame length observed on a vehicle bus";
CM_ SG_ 1139 UI_nmGoingToSleep "Touchscreen user interface computer: nm going to sleep";
CM_ SG_ 1139 UI_nmKeepAwakeReason "reason UI is being kept awake; raw 0 = signal not available (SNA)";
CM_ SG_ 1139 UI_wakeupTime "Unix epoch time at which vehicle should wake for scheduled charge or update.";
CM_ BO_ 1267 "Touchscreen user interface computer message: front seat requests; forwarded onto this bus by the gateway; frame length observed on a vehicle bus";
CM_ SG_ 1267 UI_frontRightSeatTrackForward "Touchscreen user interface computer: front right seat track forward";
CM_ SG_ 1267 UI_frontRightSeatTrackBack "Touchscreen user interface computer: front right seat track back";
CM_ SG_ 1267 UI_frontLeftSeatTrackForward "Touchscreen user interface computer: front left seat track forward";
CM_ SG_ 1267 UI_frontLeftSeatTrackBack "Touchscreen user interface computer: front left seat track back";
CM_ SG_ 1267 UI_frontRightSeatBackrestBack "Touchscreen user interface computer: front right seat backrest back";
CM_ SG_ 1267 UI_frontRightSeatBackrestForward "Touchscreen user interface computer: front right seat backrest forward";
CM_ SG_ 1267 UI_frontLeftSeatBackrestBack "Touchscreen user interface computer: front left seat backrest back";
CM_ SG_ 1267 UI_frontLeftSeatBackrestForward "Touchscreen user interface computer: front left seat backrest forward";
CM_ SG_ 1267 UI_frontRightSeatTiltUp "Touchscreen user interface computer: front right seat tilt up";
CM_ SG_ 1267 UI_frontRightSeatTiltDown "Touchscreen user interface computer: front right seat tilt down";
CM_ SG_ 1267 UI_frontLeftSeatTiltUp "Touchscreen user interface computer: front left seat tilt up";
CM_ SG_ 1267 UI_frontLeftSeatTiltDown "Touchscreen user interface computer: front left seat tilt down";
CM_ SG_ 1267 UI_frontRightSeatLiftUp "Touchscreen user interface computer: front right seat lift up";
CM_ SG_ 1267 UI_frontRightSeatLiftDown "Touchscreen user interface computer: front right seat lift down";
CM_ SG_ 1267 UI_frontLeftSeatLiftUp "Touchscreen user interface computer: front left seat lift up";
CM_ SG_ 1267 UI_frontLeftSeatLiftDown "Touchscreen user interface computer: front left seat lift down";
CM_ SG_ 1267 UI_frontLeftSeatLumbarUp "Touchscreen user interface computer: front left seat lumbar up";
CM_ SG_ 1267 UI_frontLeftSeatLumbarDown "Touchscreen user interface computer: front left seat lumbar down";
CM_ SG_ 1267 UI_frontRightSeatLumbarUp "Touchscreen user interface computer: front right seat lumbar up";
CM_ SG_ 1267 UI_frontRightSeatLumbarDown "Touchscreen user interface computer: front right seat lumbar down";
CM_ SG_ 1267 UI_frontLeftSeatLumbarIn "Touchscreen user interface computer: front left seat lumbar in";
CM_ SG_ 1267 UI_frontLeftSeatLumbarOut "Touchscreen user interface computer: front left seat lumbar out";
CM_ SG_ 1267 UI_frontRightSeatLumbarIn "Touchscreen user interface computer: front right seat lumbar in";
CM_ SG_ 1267 UI_frontRightSeatLumbarOut "Touchscreen user interface computer: front right seat lumbar out";
CM_ SG_ 1267 UI_seatAdjustmentSource "Touchscreen user interface computer: seat adjustment source";
CM_ BO_ 804 "Touchscreen user interface computer message: gps time; forwarded onto this bus by the gateway; frame length observed on a vehicle bus";
CM_ SG_ 804 UI_gpsTime "Touchscreen user interface computer: gps time";
CM_ BO_ 883 "Touchscreen user interface computer message: gps vehicle speed; forwarded onto this bus by the gateway; frame length observed on a vehicle bus";
CM_ SG_ 883 UI_gpsHDOP "Touchscreen user interface computer: gps HDOP";
CM_ SG_ 883 UI_gpsVehicleHeading "Touchscreen user interface computer: gps vehicle heading";
CM_ SG_ 883 UI_gpsVehicleSpeed "Touchscreen user interface computer: gps vehicle speed";
CM_ SG_ 883 UI_userSpeedOffset "Touchscreen user interface computer: user speed offset";
CM_ SG_ 883 UI_mapSpeedLimitUnits "Autopilot map speed limit units.";
CM_ SG_ 883 UI_userSpeedOffsetUnits "Touchscreen user interface computer: user speed offset units";
CM_ SG_ 883 UI_mppSpeedLimit "Autopilot map speed limit";
CM_ SG_ 883 UI_gpsNmeaMIA "GPS NMEA data MIA";
CM_ SG_ 883 UI_gpsAntennaDisconnected "GPS antenna state";
CM_ SG_ 883 UI_conditionalLimitActive "Conditional speed limit condition is currently active";
CM_ SG_ 883 UI_conditionalSpeedLimit "Conditional speed limit value; raw 31 = signal not available (SNA)";
CM_ BO_ 912 "Touchscreen user interface computer message: grid form control; forwarded onto this bus by the gateway; frame length observed on a vehicle bus";
CM_ SG_ 912 UI_dischargeTerminationPct "Reports the minimum State of Energy (SOE) to which the vehicle will discharge for powering outlets, Vehicle to Load (V2L), or Vehicle to Home (V2H).";
CM_ SG_ 912 UI_v2lFeatureRequest "Touchscreen user interface computer: v2l feature request";
CM_ SG_ 912 UI_powershareRequest "Controls the start and stop of powersharing.";
CM_ BO_ 755 "Touchscreen user interface computer message: hvac request; forwarded onto this bus by the gateway; frame length observed on a vehicle bus";
CM_ SG_ 755 UI_hvacReqTempSetpointLeft "HVAC left set temperature.";
CM_ SG_ 755 UI_hvacReqAutoBlowerLevel "Reports the auto Heating, Ventilation, and Air Conditioning (HVAC) speed aggressiveness setting.";
CM_ SG_ 755 UI_hvacReqTempSetpointRight "HVAC right set temperature.";
CM_ SG_ 755 UI_hvacReqAirDistributionMode "Request for air distribution mode.";
CM_ SG_ 755 UI_hvacReqBlowerSegment "HVAC manual blower request (GUI_hvacManualBlowerRequest)";
CM_ SG_ 755 UI_hvacReqRecirc "HVAC recirculation mode";
CM_ SG_ 755 UI_hvacReqACDisable "Request to disable AC.";
CM_ SG_ 755 UI_hvacDefogState "HVAC defog state.";
CM_ SG_ 755 UI_hvacReqUserPowerState "Reports HVAC power state.";
CM_ SG_ 755 UI_hvacReqSecondRowState "HVAC rear fan request speed.";
CM_ SG_ 755 UI_hvacUseModeledDuctTemp "Touchscreen user interface computer: hvac use modeled duct temp";
CM_ SG_ 755 UI_hvacReqKeepClimateOn "Request accessory power";
CM_ SG_ 755 UI_hvacReqBioWeaponDefMode "Request for BioWeapon Defense Mode";
CM_ SG_ 755 UI_hvacLatchPassengerPresent "Touchscreen user interface computer: hvac latch passenger present";
CM_ SG_ 755 UI_enableHvacControlsFeatures1 "Touchscreen user interface computer: enable hvac controls features1";
CM_ SG_ 755 UI_enableHvacNotifications "Touchscreen user interface computer: enable hvac notifications";
CM_ SG_ 755 UI_hvacPhoneCallAirFlowAdjustEna "Touchscreen user interface computer: hvac phone call air flow adjust enabled";
CM_ SG_ 755 UI_enableHvacVOCPurgeRoutine "Touchscreen user interface computer: enable hvac VOC purge routine";
CM_ SG_ 755 UI_enableCustomerTHSAlerts "Touchscreen user interface computer: enable customer THS alerts";
CM_ SG_ 755 UI_evapDryingSelectiveEnable "Touchscreen user interface computer: evap drying selective enable";
CM_ SG_ 755 UI_enableHvacWeatherDataBasedHum "Touchscreen user interface computer: enable hvac weather data based humidity controls";
CM_ SG_ 755 UI_hvacReqTempSetpointCOP "HVAC cabin overheat protection set temperature.";
CM_ SG_ 755 UI_hvacClimateNudgeStatus "Touchscreen user interface computer: hvac climate nudge status";
CM_ SG_ 755 UI_enableHvacControlsFeatures2 "Touchscreen user interface computer: enable hvac controls features2";
CM_ SG_ 755 UI_enableHvacAPFoggingMonitor "Touchscreen user interface computer: enable hvac AP fogging monitor";
CM_ SG_ 755 UI_enableHvacLimpMode "Touchscreen user interface computer: enable hvac limp mode";
CM_ BO_ 777 "Touchscreen user interface computer message: location status; forwarded onto this bus by the gateway; frame length observed on a vehicle bus";
CM_ SG_ 777 UI_latitude "Touchscreen user interface computer: latitude";
CM_ SG_ 777 UI_longitude "Touchscreen user interface computer: longitude";
CM_ SG_ 777 UI_gpsAccuracy "Touchscreen user interface computer: gps accuracy; raw 127 = signal not available (SNA)";
CM_ BO_ 1523 "Touchscreen user interface computer message: odo; forwarded onto this bus by the gateway; frame length observed on a vehicle bus";
CM_ SG_ 1523 UI_odometer "Odometer; raw 16777215 = signal not available (SNA)";
CM_ BO_ 948 "Touchscreen user interface computer message: peripheral power requests; forwarded onto this bus by the gateway; frame length observed on a vehicle bus";
CM_ SG_ 948 UI_usbFrontHubPowerStateRequest "Reports the Universal Serial Bus (USB) Hub power request; raw 0 = signal not available (SNA)";
CM_ BO_ 955 "Touchscreen user interface computer message: power; forwarded onto this bus by the gateway; frame length observed on a vehicle bus";
CM_ SG_ 955 UI_powerExpected "Touchscreen user interface computer: power expected";
CM_ SG_ 955 UI_powerIdeal "Touchscreen user interface computer: power ideal";
CM_ SG_ 955 UI_dSocAlertEnable "Set when the BMS_a117_SW_Delta_SOC_Weak_Short alert for the BMS should have a functional response";
CM_ SG_ 955 UI_dSocAlertThreshold "Touchscreen user interface computer: d soc alert threshold";
CM_ BO_ 827 "Touchscreen user interface computer message: power estimates; forwarded onto this bus by the gateway; frame length observed on a vehicle bus";
CM_ SG_ 827 UI_idlePowerConsumption "Power consumption when idle";
CM_ SG_ 827 UI_chargeTimeUntilTerminationPct "Charge time minutes until reached uSoe target; raw 2047 = signal not available (SNA)";
CM_ SG_ 827 UI_isTripChargingActive "Touchscreen user interface computer: is trip charging active";
CM_ SG_ 827 UI_chargeTimeUntilReadyToDepart "Charge time minutes until enough energy to depart for rest of trip; raw 2047 = signal not available (SNA)";
CM_ BO_ 661 "Touchscreen user interface computer message: power rationality config; forwarded onto this bus by the gateway; frame length observed on a vehicle bus";
CM_ SG_ 661 UI_powerRationalityConfigIndex "Touchscreen user interface computer: power rationality config index";
CM_ SG_ 661 UI_vcleftCfgRationalityThreshold "Touchscreen user interface computer: vcleft cfg rationality threshold0; raw 0 = signal not available (SNA)";
CM_ SG_ 661 UI_vcleftCfgRationalityTime0 "Touchscreen user interface computer: vcleft cfg rationality time0; raw 0 = signal not available (SNA)";
CM_ SG_ 661 UI_vcleftCfgRationalityThre_0001 "Touchscreen user interface computer: vcleft cfg rationality threshold1; raw 0 = signal not available (SNA)";
CM_ SG_ 661 UI_vcleftCfgRationalityTime1 "Touchscreen user interface computer: vcleft cfg rationality time1; raw 0 = signal not available (SNA)";
CM_ SG_ 661 UI_vcleftCfgRationalityStaticA "Touchscreen user interface computer: vcleft cfg rationality static a; raw 65535 = signal not available (SNA)";
CM_ SG_ 661 UI_vcleftCfgRationalityStaticB "Touchscreen user interface computer: vcleft cfg rationality static b; raw 32768 = signal not available (SNA)";
CM_ SG_ 661 UI_vcleftCfgRationalityStaticC "Touchscreen user interface computer: vcleft cfg rationality static c; raw 32768 = signal not available (SNA)";
CM_ SG_ 661 UI_vcleftCfgRationalityDynamicA "Touchscreen user interface computer: vcleft cfg rationality dynamic a; raw 65535 = signal not available (SNA)";
CM_ SG_ 661 UI_vcleftCfgRationalityDynamicB "Touchscreen user interface computer: vcleft cfg rationality dynamic b; raw 32768 = signal not available (SNA)";
CM_ SG_ 661 UI_vcleftCfgRationalityDynamicC "Touchscreen user interface computer: vcleft cfg rationality dynamic c; raw 32768 = signal not available (SNA)";
CM_ SG_ 661 UI_vcrightCfgRationalityThreshol "Touchscreen user interface computer: vcright cfg rationality threshold0; raw 0 = signal not available (SNA)";
CM_ SG_ 661 UI_vcrightCfgRationalityTime0 "Touchscreen user interface computer: vcright cfg rationality time0; raw 0 = signal not available (SNA)";
CM_ SG_ 661 UI_vcrightCfgRationalityThr_0001 "Touchscreen user interface computer: vcright cfg rationality threshold1; raw 0 = signal not available (SNA)";
CM_ SG_ 661 UI_vcrightCfgRationalityTime1 "Touchscreen user interface computer: vcright cfg rationality time1; raw 0 = signal not available (SNA)";
CM_ SG_ 661 UI_vcrightCfgRationalityStaticA "Touchscreen user interface computer: vcright cfg rationality static a; raw 65535 = signal not available (SNA)";
CM_ SG_ 661 UI_vcrightCfgRationalityStaticB "Touchscreen user interface computer: vcright cfg rationality static b; raw 32768 = signal not available (SNA)";
CM_ SG_ 661 UI_vcrightCfgRationalityStaticC "Touchscreen user interface computer: vcright cfg rationality static c; raw 32768 = signal not available (SNA)";
CM_ SG_ 661 UI_vcrightCfgRationalityDynamicA "Touchscreen user interface computer: vcright cfg rationality dynamic a; raw 65535 = signal not available (SNA)";
CM_ SG_ 661 UI_vcrightCfgRationalityDynamicB "Touchscreen user interface computer: vcright cfg rationality dynamic b; raw 32768 = signal not available (SNA)";
CM_ SG_ 661 UI_vcrightCfgRationalityDynamicC "Touchscreen user interface computer: vcright cfg rationality dynamic c; raw 32768 = signal not available (SNA)";
CM_ SG_ 661 UI_vcleftCfgCutoffThreshold0 "Touchscreen user interface computer: vcleft cfg cutoff threshold0; raw 0 = signal not available (SNA)";
CM_ SG_ 661 UI_vcleftCfgCutoffTime0 "Touchscreen user interface computer: vcleft cfg cutoff time0; raw 0 = signal not available (SNA)";
CM_ SG_ 661 UI_vcleftCfgCutoffThreshold1 "Touchscreen user interface computer: vcleft cfg cutoff threshold1; raw 0 = signal not available (SNA)";
CM_ SG_ 661 UI_vcleftCfgCutoffTime1 "Touchscreen user interface computer: vcleft cfg cutoff time1; raw 0 = signal not available (SNA)";
CM_ SG_ 661 UI_vcleftCfgCutoffStaticA "Touchscreen user interface computer: vcleft cfg cutoff static a; raw 65535 = signal not available (SNA)";
CM_ SG_ 661 UI_vcleftCfgCutoffStaticB "Touchscreen user interface computer: vcleft cfg cutoff static b; raw 32768 = signal not available (SNA)";
CM_ SG_ 661 UI_vcleftCfgCutoffStaticC "Touchscreen user interface computer: vcleft cfg cutoff static c; raw 32768 = signal not available (SNA)";
CM_ SG_ 661 UI_vcleftCfgCutoffDynamicA "Touchscreen user interface computer: vcleft cfg cutoff dynamic a; raw 65535 = signal not available (SNA)";
CM_ SG_ 661 UI_vcleftCfgCutoffDynamicB "Touchscreen user interface computer: vcleft cfg cutoff dynamic b; raw 32768 = signal not available (SNA)";
CM_ SG_ 661 UI_vcleftCfgCutoffDynamicC "Touchscreen user interface computer: vcleft cfg cutoff dynamic c; raw 32768 = signal not available (SNA)";
CM_ SG_ 661 UI_vcrightCfgCutoffThreshold0 "Touchscreen user interface computer: vcright cfg cutoff threshold0; raw 0 = signal not available (SNA)";
CM_ SG_ 661 UI_vcrightCfgCutoffTime0 "Touchscreen user interface computer: vcright cfg cutoff time0; raw 0 = signal not available (SNA)";
CM_ SG_ 661 UI_vcrightCfgCutoffThreshold1 "Touchscreen user interface computer: vcright cfg cutoff threshold1; raw 0 = signal not available (SNA)";
CM_ SG_ 661 UI_vcrightCfgCutoffTime1 "Touchscreen user interface computer: vcright cfg cutoff time1; raw 0 = signal not available (SNA)";
CM_ SG_ 661 UI_vcrightCfgCutoffStaticA "Touchscreen user interface computer: vcright cfg cutoff static a; raw 65535 = signal not available (SNA)";
CM_ SG_ 661 UI_vcrightCfgCutoffStaticB "Touchscreen user interface computer: vcright cfg cutoff static b; raw 32768 = signal not available (SNA)";
CM_ SG_ 661 UI_vcrightCfgCutoffStaticC "Touchscreen user interface computer: vcright cfg cutoff static c; raw 32768 = signal not available (SNA)";
CM_ SG_ 661 UI_vcrightCfgCutoffDynamicA "Touchscreen user interface computer: vcright cfg cutoff dynamic a; raw 65535 = signal not available (SNA)";
CM_ SG_ 661 UI_vcrightCfgCutoffDynamicB "Touchscreen user interface computer: vcright cfg cutoff dynamic b; raw 32768 = signal not available (SNA)";
CM_ SG_ 661 UI_vcrightCfgCutoffDynamicC "Touchscreen user interface computer: vcright cfg cutoff dynamic c; raw 32768 = signal not available (SNA)";
CM_ BO_ 820 "Touchscreen user interface computer message: powertrain control; forwarded onto this bus by the gateway; frame length observed on a vehicle bus";
CM_ SG_ 820 UI_systemPowerLimit "Touchscreen user interface computer: system power limit; raw 31 = signal not available (SNA)";
CM_ SG_ 820 UI_pedalMap "Switch between various platform specific pedal maps";
CM_ SG_ 820 UI_enableRegenBackfill "Indicates if regenerative braking backfill has been enabled by the driver";
CM_ SG_ 820 UI_systemTorqueLimit "Touchscreen user interface computer: system torque limit; raw 63 = signal not available (SNA)";
CM_ SG_ 820 UI_closureConfirmed "Touchscreen user interface computer: closure confirmed";
CM_ SG_ 820 UI_regenTorqueMax "Maximum regen torque from UI - reports different value when in track mode";
CM_ SG_ 820 UI_limitMode "Commands limited drive inverter capabilities based on special vehicle modes";
CM_ SG_ 820 UI_factoryCustomerDrivingModeReq "Touchscreen user interface computer: factory customer driving mode request";
CM_ SG_ 820 UI_motorOnMode "Request from the UI to selectively enable or disable a drive unit (dev-only)";
CM_ SG_ 820 UI_stoppingMode "Low-speed behavior when no pedal is pressed (stopping/rolling/creeping)";
CM_ SG_ 820 UI_DIAppSliderDebug "Touchscreen user interface computer: DI app slider debug";
CM_ SG_ 820 UI_speedLimit "Maximum allowed speed enforced at vehicle level; raw 511 = signal not available (SNA)";
CM_ SG_ 820 UI_enableSmartShift "Stalkless convenience feature that allows unparking with only a firm press of brake pedal";
CM_ SG_ 820 UI_navVehParallelToRdCanContinue "Whether the vehicle is parallel parked on a public road; raw 0 = signal not available (SNA)";
CM_ SG_ 820 UI_powertrainControlCounter "Touchscreen user interface computer: powertrain control counter";
CM_ SG_ 820 UI_powertrainControlChecksum "Touchscreen user interface computer: powertrain control checksum";
CM_ BO_ 826 "Touchscreen user interface computer message: range; forwarded onto this bus by the gateway; frame length observed on a vehicle bus";
CM_ SG_ 826 UI_ratedRange "Rated range in miles";
CM_ SG_ 826 UI_whpm "Touchscreen user interface computer: whpm";
CM_ SG_ 826 UI_soe "State of energy";
CM_ SG_ 826 UI_uSoe "Usable state of energy";
CM_ SG_ 826 UI_softPackLimitPct "Touchscreen user interface computer: soft pack limit pct";
CM_ SG_ 826 UI_targetFullPackEnergy "Touchscreen user interface computer: target full pack energy";
CM_ BO_ 723 "Touchscreen user interface computer message: solar data; forwarded onto this bus by the gateway; frame length observed on a vehicle bus";
CM_ SG_ 723 UI_solarAzimuthAngle "Touchscreen user interface computer: solar azimuth angle; raw 32768 = signal not available (SNA)";
CM_ SG_ 723 UI_solarAzimuthAngleCarRef "Touchscreen user interface computer: solar azimuth angle car ref; raw 255 = signal not available (SNA)";
CM_ SG_ 723 UI_isSunUp "is sun up; raw 3 = signal not available (SNA)";
CM_ SG_ 723 UI_solarElevationAngle "Solar Elevation Angle; raw 127 = signal not available (SNA)";
CM_ SG_ 723 UI_screenPCBTemperature "Temperature of display PCB";
CM_ SG_ 723 UI_minsToSunset "time until to sunset";
CM_ SG_ 723 UI_minsToSunrise "time until to sunrise";
BA_DEF_ BO_ "GenMsgCycleTime" INT 0 3600000;
BA_DEF_ BO_ "GenMsgSendType" ENUM "Cyclic","NotUsed","NotUsed","NotUsed","NotUsed","NotUsed","NotUsed","IfActive","NoMsgSendType","NotUsed";
BA_DEF_ BO_ "VFrameFormat" ENUM "StandardCAN","ExtendedCAN","reserved","J1939PG","reserved","reserved","reserved","reserved","reserved","reserved","reserved","reserved","reserved","reserved","StandardCAN_FD","ExtendedCAN_FD";
BA_DEF_ BO_ "CANFD_BRS" ENUM "0","1";
BA_DEF_ SG_ "GenSigSNA" STRING;
BA_DEF_ SG_ "SystemSignalLongSymbol" STRING;
BA_DEF_ SG_ "Confidence" ENUM "validated","plausible","layout-only","contradicted";
BA_DEF_DEF_ "GenMsgCycleTime" 0;
BA_DEF_DEF_ "GenMsgSendType" "NoMsgSendType";
BA_DEF_DEF_ "VFrameFormat" "StandardCAN";
BA_DEF_DEF_ "CANFD_BRS" "1";
BA_DEF_DEF_ "GenSigSNA" "";
BA_DEF_DEF_ "SystemSignalLongSymbol" "";
BA_DEF_DEF_ "Confidence" "layout-only";
BA_ "GenMsgCycleTime" BO_ 852 100;
BA_ "GenMsgSendType" BO_ 852 0;
BA_ "GenMsgCycleTime" BO_ 523 20;
BA_ "GenMsgSendType" BO_ 523 0;
BA_ "GenMsgCycleTime" BO_ 1398 100;
BA_ "GenMsgSendType" BO_ 1398 0;
BA_ "GenMsgCycleTime" BO_ 1357 1000;
BA_ "GenMsgSendType" BO_ 1357 0;
BA_ "GenMsgCycleTime" BO_ 525 100;
BA_ "GenMsgSendType" BO_ 525 0;
BA_ "GenMsgCycleTime" BO_ 409 50;
BA_ "GenMsgSendType" BO_ 409 0;
BA_ "GenMsgCycleTime" BO_ 410 50;
BA_ "GenMsgSendType" BO_ 410 0;
BA_ "GenMsgCycleTime" BO_ 538 100;
BA_ "GenMsgSendType" BO_ 538 0;
BA_ "GenMsgCycleTime" BO_ 1657 500;
BA_ "GenMsgSendType" BO_ 1657 0;
BA_ "GenMsgCycleTime" BO_ 1021 500;
BA_ "GenMsgSendType" BO_ 1021 0;
BA_ "GenMsgCycleTime" BO_ 819 500;
BA_ "GenMsgSendType" BO_ 819 0;
BA_ "GenMsgCycleTime" BO_ 659 500;
BA_ "GenMsgSendType" BO_ 659 0;
BA_ "GenMsgCycleTime" BO_ 1280 5000;
BA_ "GenMsgSendType" BO_ 1280 0;
BA_ "GenMsgCycleTime" BO_ 2043 2000;
BA_ "GenMsgSendType" BO_ 2043 0;
BA_ "GenMsgCycleTime" BO_ 568 500;
BA_ "GenMsgSendType" BO_ 568 0;
BA_ "GenMsgCycleTime" BO_ 645 500;
BA_ "GenMsgSendType" BO_ 645 0;
BA_ "GenMsgCycleTime" BO_ 651 500;
BA_ "GenMsgSendType" BO_ 651 0;
BA_ "GenMsgCycleTime" BO_ 984 1000;
BA_ "GenMsgSendType" BO_ 984 0;
BA_ "GenMsgCycleTime" BO_ 1139 500;
BA_ "GenMsgSendType" BO_ 1139 0;
BA_ "GenMsgCycleTime" BO_ 1267 500;
BA_ "GenMsgSendType" BO_ 1267 0;
BA_ "GenMsgCycleTime" BO_ 804 1000;
BA_ "GenMsgSendType" BO_ 804 0;
BA_ "GenMsgCycleTime" BO_ 883 1000;
BA_ "GenMsgSendType" BO_ 883 0;
BA_ "GenMsgCycleTime" BO_ 912 1000;
BA_ "GenMsgSendType" BO_ 912 0;
BA_ "GenMsgCycleTime" BO_ 755 500;
BA_ "GenMsgSendType" BO_ 755 0;
BA_ "GenMsgCycleTime" BO_ 777 1000;
BA_ "GenMsgSendType" BO_ 777 0;
BA_ "GenMsgCycleTime" BO_ 1523 1000;
BA_ "GenMsgSendType" BO_ 1523 0;
BA_ "GenMsgCycleTime" BO_ 948 500;
BA_ "GenMsgSendType" BO_ 948 0;
BA_ "GenMsgCycleTime" BO_ 955 1000;
BA_ "GenMsgSendType" BO_ 955 0;
BA_ "GenMsgCycleTime" BO_ 827 1000;
BA_ "GenMsgSendType" BO_ 827 0;
BA_ "GenMsgCycleTime" BO_ 661 5000;
BA_ "GenMsgSendType" BO_ 661 0;
BA_ "GenMsgCycleTime" BO_ 820 500;
BA_ "GenMsgSendType" BO_ 820 0;
BA_ "GenMsgCycleTime" BO_ 826 1000;
BA_ "GenMsgSendType" BO_ 826 0;
BA_ "GenMsgCycleTime" BO_ 723 1000;
BA_ "GenMsgSendType" BO_ 723 0;
BA_ "Confidence" SG_ 852 TAS_matrixIndex 1;
BA_ "SystemSignalLongSymbol" SG_ 852 TAS_a066_undefinedInstructionAbo "TAS_a066_undefinedInstructionAbort";
BA_ "SystemSignalLongSymbol" SG_ 852 TAS_a150_accelAvgImplausible_FL_ "TAS_a150_accelAvgImplausible_FL_X";
BA_ "SystemSignalLongSymbol" SG_ 852 TAS_a151_accelAvgImplausible_FL_ "TAS_a151_accelAvgImplausible_FL_Y";
BA_ "SystemSignalLongSymbol" SG_ 852 TAS_a152_accelAvgImplausible_FL_ "TAS_a152_accelAvgImplausible_FL_Z";
BA_ "SystemSignalLongSymbol" SG_ 852 TAS_a153_accelAvgImplausible_FR_ "TAS_a153_accelAvgImplausible_FR_X";
BA_ "SystemSignalLongSymbol" SG_ 852 TAS_a154_accelAvgImplausible_FR_ "TAS_a154_accelAvgImplausible_FR_Y";
BA_ "SystemSignalLongSymbol" SG_ 852 TAS_a155_accelAvgImplausible_FR_ "TAS_a155_accelAvgImplausible_FR_Z";
BA_ "SystemSignalLongSymbol" SG_ 852 TAS_a156_accelAvgImplausible_RL_ "TAS_a156_accelAvgImplausible_RL_X";
BA_ "SystemSignalLongSymbol" SG_ 852 TAS_a157_accelAvgImplausible_RL_ "TAS_a157_accelAvgImplausible_RL_Y";
BA_ "SystemSignalLongSymbol" SG_ 852 TAS_a158_accelAvgImplausible_RL_ "TAS_a158_accelAvgImplausible_RL_Z";
BA_ "SystemSignalLongSymbol" SG_ 852 TAS_a159_accelAvgImplausible_RR_ "TAS_a159_accelAvgImplausible_RR_X";
BA_ "SystemSignalLongSymbol" SG_ 852 TAS_a160_accelAvgImplausible_RR_ "TAS_a160_accelAvgImplausible_RR_Y";
BA_ "SystemSignalLongSymbol" SG_ 852 TAS_a161_accelAvgImplausible_RR_ "TAS_a161_accelAvgImplausible_RR_Z";
BA_ "SystemSignalLongSymbol" SG_ 852 TAS_a192_rideHeightObserverDiver "TAS_a192_rideHeightObserverDivergence";
BA_ "SystemSignalLongSymbol" SG_ 852 TAS_a197_invalidAdaptiveModeRequ "TAS_a197_invalidAdaptiveModeRequested";
BA_ "SystemSignalLongSymbol" SG_ 852 TAS_a198_a2bFrontAxleExtendedDis "TAS_a198_a2bFrontAxleExtendedDiscoveryTime";
BA_ "SystemSignalLongSymbol" SG_ 852 TAS_a199_a2bRearAxleExtendedDisc "TAS_a199_a2bRearAxleExtendedDiscoveryTime";
BA_ "SystemSignalLongSymbol" SG_ 852 TAS_a343_damperValveControlCompF "TAS_a343_damperValveControlCompFL";
BA_ "SystemSignalLongSymbol" SG_ 852 TAS_a344_damperValveControlRbndF "TAS_a344_damperValveControlRbndFL";
BA_ "SystemSignalLongSymbol" SG_ 852 TAS_a345_damperValveControlCompF "TAS_a345_damperValveControlCompFR";
BA_ "SystemSignalLongSymbol" SG_ 852 TAS_a346_damperValveControlRbndF "TAS_a346_damperValveControlRbndFR";
BA_ "SystemSignalLongSymbol" SG_ 852 TAS_a347_damperValveControlCompR "TAS_a347_damperValveControlCompRL";
BA_ "SystemSignalLongSymbol" SG_ 852 TAS_a348_damperValveControlRbndR "TAS_a348_damperValveControlRbndRL";
BA_ "SystemSignalLongSymbol" SG_ 852 TAS_a349_damperValveControlCompR "TAS_a349_damperValveControlCompRR";
BA_ "SystemSignalLongSymbol" SG_ 852 TAS_a350_damperValveControlRbndR "TAS_a350_damperValveControlRbndRR";
BA_ "Confidence" SG_ 523 TAS_axleIndex 1;
BA_ "Confidence" SG_ 523 TAS_rawHeightFL 0;
BA_ "GenSigSNA" SG_ 523 TAS_rawHeightFL "1023";
BA_ "Confidence" SG_ 523 TAS_staticHeightEstimateFL 0;
BA_ "GenSigSNA" SG_ 523 TAS_staticHeightEstimateFL "1023";
BA_ "Confidence" SG_ 523 TAS_componentPressureFL 0;
BA_ "GenSigSNA" SG_ 523 TAS_componentPressureFL "255";
BA_ "Confidence" SG_ 523 TAS_rawHeightFR 0;
BA_ "GenSigSNA" SG_ 523 TAS_rawHeightFR "1023";
BA_ "Confidence" SG_ 523 TAS_staticHeightEstimateFR 0;
BA_ "GenSigSNA" SG_ 523 TAS_staticHeightEstimateFR "1023";
BA_ "Confidence" SG_ 523 TAS_componentPressureFR 0;
BA_ "GenSigSNA" SG_ 523 TAS_componentPressureFR "255";
BA_ "Confidence" SG_ 523 TAS_rawHeightRL 0;
BA_ "GenSigSNA" SG_ 523 TAS_rawHeightRL "1023";
BA_ "Confidence" SG_ 523 TAS_staticHeightEstimateRL 0;
BA_ "GenSigSNA" SG_ 523 TAS_staticHeightEstimateRL "1023";
BA_ "Confidence" SG_ 523 TAS_componentPressureRL 0;
BA_ "GenSigSNA" SG_ 523 TAS_componentPressureRL "255";
BA_ "Confidence" SG_ 523 TAS_rawHeightRR 0;
BA_ "GenSigSNA" SG_ 523 TAS_rawHeightRR "1023";
BA_ "Confidence" SG_ 523 TAS_staticHeightEstimateRR 0;
BA_ "GenSigSNA" SG_ 523 TAS_staticHeightEstimateRR "1023";
BA_ "Confidence" SG_ 523 TAS_componentPressureRR 0;
BA_ "GenSigSNA" SG_ 523 TAS_componentPressureRR "255";
BA_ "Confidence" SG_ 1398 TAS_endstopState 0;
BA_ "Confidence" SG_ 1398 TAS_continuousControlState 0;
BA_ "Confidence" SG_ 1398 TAS_activeTireTune 0;
BA_ "Confidence" SG_ 1398 TAS_roughnessRaiseReason 0;
BA_ "Confidence" SG_ 1398 TAS_frontMetricDrivesRear 0;
BA_ "Confidence" SG_ 1398 TAS_roadCondition 0;
BA_ "GenSigSNA" SG_ 1398 TAS_roadCondition "255";
BA_ "Confidence" SG_ 1398 TAS_bellyProtect 0;
BA_ "Confidence" SG_ 1398 TAS_frontMetricDrivesFront 0;
BA_ "Confidence" SG_ 1398 TAS_speedBumpAxleFront 0;
BA_ "Confidence" SG_ 1398 TAS_speedBumpAxleRear 0;
BA_ "Confidence" SG_ 1398 TAS_holeProtectFL 0;
BA_ "Confidence" SG_ 1398 TAS_holeProtectFR 0;
BA_ "Confidence" SG_ 1398 TAS_holeProtectRL 0;
BA_ "Confidence" SG_ 1398 TAS_holeProtectRR 0;
BA_ "Confidence" SG_ 1398 TAS_stepProtectFL 0;
BA_ "Confidence" SG_ 1398 TAS_stepProtectFR 0;
BA_ "Confidence" SG_ 1398 TAS_stepProtectRL 0;
BA_ "Confidence" SG_ 1398 TAS_stepProtectRR 0;
BA_ "Confidence" SG_ 1398 TAS_FDUTorqueCorruptionScale 0;
BA_ "GenSigSNA" SG_ 1398 TAS_FDUTorqueCorruptionScale "15";
BA_ "Confidence" SG_ 1398 TAS_sprungMassEstimate 0;
BA_ "GenSigSNA" SG_ 1398 TAS_sprungMassEstimate "31";
BA_ "Confidence" SG_ 1398 TAS_anyDamperActive 0;
BA_ "Confidence" SG_ 1398 TAS_dampingStatesCounter 0;
BA_ "Confidence" SG_ 1398 TAS_dampingStatesChecksum 0;
BA_ "Confidence" SG_ 1357 TAS_infoIndex 1;
BA_ "Confidence" SG_ 1357 TAS_infoBuildType 0;
BA_ "Confidence" SG_ 1357 TAS_infoBuildConfigId 0;
BA_ "Confidence" SG_ 1357 TAS_infoHardwareId 0;
BA_ "Confidence" SG_ 1357 TAS_infoComponentId 0;
BA_ "Confidence" SG_ 1357 TAS_infoPcbaId 0;
BA_ "Confidence" SG_ 1357 TAS_infoAssemblyId 0;
BA_ "GenSigSNA" SG_ 1357 TAS_infoAssemblyId "255";
BA_ "Confidence" SG_ 1357 TAS_infoUsageId 0;
BA_ "Confidence" SG_ 1357 TAS_infoSubUsageId 0;
BA_ "Confidence" SG_ 1357 TAS_infoAppCrc 0;
BA_ "Confidence" SG_ 1357 TAS_infoAppGitHash 0;
BA_ "Confidence" SG_ 1357 TAS_infoBootGitHash 0;
BA_ "Confidence" SG_ 1357 TAS_infoPlatformType 0;
BA_ "Confidence" SG_ 1357 TAS_infoMajorVersion 0;
BA_ "GenSigSNA" SG_ 1357 TAS_infoMajorVersion "255";
BA_ "Confidence" SG_ 1357 TAS_infoBranchOrigin 0;
BA_ "GenSigSNA" SG_ 1357 TAS_infoBranchOrigin "255";
BA_ "Confidence" SG_ 1357 TAS_infoMaturity 0;
BA_ "GenSigSNA" SG_ 1357 TAS_infoMaturity "255";
BA_ "Confidence" SG_ 1357 TAS_infoHardwareRevision 0;
BA_ "GenSigSNA" SG_ 1357 TAS_infoHardwareRevision "255";
BA_ "Confidence" SG_ 525 TAS_levelingState 0;
BA_ "Confidence" SG_ 525 TAS_levelingItem 0;
BA_ "Confidence" SG_ 525 TAS_pressureGallery 0;
BA_ "GenSigSNA" SG_ 525 TAS_pressureGallery "255";
BA_ "Confidence" SG_ 525 TAS_pressureReservoir 0;
BA_ "GenSigSNA" SG_ 525 TAS_pressureReservoir "255";
BA_ "Confidence" SG_ 525 TAS_runMode 0;
BA_ "Confidence" SG_ 525 TAS_filterMode 0;
BA_ "Confidence" SG_ 525 TAS_compressorRun 0;
BA_ "Confidence" SG_ 525 TAS_twistDetected 0;
BA_ "Confidence" SG_ 525 TAS_leanDetected 0;
BA_ "Confidence" SG_ 525 TAS_limpHomeMode 0;
BA_ "Confidence" SG_ 525 TAS_targetLevel 0;
BA_ "Confidence" SG_ 525 TAS_currentLevel 0;
BA_ "Confidence" SG_ 525 TAS_jackMode 0;
BA_ "Confidence" SG_ 525 TAS_reduceVehicleSpeedRequest 0;
BA_ "Confidence" SG_ 525 TAS_statesCounter 0;
BA_ "Confidence" SG_ 525 TAS_statesChecksum 0;
BA_ "Confidence" SG_ 1627 TAS_udsResponseData 1;
BA_ "Confidence" SG_ 409 TAS_adaptiveActivityFL_C 0;
BA_ "GenSigSNA" SG_ 409 TAS_adaptiveActivityFL_C "31";
BA_ "Confidence" SG_ 409 TAS_adaptiveActivityFL_R 0;
BA_ "GenSigSNA" SG_ 409 TAS_adaptiveActivityFL_R "31";
BA_ "Confidence" SG_ 409 TAS_adaptiveActivityFR_C 0;
BA_ "GenSigSNA" SG_ 409 TAS_adaptiveActivityFR_C "31";
BA_ "Confidence" SG_ 409 TAS_adaptiveActivityFR_R 0;
BA_ "GenSigSNA" SG_ 409 TAS_adaptiveActivityFR_R "31";
BA_ "Confidence" SG_ 409 TAS_adaptiveActivityRL_C 0;
BA_ "GenSigSNA" SG_ 409 TAS_adaptiveActivityRL_C "31";
BA_ "Confidence" SG_ 409 TAS_adaptiveActivityRL_R 0;
BA_ "GenSigSNA" SG_ 409 TAS_adaptiveActivityRL_R "31";
BA_ "Confidence" SG_ 409 TAS_adaptiveActivityRR_C 0;
BA_ "GenSigSNA" SG_ 409 TAS_adaptiveActivityRR_C "31";
BA_ "Confidence" SG_ 409 TAS_adaptiveActivityRR_R 0;
BA_ "GenSigSNA" SG_ 409 TAS_adaptiveActivityRR_R "31";
BA_ "Confidence" SG_ 409 TAS_uiHeightFL 0;
BA_ "GenSigSNA" SG_ 409 TAS_uiHeightFL "63";
BA_ "Confidence" SG_ 409 TAS_uiHeightFR 0;
BA_ "GenSigSNA" SG_ 409 TAS_uiHeightFR "63";
BA_ "Confidence" SG_ 409 TAS_uiHeightRL 0;
BA_ "GenSigSNA" SG_ 409 TAS_uiHeightRL "63";
BA_ "Confidence" SG_ 409 TAS_uiHeightRR 0;
BA_ "GenSigSNA" SG_ 409 TAS_uiHeightRR "63";
BA_ "Confidence" SG_ 410 TAS_bodyAccelFL 0;
BA_ "GenSigSNA" SG_ 410 TAS_bodyAccelFL "255";
BA_ "Confidence" SG_ 410 TAS_bodyAccelFR 0;
BA_ "GenSigSNA" SG_ 410 TAS_bodyAccelFR "255";
BA_ "Confidence" SG_ 410 TAS_bodyAccelRL 0;
BA_ "GenSigSNA" SG_ 410 TAS_bodyAccelRL "255";
BA_ "Confidence" SG_ 410 TAS_bodyAccelRR 0;
BA_ "GenSigSNA" SG_ 410 TAS_bodyAccelRR "255";
BA_ "Confidence" SG_ 538 TAS_yellowWarningLamp 0;
BA_ "Confidence" SG_ 538 TAS_redWarningLamp 0;
BA_ "Confidence" SG_ 538 TAS_veryLowAllowed 0;
BA_ "Confidence" SG_ 538 TAS_lowAllowed 0;
BA_ "Confidence" SG_ 538 TAS_standardAllowed 0;
BA_ "Confidence" SG_ 538 TAS_highAllowed 0;
BA_ "Confidence" SG_ 538 TAS_veryHighAllowed 0;
BA_ "Confidence" SG_ 538 TAS_extractAllowed 0;
BA_ "Confidence" SG_ 538 TAS_showSpinner 0;
BA_ "Confidence" SG_ 538 TAS_adaptiveRideModeOverride 0;
BA_ "GenSigSNA" SG_ 538 TAS_adaptiveRideModeOverride "3";
BA_ "Confidence" SG_ 538 TAS_levelSelectEnabled 0;
BA_ "Confidence" SG_ 538 TAS_jackModeToggleEnabled 0;
BA_ "Confidence" SG_ 538 TAS_adaptiveRideSelectEnabled 0;
BA_ "Confidence" SG_ 538 TAS_launchModeState 0;
BA_ "Confidence" SG_ 538 TAS_restrictUpLevelingFalcons 0;
BA_ "Confidence" SG_ 538 TAS_restrictUpLevelingTrunk 0;
BA_ "Confidence" SG_ 538 TAS_restrictDownLevelingDoors 0;
BA_ "Confidence" SG_ 538 TAS_restrictLevelingChargeCable 0;
BA_ "Confidence" SG_ 538 TAS_restrictLevelingSystemCheck 0;
BA_ "Confidence" SG_ 538 TAS_restrictLevelingTransport 0;
BA_ "Confidence" SG_ 538 TAS_restrictLevelingShowroom 0;
BA_ "Confidence" SG_ 538 TAS_uiControlCounter 0;
BA_ "Confidence" SG_ 538 TAS_uiControlChecksum 0;
BA_ "Confidence" SG_ 1641 UDS_KOSTIAsccmRequestData 1;
BA_ "Confidence" SG_ 1538 UDS_bmsRequestData 1;
BA_ "Confidence" SG_ 1579 UDS_ccRequestData 1;
BA_ "Confidence" SG_ 1539 UDS_cmpRequestData 1;
BA_ "Confidence" SG_ 1543 UDS_cmpdRequestData 1;
BA_ "Confidence" SG_ 1550 UDS_cpRequestData 1;
BA_ "Confidence" SG_ 1589 UDS_diRequestData 1;
BA_ "Confidence" SG_ 1541 UDS_difRequestData 1;
BA_ "Confidence" SG_ 1542 UDS_dirRequestData 1;
BA_ "Confidence" SG_ 1572 UDS_epblRequestData_H 1;
BA_ "Confidence" SG_ 1572 UDS_epblRequestData_L 1;
BA_ "Confidence" SG_ 1574 UDS_epbrRequestData_H 1;
BA_ "Confidence" SG_ 1574 UDS_epbrRequestData_L 1;
BA_ "Confidence" SG_ 2015 UDS_functionalRequestData_0 1;
BA_ "Confidence" SG_ 2015 UDS_functionalRequestData_1 1;
BA_ "Confidence" SG_ 2015 UDS_functionalRequestData_2 1;
BA_ "Confidence" SG_ 2015 UDS_functionalRequestData_3 1;
BA_ "Confidence" SG_ 2015 UDS_functionalRequestData_4 1;
BA_ "Confidence" SG_ 2015 UDS_functionalRequestData_5 1;
BA_ "Confidence" SG_ 2015 UDS_functionalRequestData_6 1;
BA_ "Confidence" SG_ 2015 UDS_functionalRequestData_7 1;
BA_ "Confidence" SG_ 1552 UDS_hvpRequestData 1;
BA_ "Confidence" SG_ 1560 UDS_icrRequestData 1;
BA_ "Confidence" SG_ 1576 UDS_pcsRequestData 1;
BA_ "Confidence" SG_ 1634 UDS_plgRequestData 1;
BA_ "Confidence" SG_ 1568 UDS_pmRequestData 1;
BA_ "Confidence" SG_ 1604 UDS_pmfRequestData 1;
BA_ "Confidence" SG_ 1540 UDS_pmrRequestData 1;
BA_ "Confidence" SG_ 1734 UDS_ptcRequestData 1;
BA_ "Confidence" SG_ 1664 UDS_sccmRequestData 1;
BA_ "Confidence" SG_ 1723 UDS_sdcrRequestData 1;
BA_ "Confidence" SG_ 1611 UDS_tasRequestData 1;
BA_ "Confidence" SG_ 1548 UDS_vcbatt1RequestData 1;
BA_ "Confidence" SG_ 1562 UDS_vcbatt2RequestData 1;
BA_ "Confidence" SG_ 1633 UDS_vcbattRequestData 1;
BA_ "Confidence" SG_ 1580 UDS_vcfront1RequestData 1;
BA_ "Confidence" SG_ 1582 UDS_vcfront2RequestData 1;
BA_ "Confidence" SG_ 1536 UDS_vcfrontRequestData 1;
BA_ "Confidence" SG_ 1570 UDS_vcleftRequestData_H 1;
BA_ "Confidence" SG_ 1570 UDS_vcleftRequestData_L 1;
BA_ "Confidence" SG_ 1544 UDS_vcrightRequestData_H 1;
BA_ "Confidence" SG_ 1544 UDS_vcrightRequestData_L 1;
BA_ "Confidence" SG_ 1546 UDS_vcsecRequestData 1;
BA_ "Confidence" SG_ 1657 UI_rgbEnableState 0;
BA_ "Confidence" SG_ 1657 UI_rgbEffectType 0;
BA_ "Confidence" SG_ 1657 UI_rgbBrightnessLevel 0;
BA_ "GenSigSNA" SG_ 1657 UI_rgbBrightnessLevel "127";
BA_ "Confidence" SG_ 1657 UI_audioVisualizerState 0;
BA_ "Confidence" SG_ 1657 UI_rgbTargetDOORFL 0;
BA_ "Confidence" SG_ 1657 UI_rgbTargetDOORFR 0;
BA_ "Confidence" SG_ 1657 UI_rgbTargetDOORRL 0;
BA_ "Confidence" SG_ 1657 UI_rgbTargetDOORRR 0;
BA_ "Confidence" SG_ 1657 UI_rgbTargetIPFL 0;
BA_ "Confidence" SG_ 1657 UI_rgbTargetIPFR 0;
BA_ "Confidence" SG_ 1021 UI_autopilotControlIndex 1;
BA_ "Confidence" SG_ 1021 UI_hovEnabled 0;
BA_ "Confidence" SG_ 1021 UI_donDisableAutoWiperDuration 1;
BA_ "Confidence" SG_ 1021 UI_donDisableOnAutoWiperSpeed 1;
BA_ "Confidence" SG_ 1021 UI_blindspotMinSpeed 1;
BA_ "Confidence" SG_ 1021 UI_blindspotDistance 1;
BA_ "Confidence" SG_ 1021 UI_blindspotTTC 1;
BA_ "Confidence" SG_ 1021 UI_donStopEndOfRampBuffer 1;
BA_ "Confidence" SG_ 1021 UI_donDisableCutin 1;
BA_ "Confidence" SG_ 1021 UI_smartSetSpeedOffset 0;
BA_ "Confidence" SG_ 1021 UI_smartSetSpeedOffsetType 0;
BA_ "Confidence" SG_ 1021 UI_fsdStopsControlEnabled 0;
BA_ "Confidence" SG_ 1021 UI_smartSetSpeed 0;
BA_ "Confidence" SG_ 1021 UI_automaticSetSpeedOffset 0;
BA_ "Confidence" SG_ 1021 UI_homelinkNearby 1;
BA_ "Confidence" SG_ 1021 UI_enableFullSelfDriving 0;
BA_ "Confidence" SG_ 1021 UI_hasFullSelfDriving 0;
BA_ "Confidence" SG_ 1021 UI_autosteerActivation 0;
BA_ "Confidence" SG_ 1021 UI_fsdBetaRequest 0;
BA_ "Confidence" SG_ 1021 UI_fullSelfDrivingSuspended 0;
BA_ "Confidence" SG_ 1021 UI_disableOptionalLaneChanges 0;
BA_ "Confidence" SG_ 1021 UI_applyADDWWarnings 0;
BA_ "Confidence" SG_ 1021 UI_selectableCameraRequest 0;
BA_ "GenSigSNA" SG_ 1021 UI_selectableCameraRequest "15";
BA_ "Confidence" SG_ 1021 UI_overrideSleepWithSuspend 1;
BA_ "Confidence" SG_ 1021 UI_driverMonitorConfirmation 0;
BA_ "Confidence" SG_ 1021 UI_parkAssistUseVision 0;
BA_ "Confidence" SG_ 1021 UI_noStalkConfirmAlertHaptic 0;
BA_ "Confidence" SG_ 1021 UI_regulatoryLaneAssistLevel 1;
BA_ "Confidence" SG_ 1021 UI_noStalkConfirmAlertChime 0;
BA_ "Confidence" SG_ 1021 UI_factorySummonEnable 0;
BA_ "Confidence" SG_ 1021 UI_apmv3Branch 1;
BA_ "Confidence" SG_ 1021 UI_enableCabinCamera 0;
BA_ "Confidence" SG_ 1021 UI_enableAutopilotStopWarning 0;
BA_ "Confidence" SG_ 1021 UI_enableVisionSpeedControl 0;
BA_ "Confidence" SG_ 1021 UI_enableTeslaAutopark 0;
BA_ "Confidence" SG_ 1021 UI_autoTurnSignalMode 0;
BA_ "Confidence" SG_ 1021 UI_enableCabinAudioRecording 0;
BA_ "SystemSignalLongSymbol" SG_ 1021 UI_enableApproachingEmergencyVeh "UI_enableApproachingEmergencyVehicleDetection";
BA_ "SystemSignalLongSymbol" SG_ 1021 UI_enableStartFsdFromParkBrakeCo "UI_enableStartFsdFromParkBrakeConfirmation";
BA_ "Confidence" SG_ 1021 UI_fsdMaxSpeedOffsetPercentage 1;
BA_ "Confidence" SG_ 1021 UI_navMinutesToArrival 1;
BA_ "Confidence" SG_ 1021 UI_autopilotDrivingProfile 0;
BA_ "Confidence" SG_ 819 UI_openChargePortDoorRequest 0;
BA_ "Confidence" SG_ 819 UI_closeChargePortDoorRequest 0;
BA_ "Confidence" SG_ 819 UI_chargeEnableRequest 0;
BA_ "Confidence" SG_ 819 UI_brickVLoggingRequest 1;
BA_ "Confidence" SG_ 819 UI_brickBalancingDisabled 1;
BA_ "Confidence" SG_ 819 UI_acChargeCurrentLimit 0;
BA_ "GenSigSNA" SG_ 819 UI_acChargeCurrentLimit "127";
BA_ "Confidence" SG_ 819 UI_chargeTerminationPct 0;
BA_ "Confidence" SG_ 819 UI_scheduledDepartureEnabled 0;
BA_ "Confidence" SG_ 819 UI_chargePortLatchRequest 0;
BA_ "Confidence" SG_ 819 UI_socSnapshotExpirationTime 1;
BA_ "Confidence" SG_ 819 UI_cpInletHeaterRequest 0;
BA_ "Confidence" SG_ 659 UI_steeringTuneRequest 0;
BA_ "Confidence" SG_ 659 UI_tractionControlMode 0;
BA_ "Confidence" SG_ 659 UI_parkBrakeRequest 0;
BA_ "GenSigSNA" SG_ 659 UI_parkBrakeRequest "3";
BA_ "Confidence" SG_ 659 UI_winchModeRequest 0;
BA_ "Confidence" SG_ 659 UI_zeroSpeedConfirmed 1;
BA_ "GenSigSNA" SG_ 659 UI_zeroSpeedConfirmed "3";
BA_ "Confidence" SG_ 659 UI_trailerMode 0;
BA_ "Confidence" SG_ 659 UI_distanceUnits 1;
BA_ "Confidence" SG_ 659 UI_accOvertakeEnable 0;
BA_ "GenSigSNA" SG_ 659 UI_accOvertakeEnable "3";
BA_ "Confidence" SG_ 659 UI_aebEnable 0;
BA_ "GenSigSNA" SG_ 659 UI_aebEnable "3";
BA_ "Confidence" SG_ 659 UI_aesEnable 0;
BA_ "GenSigSNA" SG_ 659 UI_aesEnable "3";
BA_ "Confidence" SG_ 659 UI_ahlbEnable 0;
BA_ "GenSigSNA" SG_ 659 UI_ahlbEnable "3";
BA_ "Confidence" SG_ 659 UI_autoLaneChangeEnable 0;
BA_ "GenSigSNA" SG_ 659 UI_autoLaneChangeEnable "3";
BA_ "Confidence" SG_ 659 UI_winchProxUserOverride 0;
BA_ "Confidence" SG_ 659 UI_autoParkRequest 0;
BA_ "GenSigSNA" SG_ 659 UI_autoParkRequest "15";
BA_ "Confidence" SG_ 659 UI_bsdEnable 0;
BA_ "GenSigSNA" SG_ 659 UI_bsdEnable "3";
BA_ "Confidence" SG_ 659 UI_fcwEnable 0;
BA_ "GenSigSNA" SG_ 659 UI_fcwEnable "3";
BA_ "Confidence" SG_ 659 UI_fcwSensitivity 0;
BA_ "GenSigSNA" SG_ 659 UI_fcwSensitivity "3";
BA_ "Confidence" SG_ 659 UI_latControlEnable 0;
BA_ "GenSigSNA" SG_ 659 UI_latControlEnable "3";
BA_ "Confidence" SG_ 659 UI_ldwEnable 0;
BA_ "GenSigSNA" SG_ 659 UI_ldwEnable "3";
BA_ "Confidence" SG_ 659 UI_pedalSafetyEnable 1;
BA_ "GenSigSNA" SG_ 659 UI_pedalSafetyEnable "3";
BA_ "Confidence" SG_ 659 UI_pedalMap_epas 1;
BA_ "Confidence" SG_ 659 UI_redLightStopSignEnable 1;
BA_ "GenSigSNA" SG_ 659 UI_redLightStopSignEnable "3";
BA_ "Confidence" SG_ 659 UI_selfParkTune 1;
BA_ "GenSigSNA" SG_ 659 UI_selfParkTune "15";
BA_ "Confidence" SG_ 1280 UI_debugEcuTarget 1;
BA_ "Confidence" SG_ 2043 UI_debugDampingRequestFLC 1;
BA_ "GenSigSNA" SG_ 2043 UI_debugDampingRequestFLC "255";
BA_ "Confidence" SG_ 2043 UI_debugDampingRequestFLR 1;
BA_ "GenSigSNA" SG_ 2043 UI_debugDampingRequestFLR "255";
BA_ "Confidence" SG_ 2043 UI_debugDampingRequestFRC 1;
BA_ "GenSigSNA" SG_ 2043 UI_debugDampingRequestFRC "255";
BA_ "Confidence" SG_ 2043 UI_debugDampingRequestFRR 1;
BA_ "GenSigSNA" SG_ 2043 UI_debugDampingRequestFRR "255";
BA_ "Confidence" SG_ 2043 UI_debugDampingRequestRLC 1;
BA_ "GenSigSNA" SG_ 2043 UI_debugDampingRequestRLC "255";
BA_ "Confidence" SG_ 2043 UI_debugDampingRequestRLR 1;
BA_ "GenSigSNA" SG_ 2043 UI_debugDampingRequestRLR "255";
BA_ "Confidence" SG_ 2043 UI_debugDampingRequestRRC 1;
BA_ "GenSigSNA" SG_ 2043 UI_debugDampingRequestRRC "255";
BA_ "Confidence" SG_ 2043 UI_debugDampingRequestRRR 1;
BA_ "GenSigSNA" SG_ 2043 UI_debugDampingRequestRRR "255";
BA_ "Confidence" SG_ 568 UI_mapSpeedLimitDependency 1;
BA_ "GenSigSNA" SG_ 568 UI_mapSpeedLimitDependency "7";
BA_ "Confidence" SG_ 568 UI_roadClass 0;
BA_ "GenSigSNA" SG_ 568 UI_roadClass "0";
BA_ "Confidence" SG_ 568 UI_mapSpeedUnits 1;
BA_ "Confidence" SG_ 568 UI_mapSpeedLimit 1;
BA_ "GenSigSNA" SG_ 568 UI_mapSpeedLimit "31";
BA_ "Confidence" SG_ 568 UI_mapSpeedLimitType 1;
BA_ "GenSigSNA" SG_ 568 UI_mapSpeedLimitType "7";
BA_ "Confidence" SG_ 568 UI_countryCode 1;
BA_ "GenSigSNA" SG_ 568 UI_countryCode "1023";
BA_ "Confidence" SG_ 568 UI_navRouteActive 0;
BA_ "Confidence" SG_ 568 UI_parallelAutoparkEnabled 0;
BA_ "Confidence" SG_ 568 UI_perpendicularAutoparkEnabled 0;
BA_ "Confidence" SG_ 568 UI_nextBranchDist 1;
BA_ "GenSigSNA" SG_ 568 UI_nextBranchDist "31";
BA_ "Confidence" SG_ 568 UI_controlledAccess 0;
BA_ "Confidence" SG_ 568 UI_autosteerRestricted 0;
BA_ "Confidence" SG_ 645 UI_driverProfileRecallIndex 1;
BA_ "GenSigSNA" SG_ 645 UI_driverProfileRecallIndex "0";
BA_ "Confidence" SG_ 645 UI_driverProfileRecallStop 0;
BA_ "Confidence" SG_ 645 UI_frontSeatRecallActive 0;
BA_ "Confidence" SG_ 645 UI_frontSeatTrackPos 1;
BA_ "Confidence" SG_ 645 UI_frontSeatBackPos 1;
BA_ "Confidence" SG_ 645 UI_frontSeatLiftPos 1;
BA_ "Confidence" SG_ 645 UI_frontSeatTiltPos 1;
BA_ "Confidence" SG_ 645 UI_steeringColumnUpDownPos 1;
BA_ "Confidence" SG_ 645 UI_lumbarAPressurePercentage 1;
BA_ "GenSigSNA" SG_ 645 UI_lumbarAPressurePercentage "127";
BA_ "Confidence" SG_ 645 UI_lumbarBPressurePercentage 1;
BA_ "GenSigSNA" SG_ 645 UI_lumbarBPressurePercentage "127";
BA_ "Confidence" SG_ 645 UI_steeringColumnInOutPos 1;
BA_ "Confidence" SG_ 645 UI_leftMirrorTiltXPosition 0;
BA_ "Confidence" SG_ 645 UI_leftMirrorTiltYPosition 0;
BA_ "Confidence" SG_ 645 UI_rightMirrorTiltXPosition 1;
BA_ "Confidence" SG_ 645 UI_rightMirrorTiltYPosition 1;
BA_ "Confidence" SG_ 645 UI_frontSeatThighSupportPos 1;
BA_ "Confidence" SG_ 645 UI_customMirrorDipPositionsSet 0;
BA_ "Confidence" SG_ 645 UI_leftMirrorDipXPosition 0;
BA_ "Confidence" SG_ 645 UI_leftMirrorDipYPosition 0;
BA_ "Confidence" SG_ 645 UI_rightMirrorDipXPosition 1;
BA_ "Confidence" SG_ 645 UI_rightMirrorDipYPosition 1;
BA_ "Confidence" SG_ 645 UI_modifyMirrorDipRequest 0;
BA_ "Confidence" SG_ 651 UI_driverProfileLinkedKeySHA1 1;
BA_ "GenSigSNA" SG_ 651 UI_driverProfileLinkedKeySHA1 "4294967295";
BA_ "Confidence" SG_ 651 UI_driverProfileIndex 0;
BA_ "Confidence" SG_ 651 UI_driverProfileSelectionType 0;
BA_ "Confidence" SG_ 651 UI_driverProfilePositionAdjusted 0;
BA_ "Confidence" SG_ 651 UI_activeKeyRequested 0;
BA_ "Confidence" SG_ 984 UI_elevation 1;
BA_ "GenSigSNA" SG_ 984 UI_elevation "8191";
BA_ "Confidence" SG_ 984 UI_navElevation 1;
BA_ "GenSigSNA" SG_ 984 UI_navElevation "8191";
BA_ "Confidence" SG_ 1139 UI_nmKeepAwakeReason 0;
BA_ "GenSigSNA" SG_ 1139 UI_nmKeepAwakeReason "0";
BA_ "Confidence" SG_ 1139 UI_wakeupTime 0;
BA_ "Confidence" SG_ 1267 UI_seatAdjustmentSource 1;
BA_ "Confidence" SG_ 883 UI_gpsHDOP 1;
BA_ "Confidence" SG_ 883 UI_gpsVehicleHeading 1;
BA_ "Confidence" SG_ 883 UI_gpsVehicleSpeed 1;
BA_ "Confidence" SG_ 883 UI_userSpeedOffset 1;
BA_ "Confidence" SG_ 883 UI_mapSpeedLimitUnits 0;
BA_ "Confidence" SG_ 883 UI_userSpeedOffsetUnits 1;
BA_ "Confidence" SG_ 883 UI_mppSpeedLimit 0;
BA_ "Confidence" SG_ 883 UI_gpsNmeaMIA 0;
BA_ "Confidence" SG_ 883 UI_gpsAntennaDisconnected 0;
BA_ "Confidence" SG_ 883 UI_conditionalLimitActive 0;
BA_ "Confidence" SG_ 883 UI_conditionalSpeedLimit 0;
BA_ "GenSigSNA" SG_ 883 UI_conditionalSpeedLimit "31";
BA_ "Confidence" SG_ 912 UI_dischargeTerminationPct 0;
BA_ "Confidence" SG_ 912 UI_powershareRequest 0;
BA_ "Confidence" SG_ 755 UI_hvacReqTempSetpointLeft 0;
BA_ "Confidence" SG_ 755 UI_hvacReqAutoBlowerLevel 0;
BA_ "Confidence" SG_ 755 UI_hvacReqTempSetpointRight 0;
BA_ "Confidence" SG_ 755 UI_hvacReqAirDistributionMode 0;
BA_ "Confidence" SG_ 755 UI_hvacReqBlowerSegment 0;
BA_ "Confidence" SG_ 755 UI_hvacReqRecirc 0;
BA_ "Confidence" SG_ 755 UI_hvacReqACDisable 0;
BA_ "Confidence" SG_ 755 UI_hvacDefogState 0;
BA_ "Confidence" SG_ 755 UI_hvacReqUserPowerState 0;
BA_ "Confidence" SG_ 755 UI_hvacReqSecondRowState 0;
BA_ "Confidence" SG_ 755 UI_hvacReqKeepClimateOn 0;
BA_ "Confidence" SG_ 755 UI_hvacReqBioWeaponDefMode 0;
BA_ "SystemSignalLongSymbol" SG_ 755 UI_hvacPhoneCallAirFlowAdjustEna "UI_hvacPhoneCallAirFlowAdjustEnabled";
BA_ "SystemSignalLongSymbol" SG_ 755 UI_enableHvacWeatherDataBasedHum "UI_enableHvacWeatherDataBasedHumidityControls";
BA_ "Confidence" SG_ 755 UI_hvacReqTempSetpointCOP 0;
BA_ "Confidence" SG_ 755 UI_hvacClimateNudgeStatus 1;
BA_ "Confidence" SG_ 777 UI_latitude 1;
BA_ "Confidence" SG_ 777 UI_longitude 1;
BA_ "Confidence" SG_ 777 UI_gpsAccuracy 1;
BA_ "GenSigSNA" SG_ 777 UI_gpsAccuracy "127";
BA_ "Confidence" SG_ 1523 UI_odometer 0;
BA_ "GenSigSNA" SG_ 1523 UI_odometer "16777215";
BA_ "Confidence" SG_ 948 UI_usbFrontHubPowerStateRequest 0;
BA_ "GenSigSNA" SG_ 948 UI_usbFrontHubPowerStateRequest "0";
BA_ "Confidence" SG_ 955 UI_powerExpected 1;
BA_ "Confidence" SG_ 955 UI_powerIdeal 1;
BA_ "Confidence" SG_ 955 UI_dSocAlertEnable 0;
BA_ "Confidence" SG_ 955 UI_dSocAlertThreshold 1;
BA_ "Confidence" SG_ 827 UI_idlePowerConsumption 0;
BA_ "Confidence" SG_ 827 UI_chargeTimeUntilTerminationPct 0;
BA_ "GenSigSNA" SG_ 827 UI_chargeTimeUntilTerminationPct "2047";
BA_ "Confidence" SG_ 827 UI_chargeTimeUntilReadyToDepart 0;
BA_ "GenSigSNA" SG_ 827 UI_chargeTimeUntilReadyToDepart "2047";
BA_ "Confidence" SG_ 661 UI_powerRationalityConfigIndex 1;
BA_ "Confidence" SG_ 661 UI_vcleftCfgRationalityThreshold 1;
BA_ "GenSigSNA" SG_ 661 UI_vcleftCfgRationalityThreshold "0";
BA_ "SystemSignalLongSymbol" SG_ 661 UI_vcleftCfgRationalityThreshold "UI_vcleftCfgRationalityThreshold0";
BA_ "Confidence" SG_ 661 UI_vcleftCfgRationalityTime0 1;
BA_ "GenSigSNA" SG_ 661 UI_vcleftCfgRationalityTime0 "0";
BA_ "Confidence" SG_ 661 UI_vcleftCfgRationalityThre_0001 1;
BA_ "GenSigSNA" SG_ 661 UI_vcleftCfgRationalityThre_0001 "0";
BA_ "SystemSignalLongSymbol" SG_ 661 UI_vcleftCfgRationalityThre_0001 "UI_vcleftCfgRationalityThreshold1";
BA_ "Confidence" SG_ 661 UI_vcleftCfgRationalityTime1 1;
BA_ "GenSigSNA" SG_ 661 UI_vcleftCfgRationalityTime1 "0";
BA_ "Confidence" SG_ 661 UI_vcleftCfgRationalityStaticA 1;
BA_ "GenSigSNA" SG_ 661 UI_vcleftCfgRationalityStaticA "65535";
BA_ "Confidence" SG_ 661 UI_vcleftCfgRationalityStaticB 1;
BA_ "GenSigSNA" SG_ 661 UI_vcleftCfgRationalityStaticB "32768";
BA_ "Confidence" SG_ 661 UI_vcleftCfgRationalityStaticC 1;
BA_ "GenSigSNA" SG_ 661 UI_vcleftCfgRationalityStaticC "32768";
BA_ "Confidence" SG_ 661 UI_vcleftCfgRationalityDynamicA 1;
BA_ "GenSigSNA" SG_ 661 UI_vcleftCfgRationalityDynamicA "65535";
BA_ "Confidence" SG_ 661 UI_vcleftCfgRationalityDynamicB 1;
BA_ "GenSigSNA" SG_ 661 UI_vcleftCfgRationalityDynamicB "32768";
BA_ "Confidence" SG_ 661 UI_vcleftCfgRationalityDynamicC 1;
BA_ "GenSigSNA" SG_ 661 UI_vcleftCfgRationalityDynamicC "32768";
BA_ "Confidence" SG_ 661 UI_vcrightCfgRationalityThreshol 1;
BA_ "GenSigSNA" SG_ 661 UI_vcrightCfgRationalityThreshol "0";
BA_ "SystemSignalLongSymbol" SG_ 661 UI_vcrightCfgRationalityThreshol "UI_vcrightCfgRationalityThreshold0";
BA_ "Confidence" SG_ 661 UI_vcrightCfgRationalityTime0 1;
BA_ "GenSigSNA" SG_ 661 UI_vcrightCfgRationalityTime0 "0";
BA_ "Confidence" SG_ 661 UI_vcrightCfgRationalityThr_0001 1;
BA_ "GenSigSNA" SG_ 661 UI_vcrightCfgRationalityThr_0001 "0";
BA_ "SystemSignalLongSymbol" SG_ 661 UI_vcrightCfgRationalityThr_0001 "UI_vcrightCfgRationalityThreshold1";
BA_ "Confidence" SG_ 661 UI_vcrightCfgRationalityTime1 1;
BA_ "GenSigSNA" SG_ 661 UI_vcrightCfgRationalityTime1 "0";
BA_ "Confidence" SG_ 661 UI_vcrightCfgRationalityStaticA 1;
BA_ "GenSigSNA" SG_ 661 UI_vcrightCfgRationalityStaticA "65535";
BA_ "Confidence" SG_ 661 UI_vcrightCfgRationalityStaticB 1;
BA_ "GenSigSNA" SG_ 661 UI_vcrightCfgRationalityStaticB "32768";
BA_ "Confidence" SG_ 661 UI_vcrightCfgRationalityStaticC 1;
BA_ "GenSigSNA" SG_ 661 UI_vcrightCfgRationalityStaticC "32768";
BA_ "Confidence" SG_ 661 UI_vcrightCfgRationalityDynamicA 1;
BA_ "GenSigSNA" SG_ 661 UI_vcrightCfgRationalityDynamicA "65535";
BA_ "Confidence" SG_ 661 UI_vcrightCfgRationalityDynamicB 1;
BA_ "GenSigSNA" SG_ 661 UI_vcrightCfgRationalityDynamicB "32768";
BA_ "Confidence" SG_ 661 UI_vcrightCfgRationalityDynamicC 1;
BA_ "GenSigSNA" SG_ 661 UI_vcrightCfgRationalityDynamicC "32768";
BA_ "Confidence" SG_ 661 UI_vcleftCfgCutoffThreshold0 1;
BA_ "GenSigSNA" SG_ 661 UI_vcleftCfgCutoffThreshold0 "0";
BA_ "Confidence" SG_ 661 UI_vcleftCfgCutoffTime0 1;
BA_ "GenSigSNA" SG_ 661 UI_vcleftCfgCutoffTime0 "0";
BA_ "Confidence" SG_ 661 UI_vcleftCfgCutoffThreshold1 1;
BA_ "GenSigSNA" SG_ 661 UI_vcleftCfgCutoffThreshold1 "0";
BA_ "Confidence" SG_ 661 UI_vcleftCfgCutoffTime1 1;
BA_ "GenSigSNA" SG_ 661 UI_vcleftCfgCutoffTime1 "0";
BA_ "Confidence" SG_ 661 UI_vcleftCfgCutoffStaticA 1;
BA_ "GenSigSNA" SG_ 661 UI_vcleftCfgCutoffStaticA "65535";
BA_ "Confidence" SG_ 661 UI_vcleftCfgCutoffStaticB 1;
BA_ "GenSigSNA" SG_ 661 UI_vcleftCfgCutoffStaticB "32768";
BA_ "Confidence" SG_ 661 UI_vcleftCfgCutoffStaticC 1;
BA_ "GenSigSNA" SG_ 661 UI_vcleftCfgCutoffStaticC "32768";
BA_ "Confidence" SG_ 661 UI_vcleftCfgCutoffDynamicA 1;
BA_ "GenSigSNA" SG_ 661 UI_vcleftCfgCutoffDynamicA "65535";
BA_ "Confidence" SG_ 661 UI_vcleftCfgCutoffDynamicB 1;
BA_ "GenSigSNA" SG_ 661 UI_vcleftCfgCutoffDynamicB "32768";
BA_ "Confidence" SG_ 661 UI_vcleftCfgCutoffDynamicC 1;
BA_ "GenSigSNA" SG_ 661 UI_vcleftCfgCutoffDynamicC "32768";
BA_ "Confidence" SG_ 661 UI_vcrightCfgCutoffThreshold0 1;
BA_ "GenSigSNA" SG_ 661 UI_vcrightCfgCutoffThreshold0 "0";
BA_ "Confidence" SG_ 661 UI_vcrightCfgCutoffTime0 1;
BA_ "GenSigSNA" SG_ 661 UI_vcrightCfgCutoffTime0 "0";
BA_ "Confidence" SG_ 661 UI_vcrightCfgCutoffThreshold1 1;
BA_ "GenSigSNA" SG_ 661 UI_vcrightCfgCutoffThreshold1 "0";
BA_ "Confidence" SG_ 661 UI_vcrightCfgCutoffTime1 1;
BA_ "GenSigSNA" SG_ 661 UI_vcrightCfgCutoffTime1 "0";
BA_ "Confidence" SG_ 661 UI_vcrightCfgCutoffStaticA 1;
BA_ "GenSigSNA" SG_ 661 UI_vcrightCfgCutoffStaticA "65535";
BA_ "Confidence" SG_ 661 UI_vcrightCfgCutoffStaticB 1;
BA_ "GenSigSNA" SG_ 661 UI_vcrightCfgCutoffStaticB "32768";
BA_ "Confidence" SG_ 661 UI_vcrightCfgCutoffStaticC 1;
BA_ "GenSigSNA" SG_ 661 UI_vcrightCfgCutoffStaticC "32768";
BA_ "Confidence" SG_ 661 UI_vcrightCfgCutoffDynamicA 1;
BA_ "GenSigSNA" SG_ 661 UI_vcrightCfgCutoffDynamicA "65535";
BA_ "Confidence" SG_ 661 UI_vcrightCfgCutoffDynamicB 1;
BA_ "GenSigSNA" SG_ 661 UI_vcrightCfgCutoffDynamicB "32768";
BA_ "Confidence" SG_ 661 UI_vcrightCfgCutoffDynamicC 1;
BA_ "GenSigSNA" SG_ 661 UI_vcrightCfgCutoffDynamicC "32768";
BA_ "Confidence" SG_ 820 UI_systemPowerLimit 1;
BA_ "GenSigSNA" SG_ 820 UI_systemPowerLimit "31";
BA_ "Confidence" SG_ 820 UI_pedalMap 0;
BA_ "Confidence" SG_ 820 UI_enableRegenBackfill 0;
BA_ "Confidence" SG_ 820 UI_systemTorqueLimit 1;
BA_ "GenSigSNA" SG_ 820 UI_systemTorqueLimit "63";
BA_ "Confidence" SG_ 820 UI_closureConfirmed 1;
BA_ "Confidence" SG_ 820 UI_regenTorqueMax 0;
BA_ "Confidence" SG_ 820 UI_limitMode 0;
BA_ "SystemSignalLongSymbol" SG_ 820 UI_factoryCustomerDrivingModeReq "UI_factoryCustomerDrivingModeRequest";
BA_ "Confidence" SG_ 820 UI_motorOnMode 0;
BA_ "Confidence" SG_ 820 UI_stoppingMode 0;
BA_ "Confidence" SG_ 820 UI_speedLimit 0;
BA_ "GenSigSNA" SG_ 820 UI_speedLimit "511";
BA_ "Confidence" SG_ 820 UI_enableSmartShift 0;
BA_ "Confidence" SG_ 820 UI_navVehParallelToRdCanContinue 0;
BA_ "GenSigSNA" SG_ 820 UI_navVehParallelToRdCanContinue "0";
BA_ "Confidence" SG_ 826 UI_ratedRange 0;
BA_ "Confidence" SG_ 826 UI_soe 0;
BA_ "Confidence" SG_ 826 UI_uSoe 0;
BA_ "Confidence" SG_ 826 UI_softPackLimitPct 1;
BA_ "Confidence" SG_ 826 UI_targetFullPackEnergy 1;
BA_ "Confidence" SG_ 723 UI_solarAzimuthAngle 1;
BA_ "GenSigSNA" SG_ 723 UI_solarAzimuthAngle "32768";
BA_ "Confidence" SG_ 723 UI_solarAzimuthAngleCarRef 1;
BA_ "GenSigSNA" SG_ 723 UI_solarAzimuthAngleCarRef "255";
BA_ "Confidence" SG_ 723 UI_isSunUp 0;
BA_ "GenSigSNA" SG_ 723 UI_isSunUp "3";
BA_ "Confidence" SG_ 723 UI_solarElevationAngle 0;
BA_ "GenSigSNA" SG_ 723 UI_solarElevationAngle "127";
BA_ "Confidence" SG_ 723 UI_screenPCBTemperature 0;
BA_ "Confidence" SG_ 723 UI_minsToSunset 0;
BA_ "Confidence" SG_ 723 UI_minsToSunrise 0;
VAL_ 852 TAS_matrixIndex 5 "AlertMatrix5" 4 "AlertMatrix4" 3 "AlertMatrix3" 2 "AlertMatrix2" 1 "AlertMatrix1" 0 "AlertMatrix0" ;
VAL_ 523 TAS_axleIndex 1 "axleRear" 0 "axleFront" ;
VAL_ 523 TAS_rawHeightFL 1023 "SNA" ;
VAL_ 523 TAS_staticHeightEstimateFL 1023 "SNA" ;
VAL_ 523 TAS_componentPressureFL 255 "SNA" ;
VAL_ 523 TAS_rawHeightFR 1023 "SNA" ;
VAL_ 523 TAS_staticHeightEstimateFR 1023 "SNA" ;
VAL_ 523 TAS_componentPressureFR 255 "SNA" ;
VAL_ 523 TAS_rawHeightRL 1023 "SNA" ;
VAL_ 523 TAS_staticHeightEstimateRL 1023 "SNA" ;
VAL_ 523 TAS_componentPressureRL 255 "SNA" ;
VAL_ 523 TAS_rawHeightRR 1023 "SNA" ;
VAL_ 523 TAS_staticHeightEstimateRR 1023 "SNA" ;
VAL_ 523 TAS_componentPressureRR 255 "SNA" ;
VAL_ 1398 TAS_endstopState 1 "TAS_DAMPING_STATE_ACTIVE" 0 "TAS_DAMPING_STATE_STANDBY" ;
VAL_ 1398 TAS_continuousControlState 1 "TAS_DAMPING_STATE_ACTIVE" 0 "TAS_DAMPING_STATE_STANDBY" ;
VAL_ 1398 TAS_activeTireTune 1 "TAS_TIRE_TUNE_MICHELIN_SUMMER_21" 0 "TAS_TIRE_TUNE_DEFAULT" ;
VAL_ 1398 TAS_roughnessRaiseReason 2 "TAS_ROUGHNESS_RAISE_REASON_LOOKAHEAD" 1 "TAS_ROUGHNESS_RAISE_REASON_LEGACY" 0 "TAS_ROUGHNESS_RAISE_REASON_NONE" ;
VAL_ 1398 TAS_frontMetricDrivesRear 3 "TAS_ACTION_ACTIVE" 2 "TAS_ACTION_ARMED" 1 "TAS_ACTION_STANDBY" 0 "TAS_ACTION_DISABLED" ;
VAL_ 1398 TAS_roadCondition 255 "SNA" ;
VAL_ 1398 TAS_bellyProtect 3 "TAS_ACTION_ACTIVE" 2 "TAS_ACTION_ARMED" 1 "TAS_ACTION_STANDBY" 0 "TAS_ACTION_DISABLED" ;
VAL_ 1398 TAS_frontMetricDrivesFront 3 "TAS_ACTION_ACTIVE" 2 "TAS_ACTION_ARMED" 1 "TAS_ACTION_STANDBY" 0 "TAS_ACTION_DISABLED" ;
VAL_ 1398 TAS_speedBumpAxleFront 4 "TAS_ACTION_CANCELED" 3 "TAS_ACTION_ACTIVE" 2 "TAS_ACTION_ARMED" 1 "TAS_ACTION_STANDBY" 0 "TAS_ACTION_DISABLED" ;
VAL_ 1398 TAS_speedBumpAxleRear 4 "TAS_ACTION_CANCELED" 3 "TAS_ACTION_ACTIVE" 2 "TAS_ACTION_ARMED" 1 "TAS_ACTION_STANDBY" 0 "TAS_ACTION_DISABLED" ;
VAL_ 1398 TAS_holeProtectFL 3 "TAS_ACTION_ACTIVE" 2 "TAS_ACTION_ARMED" 1 "TAS_ACTION_STANDBY" 0 "TAS_ACTION_DISABLED" ;
VAL_ 1398 TAS_holeProtectFR 3 "TAS_ACTION_ACTIVE" 2 "TAS_ACTION_ARMED" 1 "TAS_ACTION_STANDBY" 0 "TAS_ACTION_DISABLED" ;
VAL_ 1398 TAS_holeProtectRL 3 "TAS_ACTION_ACTIVE" 2 "TAS_ACTION_ARMED" 1 "TAS_ACTION_STANDBY" 0 "TAS_ACTION_DISABLED" ;
VAL_ 1398 TAS_holeProtectRR 3 "TAS_ACTION_ACTIVE" 2 "TAS_ACTION_ARMED" 1 "TAS_ACTION_STANDBY" 0 "TAS_ACTION_DISABLED" ;
VAL_ 1398 TAS_stepProtectFL 3 "TAS_ACTION_ACTIVE" 2 "TAS_ACTION_ARMED" 1 "TAS_ACTION_STANDBY" 0 "TAS_ACTION_DISABLED" ;
VAL_ 1398 TAS_stepProtectFR 3 "TAS_ACTION_ACTIVE" 2 "TAS_ACTION_ARMED" 1 "TAS_ACTION_STANDBY" 0 "TAS_ACTION_DISABLED" ;
VAL_ 1398 TAS_stepProtectRL 3 "TAS_ACTION_ACTIVE" 2 "TAS_ACTION_ARMED" 1 "TAS_ACTION_STANDBY" 0 "TAS_ACTION_DISABLED" ;
VAL_ 1398 TAS_stepProtectRR 3 "TAS_ACTION_ACTIVE" 2 "TAS_ACTION_ARMED" 1 "TAS_ACTION_STANDBY" 0 "TAS_ACTION_DISABLED" ;
VAL_ 1398 TAS_FDUTorqueCorruptionScale 15 "SNA" ;
VAL_ 1398 TAS_sprungMassEstimate 31 "SNA" ;
VAL_ 1357 TAS_infoIndex 255 "END" 41 "SUBCOMPONENT14" 40 "SUBCOMPONENT13" 39 "SUBCOMPONENT12" 38 "SUBCOMPONENT11" 37 "SUBCOMPONENT10" 36 "SUBCOMPONENT9" 35 "SUBCOMPONENT8" 34 "SUBCOMPONENT7" 33 "SUBCOMPONENT6" 32 "SUBCOMPONENT5" 31 "SUBCOMPONENT4" 24 "SUBCOMPONENT3" 23 "SUBCOMPONENT2" 20 "UDS_PROTOCOL_BOOTCRC" 19 "VERSION_DEPRECATED" 18 "BOOTLOADER_GITHASH" 17 "APP_GITHASH" 16 "SUBCOMPONENT1" 15 "BOOTLOADER_CRC" 14 "BOOTLOADER_SVN" 13 "APP_CRC" 11 "PCBAID_ASSYID_USAGEID" 10 "BUILD_HWID_COMPONENTID" 9 "DEPRECATED_9" 8 "DEPRECATED_8" 7 "DEPRECATED_7" 6 "DEPRECATED_6" 5 "DEPRECATED_5" 4 "DEPRECATED_4" 3 "DEPRECATED_3" 2 "DEPRECATED_2" 1 "DEPRECATED_1" 0 "DEPRECATED_0" ;
VAL_ 1357 TAS_infoBuildType 4 "INFO_MFG_BUILD" 3 "INFO_TRACEABLE_CI_BUILD" 2 "INFO_LOCAL_BUILD" 1 "INFO_PLATFORM_BUILD" 0 "INFO_UNKNOWN_BUILD" ;
VAL_ 1357 TAS_infoAssemblyId 255 "ASSEMBLY_SNA" 1 "ASSEMBLY1" ;
VAL_ 1357 TAS_infoMajorVersion 255 "SNA" 254 "LOCAL_BUILD" ;
VAL_ 1357 TAS_infoBranchOrigin 255 "SNA" 254 "LOCAL_BUILD" ;
VAL_ 1357 TAS_infoMaturity 255 "SNA" 254 "LOCAL_BUILD" ;
VAL_ 1357 TAS_infoHardwareRevision 255 "SNA" 254 "LOCAL_BUILD" ;
VAL_ 525 TAS_levelingState 15 "LEVELING_STATE_CROSSLINK" 14 "LEVELING_STATE_QUIET_EXHAUST" 13 "LEVELING_STATE_EXHAUST_RESERVOIR" 12 "LEVELING_STATE_LOWER_SPRING_WITH_COMPRESSOR" 11 "LEVELING_STATE_LOWER_SPRING" 10 "LEVELING_STATE_FILL_SPRING_RESERVOIR_FROM_COMPRESSOR" 9 "LEVELING_STATE_FILL_SPRING_FROM_RESERVOIR" 8 "LEVELING_STATE_FILL_SPRING_FROM_BOOST" 7 "LEVELING_STATE_FILL_SPRING_FROM_COMPRESSOR" 6 "LEVELING_STATE_FILL_RESERVOIR_FROM_COMPRESSOR" 5 "LEVELING_STATE_COMPRESSOR_PREFILL_GALLERY" 4 "LEVELING_STATE_COMPRESSOR_RAMPUP" 3 "LEVELING_STATE_EXHAUST_GALLERY" 2 "LEVELING_STATE_MEASURE_SPRING_PRESSURE" 1 "LEVELING_STATE_READ_P_RESERVOIR" 0 "LEVELING_STATE_IDLE" ;
VAL_ 525 TAS_levelingItem 7 "TAS_LEVELING_ITEM_ALL" 6 "TAS_LEVELING_ITEM_REAR_AXLE" 5 "TAS_LEVELING_ITEM_FRONT_AXLE" 4 "TAS_LEVELING_ITEM_RR" 3 "TAS_LEVELING_ITEM_RL" 2 "TAS_LEVELING_ITEM_FR" 1 "TAS_LEVELING_ITEM_FL" 0 "TAS_LEVELING_ITEM_NONE" ;
VAL_ 525 TAS_pressureGallery 255 "SNA" ;
VAL_ 525 TAS_pressureReservoir 255 "SNA" ;
VAL_ 525 TAS_runMode 7 "RUN_MODE_DYNO" 6 "RUN_MODE_LOW_POWER" 5 "RUN_MODE_NORMAL" 4 "RUN_MODE_DAN" 3 "RUN_MODE_ASSEMBLY" 2 "RUN_MODE_SERVICE" 1 "RUN_MODE_SYSTEM_CHECK" 0 "RUN_MODE_INIT" ;
VAL_ 525 TAS_filterMode 7 "MODE_STOPPING" 6 "MODE_DRIVE" 5 "MODE_LOADING" 4 "MODE_READY" 3 "MODE_TEST" 2 "MODE_CALIBRATE" 1 "MODE_INIT" 0 "MODE_NONE" ;
VAL_ 525 TAS_limpHomeMode 4 "LIMP_HOME_MODE_40" 3 "LIMP_HOME_MODE_30" 2 "LIMP_HOME_MODE_20" 1 "LIMP_HOME_MODE_10" 0 "LIMP_HOME_MODE_0" ;
VAL_ 525 TAS_targetLevel 4 "TAS_VERY_LOW" 3 "TAS_LOW" 2 "TAS_STANDARD" 1 "TAS_HIGH" 0 "TAS_VERY_HIGH" ;
VAL_ 525 TAS_currentLevel 4 "TAS_VERY_LOW" 3 "TAS_LOW" 2 "TAS_STANDARD" 1 "TAS_HIGH" 0 "TAS_VERY_HIGH" ;
VAL_ 409 TAS_adaptiveActivityFL_C 31 "SNA" ;
VAL_ 409 TAS_adaptiveActivityFL_R 31 "SNA" ;
VAL_ 409 TAS_adaptiveActivityFR_C 31 "SNA" ;
VAL_ 409 TAS_adaptiveActivityFR_R 31 "SNA" ;
VAL_ 409 TAS_adaptiveActivityRL_C 31 "SNA" ;
VAL_ 409 TAS_adaptiveActivityRL_R 31 "SNA" ;
VAL_ 409 TAS_adaptiveActivityRR_C 31 "SNA" ;
VAL_ 409 TAS_adaptiveActivityRR_R 31 "SNA" ;
VAL_ 409 TAS_uiHeightFL 63 "SNA" ;
VAL_ 409 TAS_uiHeightFR 63 "SNA" ;
VAL_ 409 TAS_uiHeightRL 63 "SNA" ;
VAL_ 409 TAS_uiHeightRR 63 "SNA" ;
VAL_ 410 TAS_bodyAccelFL 255 "SNA" ;
VAL_ 410 TAS_bodyAccelFR 255 "SNA" ;
VAL_ 410 TAS_bodyAccelRL 255 "SNA" ;
VAL_ 410 TAS_bodyAccelRR 255 "SNA" ;
VAL_ 538 TAS_adaptiveRideModeOverride 3 "TAS_ADAPTIVE_RIDE_MODE_SNA" 2 "TAS_ADAPTIVE_RIDE_MODE_SPORT" 1 "TAS_ADAPTIVE_RIDE_MODE_AUTO" 0 "TAS_ADAPTIVE_RIDE_MODE_COMFORT" ;
VAL_ 538 TAS_launchModeState 4 "TAS_LAUNCH_MODE_STATE_RAISE_SUSPENSION" 3 "TAS_LAUNCH_MODE_STATE_READY" 2 "TAS_LAUNCH_MODE_STATE_LOWER_SUSPENSION" 1 "TAS_LAUNCH_MODE_STATE_IDLE" 0 "TAS_LAUNCH_MODE_STATE_BLOCKED" ;
VAL_ 1657 UI_rgbEnableState 2 "AUTO" 1 "ON" 0 "OFF" ;
VAL_ 1657 UI_rgbEffectType 20 "RAMP_5000MS" 19 "RAMP_4750MS" 18 "RAMP_4500MS" 17 "RAMP_4250MS" 16 "RAMP_4000MS" 15 "RAMP_3750MS" 14 "RAMP_3500MS" 13 "RAMP_3250MS" 12 "RAMP_3000MS" 11 "RAMP_2750MS" 10 "RAMP_2500MS" 9 "RAMP_2250MS" 8 "RAMP_2000MS" 7 "RAMP_1750MS" 6 "RAMP_1500MS" 5 "RAMP_1250MS" 4 "RAMP_1000MS" 3 "RAMP_750MS" 2 "RAMP_500MS" 1 "RAMP_250MS" 0 "RAMP_INSTANT" ;
VAL_ 1657 UI_rgbBrightnessLevel 127 "SNA" ;
VAL_ 1021 UI_autopilotControlIndex 7 "7" 6 "6" 5 "5" 4 "4" 3 "3" 2 "2" 1 "1" 0 "0" ;
VAL_ 1021 UI_hovEnabled 1 "HOV_ON" 0 "HOV_OFF" ;
VAL_ 1021 UI_donDisableAutoWiperDuration 6 "OFF" 5 "120_S" 4 "60_S" 3 "30_S" 2 "15_S" 1 "5_S" 0 "DEFAULT" ;
VAL_ 1021 UI_donDisableOnAutoWiperSpeed 15 "INVALID" 14 "14" 13 "13" 12 "12" 11 "11" 10 "10" 9 "9" 8 "8" 7 "7" 6 "6" 5 "5" 4 "4" 3 "3" 2 "2" 1 "1" 0 "OFF" ;
VAL_ 1021 UI_blindspotMinSpeed 10 "OFF" 9 "45_KPH" 8 "40_KPH" 7 "35_KPH" 6 "30_KPH" 5 "25_KPH" 4 "20_KPH" 3 "15_KPH" 2 "10_KPH" 1 "5_KPH" 0 "DEFAULT" ;
VAL_ 1021 UI_blindspotDistance 5 "OFF" 4 "4_M" 3 "2_M" 2 "1_M" 1 "0P5_M" 0 "DEFAULT" ;
VAL_ 1021 UI_blindspotTTC 7 "OFF" 6 "5_S" 5 "3_S" 4 "4_S" 3 "2_S" 2 "1_S" 1 "0P5_S" 0 "DEFAULT" ;
VAL_ 1021 UI_donStopEndOfRampBuffer 4 "OFF" 3 "45_M" 2 "30_M" 1 "15_M" 0 "DEFAULT" ;
VAL_ 1021 UI_donDisableCutin 1 "ON" 0 "OFF" ;
VAL_ 1021 UI_smartSetSpeedOffsetType 1 "PERCENTAGE_OFFSET" 0 "FIXED_OFFSET" ;
VAL_ 1021 UI_homelinkNearby 1 "NEARBY" 0 "NOT_NEARBY" ;
VAL_ 1021 UI_autosteerActivation 1 "DOUBLE_CLICK" 0 "SINGLE_CLICK" ;
VAL_ 1021 UI_fsdBetaRequest 1 "FSD_REQUEST_ACTIVE" 0 "FSD_REQUEST_NOT_ACTIVE" ;
VAL_ 1021 UI_selectableCameraRequest 15 "SNA" 13 "REPEATERS_BACKUP" 12 "FASCIA" 11 "GRID_VIEW" 10 "OCTA" 9 "BACKUP" 8 "RIGHT_REPEATER" 7 "RIGHT_PILLAR" 6 "LEFT_REPEATER" 5 "LEFT_PILLAR" 4 "FRONT_NARROW" 3 "FRONT_FISHEYE" 2 "FRONT_MAIN" 1 "SELFIE" 0 "NONE" ;
VAL_ 1021 UI_overrideSleepWithSuspend 1 "ENABLED" 0 "DISABLED" ;
VAL_ 1021 UI_regulatoryLaneAssistLevel 1 "ASSIST" 0 "WARNING" ;
VAL_ 1021 UI_apmv3Branch 5 "DEMO" 4 "EAP" 3 "STAGE2" 2 "DEV" 1 "STAGE" 0 "LIVE" ;
VAL_ 1021 UI_autoTurnSignalMode 1 "UI_AUTO_TURN_SIGNAL_MODE_AUTO_CANCEL" 0 "UI_AUTO_TURN_SIGNAL_MODE_OFF" ;
VAL_ 1021 UI_autopilotDrivingProfile 4 "CONSERVATIVE" 3 "MAD_MAX" 2 "ASSERTIVE" 1 "NORMAL" 0 "CHILL" ;
VAL_ 819 UI_brickVLoggingRequest 1 "TRUE" 0 "FALSE" ;
VAL_ 819 UI_brickBalancingDisabled 1 "TRUE" 0 "FALSE" ;
VAL_ 819 UI_acChargeCurrentLimit 127 "SNA" ;
VAL_ 819 UI_chargePortLatchRequest 2 "UI_LATCH_REQUEST_DISENGAGE" 1 "UI_LATCH_REQUEST_ENGAGE" 0 "UI_LATCH_REQUEST_NONE" ;
VAL_ 819 UI_cpInletHeaterRequest 2 "HEATER_MANUAL_OVERRIDE" 1 "HEATER_AUTO" 0 "HEATER_OFF" ;
VAL_ 659 UI_steeringTuneRequest 2 "STEERING_TUNE_SPORT" 1 "STEERING_TUNE_STANDARD" 0 "STEERING_TUNE_COMFORT" ;
VAL_ 659 UI_tractionControlMode 7 "TC_SLIPPERY_SURFACE_SELECTED" 6 "TC_OFFROAD_ASSIST_SELECTED" 5 "TC_DYNO_MODE_SELECTED" 4 "TC_ROLLS_MODE_SELECTED" 3 "TC_DEV_MODE_2_SELECTED" 2 "TC_DEV_MODE_1_SELECTED" 1 "TC_SLIP_START_SELECTED" 0 "TC_NORMAL_SELECTED" ;
VAL_ 659 UI_parkBrakeRequest 3 "PARK_BRAKE_REQUEST_SNA" 1 "PARK_BRAKE_REQUEST_PRESSED" 0 "PARK_BRAKE_REQUEST_IDLE" ;
VAL_ 659 UI_winchModeRequest 3 "WINCH_MODE_DIALOGUE_OPEN" 2 "WINCH_MODE_EXIT" 1 "WINCH_MODE_ENTER" 0 "WINCH_MODE_IDLE" ;
VAL_ 659 UI_zeroSpeedConfirmed 3 "SNA" 2 "UNUSED" 1 "CONFIRMED" 0 "CANCELED" ;
VAL_ 659 UI_trailerMode 1 "TRAILER_MODE_ON" 0 "TRAILER_MODE_OFF" ;
VAL_ 659 UI_distanceUnits 1 "MILES" 0 "KM" ;
VAL_ 659 UI_accOvertakeEnable 3 "SNA" 1 "ACC_OVERTAKE_ON" 0 "ACC_OVERTAKE_OFF" ;
VAL_ 659 UI_aebEnable 3 "SNA" 1 "AEB_ON" 0 "AEB_OFF" ;
VAL_ 659 UI_aesEnable 3 "SNA" 1 "AES_ON" 0 "AES_OFF" ;
VAL_ 659 UI_ahlbEnable 3 "SNA" 1 "AHLB_ON" 0 "AHLB_OFF" ;
VAL_ 659 UI_autoLaneChangeEnable 3 "SNA" 1 "ON" 0 "OFF" ;
VAL_ 659 UI_autoParkRequest 15 "SNA" 12 "BEGIN_PARKING" 11 "RESUME" 10 "PAUSE" 9 "SEARCH" 8 "COMPLETE" 7 "ABORT" 6 "PARALLEL_PULL_OUT_TO_RIGHT" 5 "PARALLEL_PULL_OUT_TO_LEFT" 4 "PARK_RIGHT_CROSS" 3 "PARK_RIGHT_PARALLEL" 2 "PARK_LEFT_CROSS" 1 "PARK_LEFT_PARALLEL" 0 "NONE" ;
VAL_ 659 UI_bsdEnable 3 "SNA" 1 "BSD_ON" 0 "BSD_OFF" ;
VAL_ 659 UI_fcwEnable 3 "SNA" 1 "FCW_ON" 0 "FCW_OFF" ;
VAL_ 659 UI_fcwSensitivity 3 "SNA" 2 "AEB_SENSITIVITY_LATE" 1 "AEB_SENSITIVITY_AVERAGE" 0 "AEB_SENSITIVITY_EARLY" ;
VAL_ 659 UI_latControlEnable 3 "LATERAL_CONTROL_SNA" 2 "LATERAL_CONTROL_UNAVAILABLE" 1 "LATERAL_CONTROL_ON" 0 "LATERAL_CONTROL_OFF" ;
VAL_ 659 UI_ldwEnable 3 "SNA" 1 "LDW_TRIGGERS_HAPTIC" 0 "NO_HAPTIC" ;
VAL_ 659 UI_pedalSafetyEnable 3 "SNA" 1 "PEDAL_SAFETY_ON" 0 "PEDAL_SAFETY_OFF" ;
VAL_ 659 UI_pedalMap_epas 2 "PERFORMANCE" 1 "SPORT" 0 "CHILL" ;
VAL_ 659 UI_redLightStopSignEnable 3 "SNA" 1 "RLSSW_ON" 0 "RLSSW_OFF" ;
VAL_ 659 UI_selfParkTune 15 "SNA" ;
VAL_ 1280 UI_debugEcuTarget 21 "PMRE2" 20 "PMRE2L" 19 "PMRE1L" 18 "DIRE2" 17 "DIRE1R" 16 "DIRE1L" 15 "PMRER" 14 "PMREL" 13 "DIRER" 12 "DIREL" 11 "PMR" 10 "PMF" 9 "DIR" 8 "DIF" 7 "VCFRONT" 6 "VCRIGHT" 5 "BMS" 4 "PMS" 3 "PM" 2 "DIS" 1 "DI" ;
VAL_ 2043 UI_debugDampingRequestFLC 255 "SNA" ;
VAL_ 2043 UI_debugDampingRequestFLR 255 "SNA" ;
VAL_ 2043 UI_debugDampingRequestFRC 255 "SNA" ;
VAL_ 2043 UI_debugDampingRequestFRR 255 "SNA" ;
VAL_ 2043 UI_debugDampingRequestRLC 255 "SNA" ;
VAL_ 2043 UI_debugDampingRequestRLR 255 "SNA" ;
VAL_ 2043 UI_debugDampingRequestRRC 255 "SNA" ;
VAL_ 2043 UI_debugDampingRequestRRR 255 "SNA" ;
VAL_ 568 UI_mapSpeedLimitDependency 7 "SNA" 6 "LANE" 5 "SEASON" 4 "TIME" 3 "SNOW" 2 "RAIN" 1 "SCHOOL" 0 "NONE" ;
VAL_ 568 UI_roadClass 6 "CLASS_6_MINOR" 5 "CLASS_5" 4 "CLASS_4" 3 "CLASS_3" 2 "CLASS_2" 1 "CLASS_1_MAJOR" 0 "UNKNOWN_INVALID_SNA" ;
VAL_ 568 UI_mapSpeedUnits 1 "KPH" 0 "MPH" ;
VAL_ 568 UI_mapSpeedLimit 31 "SNA" 30 "UNLIMITED" 29 "LESS_OR_EQ_160" 28 "LESS_OR_EQ_150" 27 "LESS_OR_EQ_140" 26 "LESS_OR_EQ_130" 25 "LESS_OR_EQ_120" 24 "LESS_OR_EQ_115" 23 "LESS_OR_EQ_110" 22 "LESS_OR_EQ_105" 21 "LESS_OR_EQ_100" 20 "LESS_OR_EQ_95" 19 "LESS_OR_EQ_90" 18 "LESS_OR_EQ_85" 17 "LESS_OR_EQ_80" 16 "LESS_OR_EQ_75" 15 "LESS_OR_EQ_70" 14 "LESS_OR_EQ_65" 13 "LESS_OR_EQ_60" 12 "LESS_OR_EQ_55" 11 "LESS_OR_EQ_50" 10 "LESS_OR_EQ_45" 9 "LESS_OR_EQ_40" 8 "LESS_OR_EQ_35" 7 "LESS_OR_EQ_30" 6 "LESS_OR_EQ_25" 5 "LESS_OR_EQ_20" 4 "LESS_OR_EQ_15" 3 "LESS_OR_EQ_10" 2 "LESS_OR_EQ_7" 1 "LESS_OR_EQ_5" 0 "UNKNOWN" ;
VAL_ 568 UI_mapSpeedLimitType 7 "UNKNOWN_SNA" 4 "BUMPS" 3 "DEPENDENT" 2 "ADVISORY" 1 "REGULAR" ;
VAL_ 568 UI_countryCode 1023 "SNA" 0 "UNKNOWN" ;
VAL_ 568 UI_nextBranchDist 31 "SNA" ;
VAL_ 645 UI_driverProfileRecallIndex 5 "5" 4 "4" 3 "3" 2 "2" 1 "1" 0 "SNA" ;
VAL_ 645 UI_lumbarAPressurePercentage 127 "SNA" ;
VAL_ 645 UI_lumbarBPressurePercentage 127 "SNA" ;
VAL_ 645 UI_modifyMirrorDipRequest 2 "MODIFY_MIRROR_DIP_REQUEST_DIPPED" 1 "MODIFY_MIRROR_DIP_REQUEST_UNDIPPED" 0 "MODIFY_MIRROR_DIP_REQUEST_NONE" ;
VAL_ 651 UI_driverProfileLinkedKeySHA1 4294967295 "SNA" ;
VAL_ 651 UI_driverProfileSelectionType 3 "DRIVER_PROFILE_SELECTION_TYPE_NONE" 2 "DRIVER_PROFILE_SELECTION_TYPE_AUTOMATIC_NO_OP" 1 "DRIVER_PROFILE_SELECTION_TYPE_AUTOMATIC_RESTORE" 0 "DRIVER_PROFILE_SELECTION_TYPE_MANUAL" ;
VAL_ 984 UI_elevation 8191 "SNA" ;
VAL_ 984 UI_navElevation 8191 "SNA" ;
VAL_ 1139 UI_nmKeepAwakeReason 52 "UI_KEEPAWAKE_REASON_UNSPECIFIED" 51 "UI_KEEPAWAKE_REASON_MANUAL_REQUEST" 50 "UI_KEEPAWAKE_REASON_PLB" 49 "UI_KEEPAWAKE_REASON_PM_WAKE_DEBOUNCE" 48 "UI_KEEPAWAKE_REASON_FLASH_ROM" 47 "UI_KEEPAWAKE_REASON_SET_CLIMATE_KEEPER_MODE" 46 "UI_KEEPAWAKE_REASON_CHARGE_STOP" 45 "UI_KEEPAWAKE_REASON_CHARGE_START" 44 "UI_KEEPAWAKE_REASON_CHARGE_PORT_DOOR_OPEN" 43 "UI_KEEPAWAKE_REASON_SET_VALET_MODE" 42 "UI_KEEPAWAKE_REASON_SET_SENTRY_MODE" 41 "UI_KEEPAWAKE_REASON_ACTUATE_TRUNK" 40 "UI_KEEPAWAKE_REASON_REMOTE_START_DRIVE" 39 "UI_KEEPAWAKE_REASON_SET_CHARGE_LIMIT" 38 "UI_KEEPAWAKE_REASON_FLASH_LIGHTS" 37 "UI_KEEPAWAKE_REASON_SET_TEMPS" 36 "UI_KEEPAWAKE_REASON_ACC_POWER_ON" 35 "UI_KEEPAWAKE_REASON_DOOR_LOCK" 34 "UI_KEEPAWAKE_REASON_DOOR_UNLOCK" 33 "UI_KEEPAWAKE_REASON_MOTHERSHIP_SMS_FLEET_WAKE_UP" 32 "UI_KEEPAWAKE_REASON_SET_VEHICLE_CONFIGURATION" 31 "UI_KEEPAWAKE_REASON_AUTO_CONDITIONING_START" 30 "UI_KEEPAWAKE_REASON_WINDOW_CONTROL" 29 "UI_KEEPAWAKE_REASON_GET_VEHICLE_CONFIGURATION" 28 "UI_KEEPAWAKE_REASON_MOTHERSHIP_SMS_OWNER_WAKE_UP" 27 "UI_KEEPAWAKE_REASON_MOTHERSHIP_SMS_GARAGE_WAKE_UP" 26 "UI_KEEPAWAKE_REASON_MOTHERSHIP_SMS_VEHICLE_TASK" 25 "UI_KEEPAWAKE_REASON_MOTHERSHIP_SMS_YOUVE_GOT_MAIL" 24 "UI_KEEPAWAKE_REASON_WAKE_UP" 23 "UI_KEEPAWAKE_REASON_FIRMWARE_HANDSHAKE" 22 "UI_KEEPAWAKE_REASON_VEHICLE_DATA" 21 "UI_KEEPAWAKE_REASON_DIAG_VITALS" 20 "UI_KEEPAWAKE_REASON_URGENT_UPLOAD" 19 "UI_KEEPAWAKE_REASON_UI_REQUEST_AP_KEEPALIVE" 18 "UI_KEEPAWAKE_REASON_STEAM" 17 "UI_KEEPAWAKE_REASON_CHARGING" 16 "UI_KEEPAWAKE_REASON_UI_HVAC_REQUEST" 15 "UI_KEEPAWAKE_REASON_USER_NOTIFICATION_TIMER" 14 "UI_KEEPAWAKE_REASON_ODIN" 13 "UI_KEEPAWAKE_REASON_MEDIA_DOWNLOAD" 12 "UI_KEEPAWAKE_REASON_SENTRY_MODE" 11 "UI_KEEPAWAKE_REASON_SELFTEST" 10 "UI_KEEPAWAKE_REASON_ECALL_ACTIVE" 9 "UI_KEEPAWAKE_REASON_UPDATE_COUNTDOWN" 8 "UI_KEEPAWAKE_REASON_AUTOFUSER" 7 "UI_KEEPAWAKE_REASON_HERMES" 6 "UI_KEEPAWAKE_REASON_UPDATER" 5 "UI_KEEPAWAKE_REASON_MODEM_RESET" 4 "UI_KEEPAWAKE_REASON_UNKNOWN_REMOTE_REQUEST" 3 "UI_KEEPAWAKE_REASON_PM_CHECKING" 2 "UI_KEEPAWAKE_REASON_GUI_NEVER_SLEEP_SET" 1 "UI_KEEPAWAKE_REASON_KEEPALIVEACTIVE" 0 "UI_KEEPAWAKE_REASON_NONE_SNA" ;
VAL_ 1267 UI_seatAdjustmentSource 5 "PROFILE_CREATION" 4 "QUICK_CONTROLS" 3 "MFC" 2 "BOTTOM_BAR_PASSENGER" 1 "BOTTOM_BAR_DRIVER" 0 "INACTIVE" ;
VAL_ 883 UI_mapSpeedLimitUnits 1 "KPH" 0 "MPH" ;
VAL_ 883 UI_userSpeedOffsetUnits 1 "KPH" 0 "MPH" ;
VAL_ 883 UI_conditionalSpeedLimit 31 "SNA" ;
VAL_ 912 UI_powershareRequest 2 "POWERSHARE_REQUEST_AUTHENTICATED" 1 "POWERSHARE_REQUEST_STANDARD_VEHICLE" 0 "POWERSHARE_REQUEST_DISABLE" ;
VAL_ 755 UI_hvacReqTempSetpointLeft 26 "HI" 0 "LO" ;
VAL_ 755 UI_hvacReqAutoBlowerLevel 4 "VERY_HIGH" 3 "HIGH" 2 "MEDIUM" 1 "LOW" 0 "VERY_LOW" ;
VAL_ 755 UI_hvacReqTempSetpointRight 26 "HI" 0 "LO" ;
VAL_ 755 UI_hvacReqAirDistributionMode 7 "MANUAL_DEFROST_PANEL_FLOOR" 6 "MANUAL_DEFROST_PANEL" 5 "MANUAL_DEFROST_FLOOR" 4 "MANUAL_DEFROST" 3 "MANUAL_PANEL_FLOOR" 2 "MANUAL_PANEL" 1 "MANUAL_FLOOR" 0 "AUTO" ;
VAL_ 755 UI_hvacReqBlowerSegment 11 "AUTO" 10 "10" 9 "9" 8 "8" 7 "7" 6 "6" 5 "5" 4 "4" 3 "3" 2 "2" 1 "1" 0 "OFF" ;
VAL_ 755 UI_hvacReqRecirc 2 "FRESH" 1 "RECIRC" 0 "AUTO" ;
VAL_ 755 UI_hvacReqACDisable 2 "ON" 1 "OFF" 0 "AUTO" ;
VAL_ 755 UI_hvacDefogState 3 "AUTO_DEFOG" 2 "DEFROST" 1 "DEFOG" 0 "NONE" ;
VAL_ 755 UI_hvacReqUserPowerState 4 "OVERHEAT_PROTECT" 3 "OVERHEAT_PROTECT_FANONLY" 2 "PRECONDITION" 1 "ON" 0 "OFF" ;
VAL_ 755 UI_hvacReqSecondRowState 4 "HIGH" 3 "MED" 2 "LOW" 1 "OFF" 0 "AUTO" ;
VAL_ 755 UI_hvacReqKeepClimateOn 3 "KEEP_CLIMATE_ON_REQ_PARTY" 2 "KEEP_CLIMATE_ON_REQ_DOG" 1 "KEEP_CLIMATE_ON_REQ_ON" 0 "KEEP_CLIMATE_ON_REQ_OFF" ;
VAL_ 755 UI_hvacReqTempSetpointCOP 2 "HIGH" 1 "MEDIUM" 0 "LOW" ;
VAL_ 755 UI_hvacClimateNudgeStatus 4 "CLOSED_WITH_EXTERIOR_NUDGE" 3 "OPEN_WITH_NUDGE" 2 "OPEN_NO_NUDGE" 1 "CLOSED_WITH_NUDGE" 0 "CLOSED_NO_NUDGE" ;
VAL_ 777 UI_gpsAccuracy 127 "SNA" ;
VAL_ 1523 UI_odometer 16777215 "SNA" ;
VAL_ 948 UI_usbFrontHubPowerStateRequest 2 "POWER_ON" 1 "POWER_NO_PREFERENCE" 0 "POWER_REQUEST_SNA" ;
VAL_ 827 UI_chargeTimeUntilTerminationPct 2047 "SNA" 1440 "MAXVAL" ;
VAL_ 827 UI_chargeTimeUntilReadyToDepart 2047 "SNA" 1440 "MAXVAL" ;
VAL_ 661 UI_powerRationalityConfigIndex 255 "INVALID" 11 "VCRIGHT_DYNAMIC_CURVE_CUTOFF_CONFIG" 10 "VCRIGHT_STATIC_CURVE_CUTOFF_CONFIG" 9 "VCRIGHT_FAST_BLOW_CUTOFF_CONFIG" 8 "VCLEFT_DYNAMIC_CURVE_CUTOFF_CONFIG" 7 "VCLEFT_STATIC_CURVE_CUTOFF_CONFIG" 6 "VCLEFT_FAST_BLOW_CUTOFF_CONFIG" 5 "VCRIGHT_DYNAMIC_CURVE_CONFIG" 4 "VCRIGHT_STATIC_CURVE_CONFIG" 3 "VCRIGHT_FAST_BLOW_CONFIG" 2 "VCLEFT_DYNAMIC_CURVE_CONFIG" 1 "VCLEFT_STATIC_CURVE_CONFIG" 0 "VCLEFT_FAST_BLOW_CONFIG" ;
VAL_ 661 UI_vcleftCfgRationalityThreshold 15 "VC_THRESHOLD_CONFIG_15" 14 "VC_THRESHOLD_CONFIG_14" 13 "VC_THRESHOLD_CONFIG_13" 12 "VC_THRESHOLD_CONFIG_12" 11 "VC_THRESHOLD_CONFIG_11" 10 "VC_THRESHOLD_CONFIG_10" 9 "VC_THRESHOLD_CONFIG_9" 8 "VC_THRESHOLD_CONFIG_8" 7 "VC_THRESHOLD_CONFIG_7" 6 "VC_THRESHOLD_CONFIG_6" 5 "VC_THRESHOLD_CONFIG_5" 4 "VC_THRESHOLD_CONFIG_4" 3 "VC_THRESHOLD_CONFIG_3" 2 "VC_THRESHOLD_CONFIG_2" 1 "VC_THRESHOLD_CONFIG_1" 0 "SNA" ;
VAL_ 661 UI_vcleftCfgRationalityTime0 15 "VC_THRESHOLD_CONFIG_15" 14 "VC_THRESHOLD_CONFIG_14" 13 "VC_THRESHOLD_CONFIG_13" 12 "VC_THRESHOLD_CONFIG_12" 11 "VC_THRESHOLD_CONFIG_11" 10 "VC_THRESHOLD_CONFIG_10" 9 "VC_THRESHOLD_CONFIG_9" 8 "VC_THRESHOLD_CONFIG_8" 7 "VC_THRESHOLD_CONFIG_7" 6 "VC_THRESHOLD_CONFIG_6" 5 "VC_THRESHOLD_CONFIG_5" 4 "VC_THRESHOLD_CONFIG_4" 3 "VC_THRESHOLD_CONFIG_3" 2 "VC_THRESHOLD_CONFIG_2" 1 "VC_THRESHOLD_CONFIG_1" 0 "SNA" ;
VAL_ 661 UI_vcleftCfgRationalityThre_0001 15 "VC_THRESHOLD_CONFIG_15" 14 "VC_THRESHOLD_CONFIG_14" 13 "VC_THRESHOLD_CONFIG_13" 12 "VC_THRESHOLD_CONFIG_12" 11 "VC_THRESHOLD_CONFIG_11" 10 "VC_THRESHOLD_CONFIG_10" 9 "VC_THRESHOLD_CONFIG_9" 8 "VC_THRESHOLD_CONFIG_8" 7 "VC_THRESHOLD_CONFIG_7" 6 "VC_THRESHOLD_CONFIG_6" 5 "VC_THRESHOLD_CONFIG_5" 4 "VC_THRESHOLD_CONFIG_4" 3 "VC_THRESHOLD_CONFIG_3" 2 "VC_THRESHOLD_CONFIG_2" 1 "VC_THRESHOLD_CONFIG_1" 0 "SNA" ;
VAL_ 661 UI_vcleftCfgRationalityTime1 15 "VC_THRESHOLD_CONFIG_15" 14 "VC_THRESHOLD_CONFIG_14" 13 "VC_THRESHOLD_CONFIG_13" 12 "VC_THRESHOLD_CONFIG_12" 11 "VC_THRESHOLD_CONFIG_11" 10 "VC_THRESHOLD_CONFIG_10" 9 "VC_THRESHOLD_CONFIG_9" 8 "VC_THRESHOLD_CONFIG_8" 7 "VC_THRESHOLD_CONFIG_7" 6 "VC_THRESHOLD_CONFIG_6" 5 "VC_THRESHOLD_CONFIG_5" 4 "VC_THRESHOLD_CONFIG_4" 3 "VC_THRESHOLD_CONFIG_3" 2 "VC_THRESHOLD_CONFIG_2" 1 "VC_THRESHOLD_CONFIG_1" 0 "SNA" ;
VAL_ 661 UI_vcleftCfgRationalityStaticA 65535 "SNA" ;
VAL_ 661 UI_vcleftCfgRationalityStaticB -32768 "SNA" ;
VAL_ 661 UI_vcleftCfgRationalityStaticC -32768 "SNA" ;
VAL_ 661 UI_vcleftCfgRationalityDynamicA 65535 "SNA" ;
VAL_ 661 UI_vcleftCfgRationalityDynamicB -32768 "SNA" ;
VAL_ 661 UI_vcleftCfgRationalityDynamicC -32768 "SNA" ;
VAL_ 661 UI_vcrightCfgRationalityThreshol 15 "VC_THRESHOLD_CONFIG_15" 14 "VC_THRESHOLD_CONFIG_14" 13 "VC_THRESHOLD_CONFIG_13" 12 "VC_THRESHOLD_CONFIG_12" 11 "VC_THRESHOLD_CONFIG_11" 10 "VC_THRESHOLD_CONFIG_10" 9 "VC_THRESHOLD_CONFIG_9" 8 "VC_THRESHOLD_CONFIG_8" 7 "VC_THRESHOLD_CONFIG_7" 6 "VC_THRESHOLD_CONFIG_6" 5 "VC_THRESHOLD_CONFIG_5" 4 "VC_THRESHOLD_CONFIG_4" 3 "VC_THRESHOLD_CONFIG_3" 2 "VC_THRESHOLD_CONFIG_2" 1 "VC_THRESHOLD_CONFIG_1" 0 "SNA" ;
VAL_ 661 UI_vcrightCfgRationalityTime0 15 "VC_THRESHOLD_CONFIG_15" 14 "VC_THRESHOLD_CONFIG_14" 13 "VC_THRESHOLD_CONFIG_13" 12 "VC_THRESHOLD_CONFIG_12" 11 "VC_THRESHOLD_CONFIG_11" 10 "VC_THRESHOLD_CONFIG_10" 9 "VC_THRESHOLD_CONFIG_9" 8 "VC_THRESHOLD_CONFIG_8" 7 "VC_THRESHOLD_CONFIG_7" 6 "VC_THRESHOLD_CONFIG_6" 5 "VC_THRESHOLD_CONFIG_5" 4 "VC_THRESHOLD_CONFIG_4" 3 "VC_THRESHOLD_CONFIG_3" 2 "VC_THRESHOLD_CONFIG_2" 1 "VC_THRESHOLD_CONFIG_1" 0 "SNA" ;
VAL_ 661 UI_vcrightCfgRationalityThr_0001 15 "VC_THRESHOLD_CONFIG_15" 14 "VC_THRESHOLD_CONFIG_14" 13 "VC_THRESHOLD_CONFIG_13" 12 "VC_THRESHOLD_CONFIG_12" 11 "VC_THRESHOLD_CONFIG_11" 10 "VC_THRESHOLD_CONFIG_10" 9 "VC_THRESHOLD_CONFIG_9" 8 "VC_THRESHOLD_CONFIG_8" 7 "VC_THRESHOLD_CONFIG_7" 6 "VC_THRESHOLD_CONFIG_6" 5 "VC_THRESHOLD_CONFIG_5" 4 "VC_THRESHOLD_CONFIG_4" 3 "VC_THRESHOLD_CONFIG_3" 2 "VC_THRESHOLD_CONFIG_2" 1 "VC_THRESHOLD_CONFIG_1" 0 "SNA" ;
VAL_ 661 UI_vcrightCfgRationalityTime1 15 "VC_THRESHOLD_CONFIG_15" 14 "VC_THRESHOLD_CONFIG_14" 13 "VC_THRESHOLD_CONFIG_13" 12 "VC_THRESHOLD_CONFIG_12" 11 "VC_THRESHOLD_CONFIG_11" 10 "VC_THRESHOLD_CONFIG_10" 9 "VC_THRESHOLD_CONFIG_9" 8 "VC_THRESHOLD_CONFIG_8" 7 "VC_THRESHOLD_CONFIG_7" 6 "VC_THRESHOLD_CONFIG_6" 5 "VC_THRESHOLD_CONFIG_5" 4 "VC_THRESHOLD_CONFIG_4" 3 "VC_THRESHOLD_CONFIG_3" 2 "VC_THRESHOLD_CONFIG_2" 1 "VC_THRESHOLD_CONFIG_1" 0 "SNA" ;
VAL_ 661 UI_vcrightCfgRationalityStaticA 65535 "SNA" ;
VAL_ 661 UI_vcrightCfgRationalityStaticB -32768 "SNA" ;
VAL_ 661 UI_vcrightCfgRationalityStaticC -32768 "SNA" ;
VAL_ 661 UI_vcrightCfgRationalityDynamicA 65535 "SNA" ;
VAL_ 661 UI_vcrightCfgRationalityDynamicB -32768 "SNA" ;
VAL_ 661 UI_vcrightCfgRationalityDynamicC -32768 "SNA" ;
VAL_ 661 UI_vcleftCfgCutoffThreshold0 15 "VC_THRESHOLD_CONFIG_15" 14 "VC_THRESHOLD_CONFIG_14" 13 "VC_THRESHOLD_CONFIG_13" 12 "VC_THRESHOLD_CONFIG_12" 11 "VC_THRESHOLD_CONFIG_11" 10 "VC_THRESHOLD_CONFIG_10" 9 "VC_THRESHOLD_CONFIG_9" 8 "VC_THRESHOLD_CONFIG_8" 7 "VC_THRESHOLD_CONFIG_7" 6 "VC_THRESHOLD_CONFIG_6" 5 "VC_THRESHOLD_CONFIG_5" 4 "VC_THRESHOLD_CONFIG_4" 3 "VC_THRESHOLD_CONFIG_3" 2 "VC_THRESHOLD_CONFIG_2" 1 "VC_THRESHOLD_CONFIG_1" 0 "SNA" ;
VAL_ 661 UI_vcleftCfgCutoffTime0 15 "VC_THRESHOLD_CONFIG_15" 14 "VC_THRESHOLD_CONFIG_14" 13 "VC_THRESHOLD_CONFIG_13" 12 "VC_THRESHOLD_CONFIG_12" 11 "VC_THRESHOLD_CONFIG_11" 10 "VC_THRESHOLD_CONFIG_10" 9 "VC_THRESHOLD_CONFIG_9" 8 "VC_THRESHOLD_CONFIG_8" 7 "VC_THRESHOLD_CONFIG_7" 6 "VC_THRESHOLD_CONFIG_6" 5 "VC_THRESHOLD_CONFIG_5" 4 "VC_THRESHOLD_CONFIG_4" 3 "VC_THRESHOLD_CONFIG_3" 2 "VC_THRESHOLD_CONFIG_2" 1 "VC_THRESHOLD_CONFIG_1" 0 "SNA" ;
VAL_ 661 UI_vcleftCfgCutoffThreshold1 15 "VC_THRESHOLD_CONFIG_15" 14 "VC_THRESHOLD_CONFIG_14" 13 "VC_THRESHOLD_CONFIG_13" 12 "VC_THRESHOLD_CONFIG_12" 11 "VC_THRESHOLD_CONFIG_11" 10 "VC_THRESHOLD_CONFIG_10" 9 "VC_THRESHOLD_CONFIG_9" 8 "VC_THRESHOLD_CONFIG_8" 7 "VC_THRESHOLD_CONFIG_7" 6 "VC_THRESHOLD_CONFIG_6" 5 "VC_THRESHOLD_CONFIG_5" 4 "VC_THRESHOLD_CONFIG_4" 3 "VC_THRESHOLD_CONFIG_3" 2 "VC_THRESHOLD_CONFIG_2" 1 "VC_THRESHOLD_CONFIG_1" 0 "SNA" ;
VAL_ 661 UI_vcleftCfgCutoffTime1 15 "VC_THRESHOLD_CONFIG_15" 14 "VC_THRESHOLD_CONFIG_14" 13 "VC_THRESHOLD_CONFIG_13" 12 "VC_THRESHOLD_CONFIG_12" 11 "VC_THRESHOLD_CONFIG_11" 10 "VC_THRESHOLD_CONFIG_10" 9 "VC_THRESHOLD_CONFIG_9" 8 "VC_THRESHOLD_CONFIG_8" 7 "VC_THRESHOLD_CONFIG_7" 6 "VC_THRESHOLD_CONFIG_6" 5 "VC_THRESHOLD_CONFIG_5" 4 "VC_THRESHOLD_CONFIG_4" 3 "VC_THRESHOLD_CONFIG_3" 2 "VC_THRESHOLD_CONFIG_2" 1 "VC_THRESHOLD_CONFIG_1" 0 "SNA" ;
VAL_ 661 UI_vcleftCfgCutoffStaticA 65535 "SNA" ;
VAL_ 661 UI_vcleftCfgCutoffStaticB -32768 "SNA" ;
VAL_ 661 UI_vcleftCfgCutoffStaticC -32768 "SNA" ;
VAL_ 661 UI_vcleftCfgCutoffDynamicA 65535 "SNA" ;
VAL_ 661 UI_vcleftCfgCutoffDynamicB -32768 "SNA" ;
VAL_ 661 UI_vcleftCfgCutoffDynamicC -32768 "SNA" ;
VAL_ 661 UI_vcrightCfgCutoffThreshold0 15 "VC_THRESHOLD_CONFIG_15" 14 "VC_THRESHOLD_CONFIG_14" 13 "VC_THRESHOLD_CONFIG_13" 12 "VC_THRESHOLD_CONFIG_12" 11 "VC_THRESHOLD_CONFIG_11" 10 "VC_THRESHOLD_CONFIG_10" 9 "VC_THRESHOLD_CONFIG_9" 8 "VC_THRESHOLD_CONFIG_8" 7 "VC_THRESHOLD_CONFIG_7" 6 "VC_THRESHOLD_CONFIG_6" 5 "VC_THRESHOLD_CONFIG_5" 4 "VC_THRESHOLD_CONFIG_4" 3 "VC_THRESHOLD_CONFIG_3" 2 "VC_THRESHOLD_CONFIG_2" 1 "VC_THRESHOLD_CONFIG_1" 0 "SNA" ;
VAL_ 661 UI_vcrightCfgCutoffTime0 15 "VC_THRESHOLD_CONFIG_15" 14 "VC_THRESHOLD_CONFIG_14" 13 "VC_THRESHOLD_CONFIG_13" 12 "VC_THRESHOLD_CONFIG_12" 11 "VC_THRESHOLD_CONFIG_11" 10 "VC_THRESHOLD_CONFIG_10" 9 "VC_THRESHOLD_CONFIG_9" 8 "VC_THRESHOLD_CONFIG_8" 7 "VC_THRESHOLD_CONFIG_7" 6 "VC_THRESHOLD_CONFIG_6" 5 "VC_THRESHOLD_CONFIG_5" 4 "VC_THRESHOLD_CONFIG_4" 3 "VC_THRESHOLD_CONFIG_3" 2 "VC_THRESHOLD_CONFIG_2" 1 "VC_THRESHOLD_CONFIG_1" 0 "SNA" ;
VAL_ 661 UI_vcrightCfgCutoffThreshold1 15 "VC_THRESHOLD_CONFIG_15" 14 "VC_THRESHOLD_CONFIG_14" 13 "VC_THRESHOLD_CONFIG_13" 12 "VC_THRESHOLD_CONFIG_12" 11 "VC_THRESHOLD_CONFIG_11" 10 "VC_THRESHOLD_CONFIG_10" 9 "VC_THRESHOLD_CONFIG_9" 8 "VC_THRESHOLD_CONFIG_8" 7 "VC_THRESHOLD_CONFIG_7" 6 "VC_THRESHOLD_CONFIG_6" 5 "VC_THRESHOLD_CONFIG_5" 4 "VC_THRESHOLD_CONFIG_4" 3 "VC_THRESHOLD_CONFIG_3" 2 "VC_THRESHOLD_CONFIG_2" 1 "VC_THRESHOLD_CONFIG_1" 0 "SNA" ;
VAL_ 661 UI_vcrightCfgCutoffTime1 15 "VC_THRESHOLD_CONFIG_15" 14 "VC_THRESHOLD_CONFIG_14" 13 "VC_THRESHOLD_CONFIG_13" 12 "VC_THRESHOLD_CONFIG_12" 11 "VC_THRESHOLD_CONFIG_11" 10 "VC_THRESHOLD_CONFIG_10" 9 "VC_THRESHOLD_CONFIG_9" 8 "VC_THRESHOLD_CONFIG_8" 7 "VC_THRESHOLD_CONFIG_7" 6 "VC_THRESHOLD_CONFIG_6" 5 "VC_THRESHOLD_CONFIG_5" 4 "VC_THRESHOLD_CONFIG_4" 3 "VC_THRESHOLD_CONFIG_3" 2 "VC_THRESHOLD_CONFIG_2" 1 "VC_THRESHOLD_CONFIG_1" 0 "SNA" ;
VAL_ 661 UI_vcrightCfgCutoffStaticA 65535 "SNA" ;
VAL_ 661 UI_vcrightCfgCutoffStaticB -32768 "SNA" ;
VAL_ 661 UI_vcrightCfgCutoffStaticC -32768 "SNA" ;
VAL_ 661 UI_vcrightCfgCutoffDynamicA 65535 "SNA" ;
VAL_ 661 UI_vcrightCfgCutoffDynamicB -32768 "SNA" ;
VAL_ 661 UI_vcrightCfgCutoffDynamicC -32768 "SNA" ;
VAL_ 820 UI_systemPowerLimit 31 "SNA" ;
VAL_ 820 UI_pedalMap 2 "PERFORMANCE" 1 "SPORT" 0 "CHILL" ;
VAL_ 820 UI_systemTorqueLimit 63 "SNA" ;
VAL_ 820 UI_closureConfirmed 3 "TRUNK" 2 "PROX" 1 "FRUNK" 0 "NONE" ;
VAL_ 820 UI_limitMode 3 "LIMIT_SERVICE" 2 "LIMIT_FACTORY" 1 "LIMIT_VALET" 0 "LIMIT_NORMAL" ;
VAL_ 820 UI_motorOnMode 2 "MOTORONMODE_REAR_ONLY" 1 "MOTORONMODE_FRONT_ONLY" 0 "MOTORONMODE_NORMAL" ;
VAL_ 820 UI_stoppingMode 2 "HOLD" 1 "CREEP" 0 "STANDARD" ;
VAL_ 820 UI_speedLimit 511 "SNA" ;
VAL_ 820 UI_enableSmartShift 2 "ENABLED_P_R_D" 1 "ENABLED_P" 0 "OFF" ;
VAL_ 820 UI_navVehParallelToRdCanContinue 2 "TRUE" 1 "FALSE" 0 "SNA" ;
VAL_ 723 UI_solarAzimuthAngle -32768 "SNA" ;
VAL_ 723 UI_solarAzimuthAngleCarRef 255 "SNA" ;
VAL_ 723 UI_isSunUp 3 "SUN_SNA" 1 "SUN_UP" 0 "SUN_DOWN" ;
VAL_ 723 UI_solarElevationAngle 127 "SNA" ;
